VERSION "HNNBNNNYNNNNNNNNNNNNNNNNNNNNNNNNNNNNNNNNNN/4/%%%/4/'%**4NNN///"

NS_ :

BS_:

BU_: BAP_Tester BCM1 Gateway Klima_MSB Lift_VA VAS_L VAS_R

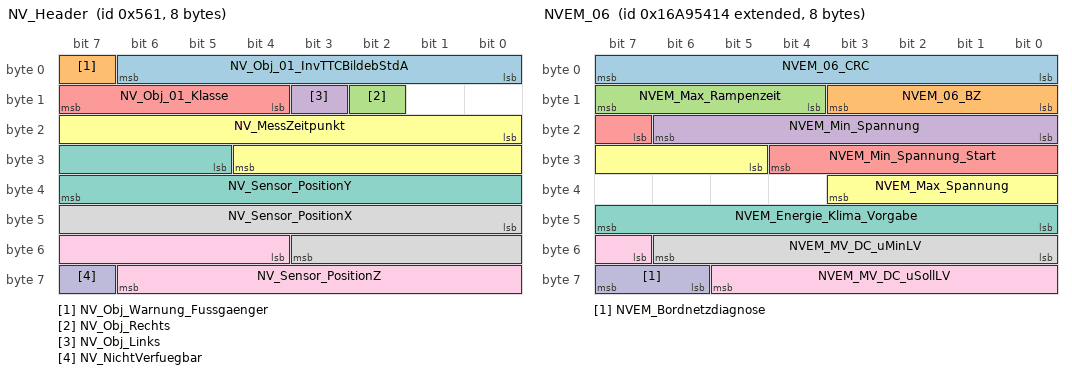
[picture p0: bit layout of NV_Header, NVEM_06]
BO_ 1377 NV_Header: 8 Gateway
 SG_ NV_Obj_01_InvTTCBildebStdA : 0|7@1+ (0.0625,0) [0.0000|7.8750] "Unit_Hertz"  Vector__XXX
 SG_ NV_Obj_Warnung_Fussgaenger : 7|1@1+ (1.0,0.0) [0.0|1] ""  Vector__XXX
 SG_ NV_Obj_Rechts : 10|1@1+ (1.0,0.0) [0.0|1] ""  BCM1
 SG_ NV_Obj_Links : 11|1@1+ (1.0,0.0) [0.0|1] ""  BCM1
 SG_ NV_Obj_01_Klasse : 12|4@1+ (1.0,0.0) [0.0|15] ""  BCM1
 SG_ NV_MessZeitpunkt : 16|13@1+ (0.001,0) [0.000|8.190] "Unit_Secon"  Vector__XXX
 SG_ NV_Sensor_PositionY : 29|11@1+ (0.001,-1) [-1.000|1.046] "Unit_Meter"  Vector__XXX
 SG_ NV_Sensor_PositionX : 40|12@1+ (0.001,1) [1.000|5.094] "Unit_Meter"  Vector__XXX
 SG_ NV_Sensor_PositionZ : 52|11@1+ (0.001,0) [0.000|2.046] "Unit_Meter"  Vector__XXX
 SG_ NV_NichtVerfuegbar : 63|1@1+ (1.0,0.0) [0.0|1] ""  Vector__XXX

BO_ 1635 NVEM_02: 8 Gateway
 SG_ BEM_02_Abschaltstufen : 0|3@1+ (1.0,0.0) [0.0|7] ""  BCM1,Klima_MSB
 SG_ BEM_STH_Zielzeit : 3|4@1+ (5,0) [0|60] "Unit_Minut"  BCM1,Klima_MSB
 SG_ BEM_MMI_Vorwarnung : 7|1@1+ (1.0,0.0) [0.0|1] ""  Vector__XXX
 SG_ NVEM_Anf_SD_schalten : 15|1@1+ (1.0,0.0) [0.0|1] ""  BCM1
 SG_ BEM_Generatordiagnose : 16|2@1+ (1.0,0.0) [0.0|3] ""  Vector__XXX
 SG_ BEM_Red_Innengeblaese : 18|2@1+ (1.0,0.0) [0.0|3] ""  BCM1,Klima_MSB
 SG_ BEM_STH_Einschaltverbot : 20|1@1+ (1.0,0.0) [0.0|1] ""  BCM1,Klima_MSB
 SG_ BEM_HL_Regelung_Status : 21|3@1+ (1.0,0.0) [0.0|7] ""  BCM1,Klima_MSB,Lift_VA
 SG_ BEM_Ladezustand : 24|4@1+ (10,0) [0|100] "Unit_PerCent"  Vector__XXX
 SG_ BEM_Batteriediagnose : 28|3@1+ (1.0,0.0) [0.0|7] ""  Vector__XXX
 SG_ MIB_Stromsparmodus : 31|1@1+ (1.0,0.0) [0.0|1] ""  Vector__XXX
 SG_ BEM_REK_aktiv : 37|1@1+ (1.0,0.0) [0.0|1] ""  Vector__XXX
 SG_ NVEM_Last_Anf : 38|2@1+ (1.0,0.0) [0.0|3] ""  Vector__XXX
 SG_ BEM_UBDM : 40|8@1+ (0.05,5) [5.05|17.70] "Unit_Volt"  Klima_MSB
 SG_ BEM_UGenSoll : 48|6@1+ (0.1,10.6) [10.6|16.0] "Unit_Volt"  Vector__XXX
 SG_ BEM_Anf_KL15_schalten : 54|2@1+ (1.0,0.0) [0.0|3] ""  Vector__XXX
 SG_ NVEM_Batterie_Service : 56|2@1+ (1.0,0.0) [0.0|3] ""  Vector__XXX
 SG_ NVEM_Freigabe_OnlineUpdate : 58|1@1+ (1.0,0.0) [0.0|1] ""  Vector__XXX
 SG_ NVEM_Freigabe_ORU4 : 59|2@1+ (1.0,0.0) [0.0|3] ""  Vector__XXX

BO_ 2527679508 NVEM_06: 8 Gateway
 SG_ NVEM_06_CRC : 0|8@1+ (1,0) [0|255] ""  Vector__XXX
 SG_ NVEM_06_BZ : 8|4@1+ (1,0) [0|15] ""  Vector__XXX
 SG_ NVEM_Max_Rampenzeit : 12|4@1+ (1.0,0.0) [0.0|15] ""  Vector__XXX
 SG_ NVEM_Min_Spannung : 16|7@1+ (0.05,10.6) [10.60|16.00] "Unit_Volt"  Vector__XXX
 SG_ NVEM_Min_Spannung_Start : 23|6@1+ (0.1,7) [7.0|13.1] "Unit_Volt"  Vector__XXX
 SG_ NVEM_Max_Spannung : 29|7@1+ (0.05,10.6) [10.60|16.00] "Unit_Volt"  Vector__XXX
 SG_ NVEM_Energie_Klima_Vorgabe : 40|8@1+ (10,0) [0|2530] "Unit_WattHour"  BCM1,Klima_MSB
 SG_ NVEM_MV_DC_uMinLV : 48|7@1+ (0.1,3.5) [3.5|16.0] "Unit_Volt"  Vector__XXX
 SG_ NVEM_MV_DC_uSollLV : 55|7@1+ (0.05,10.6) [10.60|16.00] "Unit_Volt"  Vector__XXX
 SG_ NVEM_Bordnetzdiagnose : 62|2@1+ (1.0,0.0) [0.0|3] ""  Vector__XXX

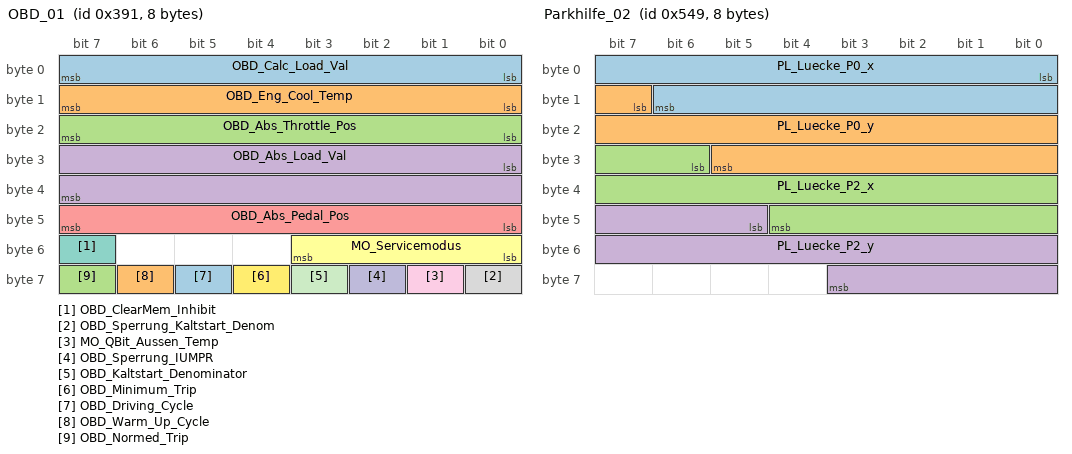
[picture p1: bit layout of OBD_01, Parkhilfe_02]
BO_ 913 OBD_01: 8 Gateway
 SG_ OBD_Calc_Load_Val : 0|8@1+ (0.39215686274509803,0) [0E-17|99.99999999999999765] "Unit_PerCent"  Vector__XXX
 SG_ OBD_Eng_Cool_Temp : 8|8@1+ (1,-40) [-40|215] "Unit_DegreCelsi"  Vector__XXX
 SG_ OBD_Abs_Throttle_Pos : 16|8@1+ (0.39215686274509803,0) [0E-17|99.99999999999999765] "Unit_PerCent"  Vector__XXX
 SG_ OBD_Abs_Load_Val : 24|16@1+ (0.39215686274509803,0) [0E-17|25699.99999999999939605] "Unit_PerCent"  Vector__XXX
 SG_ OBD_Abs_Pedal_Pos : 40|8@1+ (0.39215686274509803,0) [0E-17|99.99999999999999765] "Unit_PerCent"  Vector__XXX
 SG_ MO_Servicemodus : 48|4@1+ (1.0,0.0) [0.0|15] ""  Vector__XXX
 SG_ OBD_ClearMem_Inhibit : 55|1@1+ (1.0,0.0) [0.0|1] ""  Vector__XXX
 SG_ OBD_Sperrung_Kaltstart_Denom : 56|1@1+ (1.0,0.0) [0.0|1] ""  Vector__XXX
 SG_ MO_QBit_Aussen_Temp : 57|1@1+ (1.0,0.0) [0.0|1] ""  Vector__XXX
 SG_ OBD_Sperrung_IUMPR : 58|1@1+ (1.0,0.0) [0.0|1] ""  Vector__XXX
 SG_ OBD_Kaltstart_Denominator : 59|1@1+ (1.0,0.0) [0.0|1] ""  Vector__XXX
 SG_ OBD_Minimum_Trip : 60|1@1+ (1.0,0.0) [0.0|1] ""  Vector__XXX
 SG_ OBD_Driving_Cycle : 61|1@1+ (1.0,0.0) [0.0|1] ""  Vector__XXX
 SG_ OBD_Warm_Up_Cycle : 62|1@1+ (1.0,0.0) [0.0|1] ""  Lift_VA
 SG_ OBD_Normed_Trip : 63|1@1+ (1.0,0.0) [0.0|1] ""  Vector__XXX

BO_ 2549875214 OBDC_BCM1_Req: 8 Gateway
 SG_ OBDC_BCM1_Req_Data : 0|64@1+ (1.0,0.0) [0.0|18446744073709551615] ""  BCM1

BO_ 2550006286 OBDC_BCM1_Resp: 8 BCM1
 SG_ OBDC_BCM1_Resp_Data : 0|64@1+ (1.0,0.0) [0.0|18446744073709551615] ""  Gateway

BO_ 2549940736 OBDC_Funktionaler_Req_All: 8 Gateway
 SG_ OBDC_Funktionaler_Req_All_Data : 0|64@1+ (1.0,0.0) [0.0|18446744073709551615] ""  BCM1,Klima_MSB,Lift_VA,VAS_L,VAS_R

BO_ 2549875270 OBDC_Klima_Req: 8 Gateway
 SG_ OBDC_Klima_Req_Data : 0|64@1+ (1.0,0.0) [0.0|18446744073709551615] ""  Klima_MSB

BO_ 2550006342 OBDC_Klima_Resp: 8 Klima_MSB
 SG_ OBDC_Klima_Resp_Data : 0|64@1+ (1.0,0.0) [0.0|18446744073709551615] ""  Gateway

BO_ 2549875330 OBDC_LCM_L_Req: 8 Gateway
 SG_ OBDC_LCM_L_Req_Data : 0|64@1+ (1.0,0.0) [0.0|18446744073709551615] ""  BCM1

BO_ 2550006402 OBDC_LCM_L_Resp: 8 BCM1
 SG_ OBDC_LCM_L_Resp_Data : 0|64@1+ (1.0,0.0) [0.0|18446744073709551615] ""  Gateway

BO_ 2549875331 OBDC_LCM_R_Req: 8 Gateway
 SG_ OBDC_LCM_R_Req_Data : 0|64@1+ (1.0,0.0) [0.0|18446744073709551615] ""  BCM1

BO_ 2550006403 OBDC_LCM_R_Resp: 8 BCM1
 SG_ OBDC_LCM_R_Resp_Data : 0|64@1+ (1.0,0.0) [0.0|18446744073709551615] ""  Gateway

BO_ 2549875350 OBDC_LED_LM_L_Req: 8 Gateway
 SG_ OBDC_LED_LM_L_Req_Data : 0|64@1+ (1.0,0.0) [0.0|18446744073709551615] ""  BCM1

BO_ 2550006422 OBDC_LED_LM_L_Resp: 8 BCM1
 SG_ OBDC_LED_LM_L_Resp_Data : 0|64@1+ (1.0,0.0) [0.0|18446744073709551615] ""  Gateway

BO_ 2549875351 OBDC_LED_LM_R_Req: 8 Gateway
 SG_ OBDC_LED_LM_R_Req_Data : 0|64@1+ (1.0,0.0) [0.0|18446744073709551615] ""  BCM1

BO_ 2550006423 OBDC_LED_LM_R_Resp: 8 BCM1
 SG_ OBDC_LED_LM_R_Resp_Data : 0|64@1+ (1.0,0.0) [0.0|18446744073709551615] ""  Gateway

BO_ 2549875289 OBDC_Lift_Req: 8 Gateway
 SG_ OBDC_Lift_Req_Data : 0|64@1+ (1,0) [0|18446744073709551615] "Unit_None"  Lift_VA

BO_ 2550006361 OBDC_Lift_Resp: 8 Lift_VA
 SG_ OBDC_Lift_Resp_Data : 0|64@1+ (1.0,0.0) [0.0|18446744073709551615] ""  Gateway

BO_ 2549875396 OBDC_VAS_L_Req: 8 Gateway
 SG_ OBDC_VAS_L_Req_Data : 0|64@1+ (1,0) [0|18446744073709551615] "Unit_None"  VAS_L

BO_ 2550006468 OBDC_VAS_L_Resp: 8 VAS_L
 SG_ OBDC_VAS_L_Resp_Data : 0|64@1+ (1,0) [0|18446744073709551615] "Unit_None"  Gateway

BO_ 2549875397 OBDC_VAS_R_Req: 8 Gateway
 SG_ OBDC_VAS_R_Req_Data : 0|64@1+ (1,0) [0|18446744073709551615] "Unit_None"  VAS_R

BO_ 2550006469 OBDC_VAS_R_Resp: 8 VAS_R
 SG_ OBDC_VAS_R_Resp_Data : 0|64@1+ (1,0) [0|18446744073709551615] "Unit_None"  Gateway

BO_ 2589283656 ORU_01: 8 Gateway
 SG_ ORU_Status : 61|3@1+ (1.0,0.0) [0.0|7] ""  BCM1

BO_ 872 Parkhilfe2_01: 8 Gateway
 SG_ PH2_Visualisierung : 0|3@1+ (1.0,0.0) [0.0|7] ""  BCM1
 SG_ PDC2_Tonausgabe_Front : 4|4@1+ (1.0,0.0) [0.0|15] ""  Vector__XXX
 SG_ PDC2_Tonausgabe_Heck : 8|4@1+ (1.0,0.0) [0.0|15] ""  Vector__XXX
 SG_ PH2_nachtr_Stopp_An : 12|1@1+ (1.0,0.0) [0.0|1] ""  Vector__XXX
 SG_ PH2_Abschaltursache : 13|3@1+ (1.0,0.0) [0.0|7] ""  BCM1
 SG_ PH2_Opt_Anzeige_V_ein : 16|1@1+ (1.0,0.0) [0.0|1] ""  BCM1
 SG_ PH2_Opt_Anzeige_H_ein : 17|1@1+ (1.0,0.0) [0.0|1] ""  BCM1
 SG_ PH2_Opt_Anz_V_Hindernis : 18|1@1+ (1.0,0.0) [0.0|1] ""  BCM1
 SG_ PH2_Opt_Anz_H_Hindernis : 19|1@1+ (1.0,0.0) [0.0|1] ""  BCM1
 SG_ PH2_Tongeber_V_aktiv : 20|1@1+ (1.0,0.0) [0.0|1] ""  Vector__XXX
 SG_ PH2_Tongeber_H_aktiv : 21|1@1+ (1.0,0.0) [0.0|1] ""  Vector__XXX
 SG_ PH2_Tongeber_mute : 22|1@1+ (1.0,0.0) [0.0|1] ""  Vector__XXX
 SG_ PH2_Anf_Audioabsenkung : 23|1@1+ (1.0,0.0) [0.0|1] ""  Vector__XXX
 SG_ PH2_Tongeber_H_verfuegbar : 24|1@1+ (1.0,0.0) [0.0|1] ""  Vector__XXX
 SG_ PH2_Taster : 28|2@1+ (1.0,0.0) [0.0|3] ""  Vector__XXX
 SG_ PH2_Anf_Verdeck : 30|2@1+ (1.0,0.0) [0.0|3] ""  Vector__XXX
 SG_ PH2_Frequenz_hinten : 32|4@1+ (1,0) [0|15] ""  Vector__XXX
 SG_ PH2_Lautstaerke_hinten : 36|4@1+ (1,0) [0|15] ""  Vector__XXX
 SG_ PH2_Frequenz_vorn : 40|4@1+ (1,0) [0|15] ""  Vector__XXX
 SG_ PH2_Lautstaerke_vorn : 44|4@1+ (1,0) [0|15] ""  Vector__XXX
 SG_ PH2_StartStopp_Info : 49|2@1+ (1.0,0.0) [0.0|3] ""  Vector__XXX
 SG_ PH2_Stoermeldung : 52|4@1+ (1.0,0.0) [0.0|15] ""  Vector__XXX
 SG_ PH2_defekt : 56|1@1+ (1.0,0.0) [0.0|1] ""  Vector__XXX
 SG_ PH2_gestoert : 57|1@1+ (1.0,0.0) [0.0|1] ""  Vector__XXX
 SG_ PH2_Systemzustand : 58|3@1+ (1.0,0.0) [0.0|7] ""  BCM1
 SG_ PH2_Display_Kundenwunsch : 61|2@1+ (1.0,0.0) [0.0|3] ""  Vector__XXX

BO_ 1175 Parkhilfe_01: 8 BCM1
 SG_ PH_Visualisierung : 0|3@1+ (1.0,0.0) [0.0|7] ""  Gateway
 SG_ PDC_Tonausgabe_Front : 4|4@1+ (1.0,0.0) [0.0|15] ""  Gateway
 SG_ PDC_Tonausgabe_Heck : 8|4@1+ (1.0,0.0) [0.0|15] ""  Gateway
 SG_ PH_nachtr_Stopp_Anf : 12|1@1+ (1.0,0.0) [0.0|1] ""  Gateway
 SG_ PH_Abschaltursache : 13|3@1+ (1.0,0.0) [0.0|7] ""  Gateway
 SG_ PH_Opt_Anzeige_V_ein : 16|1@1+ (1.0,0.0) [0.0|1] ""  Gateway
 SG_ PH_Opt_Anzeige_H_ein : 17|1@1+ (1.0,0.0) [0.0|1] ""  Gateway
 SG_ PH_Opt_Anz_V_Hindernis : 18|1@1+ (1.0,0.0) [0.0|1] ""  Gateway
 SG_ PH_Opt_Anz_H_Hindernis : 19|1@1+ (1.0,0.0) [0.0|1] ""  Gateway
 SG_ PH_Tongeber_V_aktiv : 20|1@1+ (1.0,0.0) [0.0|1] ""  Gateway
 SG_ PH_Tongeber_H_aktiv : 21|1@1+ (1.0,0.0) [0.0|1] ""  Gateway
 SG_ PH_Tongeber_mute : 22|1@1+ (1.0,0.0) [0.0|1] ""  Gateway
 SG_ PH_Anf_Audioabsenkung : 23|1@1+ (1.0,0.0) [0.0|1] ""  Gateway
 SG_ PH_Tongeber_H_verfuegbar : 24|1@1+ (1.0,0.0) [0.0|1] ""  Gateway
 SG_ PLA_Anf_Aufschaltung_RVC : 25|1@1+ (1.0,0.0) [0.0|1] ""  Gateway
 SG_ PH_Taster : 28|2@1+ (1.0,0.0) [0.0|3] ""  Gateway
 SG_ PH_Anf_Verdeck : 30|2@1+ (1.0,0.0) [0.0|3] ""  Gateway
 SG_ PH_Frequenz_hinten : 32|4@1+ (1,0) [0|15] ""  Gateway
 SG_ PH_Lautstaerke_hinten : 36|4@1+ (1,0) [0|15] ""  Gateway
 SG_ PH_Frequenz_vorn : 40|4@1+ (1,0) [0|15] ""  Gateway
 SG_ PH_Lautstaerke_vorn : 44|4@1+ (1,0) [0|15] ""  Gateway
 SG_ PH_StartStopp_Info : 49|2@1+ (1.0,0.0) [0.0|3] ""  Gateway
 SG_ PH_Stoermeldung : 52|4@1+ (1.0,0.0) [0.0|15] ""  Gateway
 SG_ PH_defekt : 56|1@1+ (1.0,0.0) [0.0|1] ""  Gateway
 SG_ PH_gestoert : 57|1@1+ (1.0,0.0) [0.0|1] ""  Gateway
 SG_ PH_Systemzustand : 58|3@1+ (1.0,0.0) [0.0|7] ""  Gateway
 SG_ PH_Display_Kundenwunsch : 61|2@1+ (1.0,0.0) [0.0|3] ""  Gateway

BO_ 1353 Parkhilfe_02: 8 BCM1
 SG_ PL_Luecke_P0_x : 0|15@1+ (2,-32767) [-32767|32767] "Unit_Centimeter"  Gateway
 SG_ PL_Luecke_P0_y : 15|15@1+ (2,-32767) [-32767|32767] "Unit_Centimeter"  Gateway
 SG_ PL_Luecke_P2_x : 30|15@1+ (2,-32767) [-32767|32767] "Unit_Centimeter"  Gateway
 SG_ PL_Luecke_P2_y : 45|15@1+ (2,-32767) [-32767|32767] "Unit_Centimeter"  Gateway

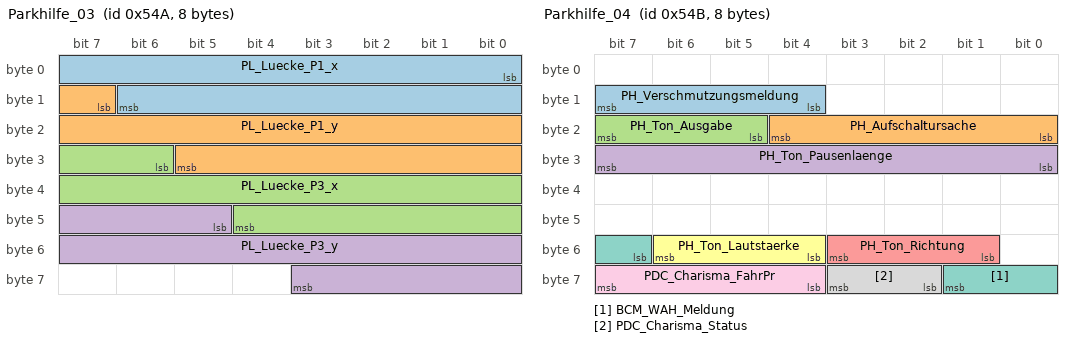
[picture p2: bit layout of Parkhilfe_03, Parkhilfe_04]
BO_ 1354 Parkhilfe_03: 8 BCM1
 SG_ PL_Luecke_P1_x : 0|15@1+ (2,-32767) [-32767|32767] "Unit_Centimeter"  Gateway
 SG_ PL_Luecke_P1_y : 15|15@1+ (2,-32767) [-32767|32767] "Unit_Centimeter"  Gateway
 SG_ PL_Luecke_P3_x : 30|15@1+ (2,-32767) [-32767|32767] "Unit_Centimeter"  Gateway
 SG_ PL_Luecke_P3_y : 45|15@1+ (2,-32767) [-32767|32767] "Unit_Centimeter"  Gateway

BO_ 1355 Parkhilfe_04: 8 BCM1
 SG_ PH_Verschmutzungsmeldung : 12|4@1+ (1.0,0.0) [0.0|15] ""  Gateway
 SG_ PH_Aufschaltursache : 16|5@1+ (1.0,0.0) [0.0|31] ""  Gateway
 SG_ PH_Ton_Ausgabe : 21|3@1+ (1.0,0.0) [0.0|7] ""  Gateway
 SG_ PH_Ton_Pausenlaenge : 24|8@1+ (1.0,0.0) [0.0|255] ""  Gateway
 SG_ PH_Ton_Richtung : 49|3@1+ (1.0,0.0) [0.0|7] ""  Gateway
 SG_ PH_Ton_Lautstaerke : 52|3@1+ (1.0,0.0) [0.0|7] ""  Gateway
 SG_ BCM_WAH_Meldung : 55|3@1+ (1.0,0.0) [0.0|7] ""  Gateway
 SG_ PDC_Charisma_Status : 58|2@1+ (1.0,0.0) [0.0|3] ""  Gateway
 SG_ PDC_Charisma_FahrPr : 60|4@1+ (1.0,0.0) [0.0|15] ""  Gateway

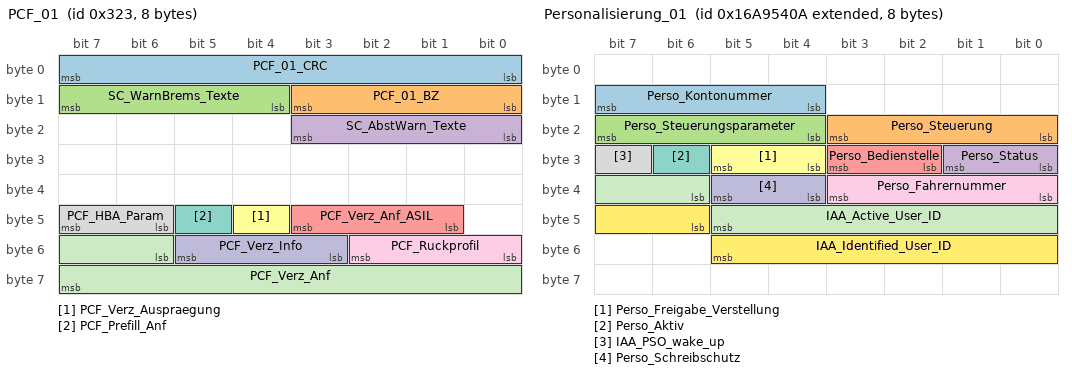
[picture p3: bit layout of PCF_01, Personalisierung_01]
BO_ 803 PCF_01: 8 Gateway
 SG_ PCF_01_CRC : 0|8@1+ (1,0) [0|255] ""  Vector__XXX
 SG_ PCF_01_BZ : 8|4@1+ (1,0) [0|15] ""  Vector__XXX
 SG_ SC_WarnBrems_Texte : 12|4@1+ (1.0,0.0) [0.0|15] ""  Vector__XXX
 SG_ SC_AbstWarn_Texte : 16|4@1+ (1.0,0.0) [0.0|15] ""  Vector__XXX
 SG_ PCF_Verz_Anf_ASIL : 41|3@1+ (1.0,0.0) [0.0|7] ""  Vector__XXX
 SG_ PCF_Verz_Auspraegung : 44|1@1+ (1.0,0.0) [0.0|1] ""  Vector__XXX
 SG_ PCF_Prefill_Anf : 45|1@1+ (1.0,0.0) [0.0|1] ""  BCM1
 SG_ PCF_HBA_Param : 46|2@1+ (1.0,0.0) [0.0|3] ""  Vector__XXX
 SG_ PCF_Ruckprofil : 48|3@1+ (1.0,0.0) [0.0|7] ""  Vector__XXX
 SG_ PCF_Verz_Info : 51|3@1+ (1.0,0.0) [0.0|7] ""  BCM1
 SG_ PCF_Verz_Anf : 54|10@1+ (0.024,-20.016) [-20.016|4.536] "Unit_MeterPerSeconSquar"  Vector__XXX

BO_ 2527679498 Personalisierung_01: 8 Gateway
 SG_ Perso_Kontonummer : 12|4@1+ (1.0,0.0) [0.0|15] ""  BCM1,Klima_MSB,VAS_L,VAS_R
 SG_ Perso_Steuerung : 16|4@1+ (1.0,0.0) [0.0|15] ""  BCM1,Klima_MSB,VAS_L,VAS_R
 SG_ Perso_Steuerungsparameter : 20|4@1+ (1.0,0.0) [0.0|15] ""  BCM1,Klima_MSB,VAS_L,VAS_R
 SG_ Perso_Status : 24|2@1+ (1.0,0.0) [0.0|3] ""  BCM1,Klima_MSB,VAS_L,VAS_R
 SG_ Perso_Bedienstelle : 26|2@1+ (1.0,0.0) [0.0|3] ""  VAS_L,VAS_R
 SG_ Perso_Freigabe_Verstellung : 28|2@1+ (1.0,0.0) [0.0|3] ""  VAS_L,VAS_R
 SG_ Perso_Aktiv : 30|1@1+ (1.0,0.0) [0.0|1] ""  VAS_L,VAS_R
 SG_ IAA_PSO_wake_up : 31|1@1+ (1.0,0.0) [0.0|1] ""  Vector__XXX
 SG_ Perso_Fahrernummer : 32|4@1+ (1.0,0.0) [0.0|15] ""  Vector__XXX
 SG_ Perso_Schreibschutz : 36|2@1+ (1.0,0.0) [0.0|3] ""  Vector__XXX
 SG_ IAA_Active_User_ID : 38|8@1+ (1,0) [0|255] "Unit_None"  Vector__XXX
 SG_ IAA_Identified_User_ID : 46|8@1+ (1,0) [0|255] "Unit_None"  Vector__XXX

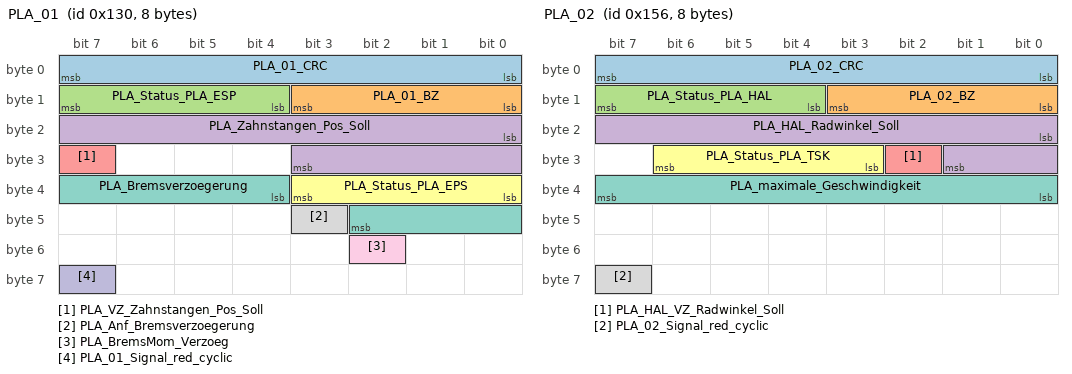
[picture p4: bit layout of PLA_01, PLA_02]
BO_ 304 PLA_01: 8 BCM1
 SG_ PLA_01_CRC : 0|8@1+ (1,0) [0|255] ""  Gateway
 SG_ PLA_01_BZ : 8|4@1+ (1,0) [0|15] ""  Gateway
 SG_ PLA_Status_PLA_ESP : 12|4@1+ (1.0,0.0) [0.0|15] ""  Gateway
 SG_ PLA_Zahnstangen_Pos_Soll : 16|12@1+ (0.02,0) [0.00|81.86] "Unit_MilliMeter"  Gateway
 SG_ PLA_VZ_Zahnstangen_Pos_Soll : 31|1@1+ (1.0,0.0) [0.0|1] ""  Gateway
 SG_ PLA_Status_PLA_EPS : 32|4@1+ (1.0,0.0) [0.0|15] ""  Gateway
 SG_ PLA_Bremsverzoegerung : 36|7@1+ (0.1,0) [0.0|12.0] "Unit_MeterPerSeconSquar"  Gateway
 SG_ PLA_Anf_Bremsverzoegerung : 43|1@1+ (1.0,0.0) [0.0|1] ""  Gateway
 SG_ PLA_BremsMom_Verzoeg : 50|1@1+ (1.0,0.0) [0.0|1] ""  Gateway
 SG_ PLA_01_Signal_red_cyclic : 63|1@1+ (1.0,0.0) [0.0|1] ""  Gateway

BO_ 342 PLA_02: 8 BCM1
 SG_ PLA_02_CRC : 0|8@1+ (1,0) [0|255] ""  Gateway
 SG_ PLA_02_BZ : 8|4@1+ (1,0) [0|15] ""  Gateway
 SG_ PLA_Status_PLA_HAL : 12|4@1+ (1.0,0.0) [0.0|15] ""  Gateway
 SG_ PLA_HAL_Radwinkel_Soll : 16|10@1+ (0.01,0) [0.00|10.19] "Unit_DegreOfArc"  Gateway
 SG_ PLA_HAL_VZ_Radwinkel_Soll : 26|1@1+ (1.0,0.0) [0.0|1] ""  Gateway
 SG_ PLA_Status_PLA_TSK : 27|4@1+ (1.0,0.0) [0.0|15] ""  Gateway
 SG_ PLA_maximale_Geschwindigkeit : 32|8@1+ (0.1,0) [0.1|25.0] "Unit_KiloMeterPerHour"  Gateway
 SG_ PLA_02_Signal_red_cyclic : 63|1@1+ (1.0,0.0) [0.0|1] ""  Gateway

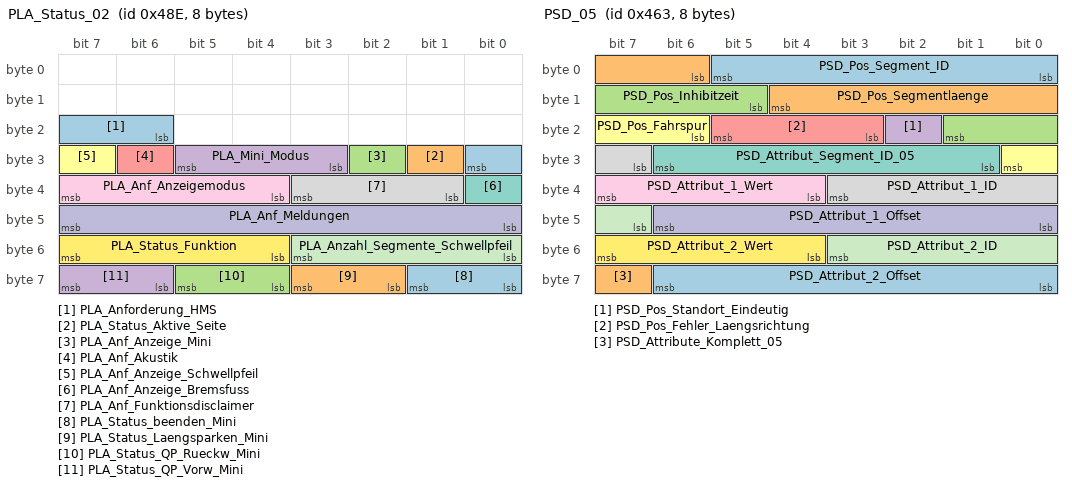
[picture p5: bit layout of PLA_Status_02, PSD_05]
BO_ 1166 PLA_Status_02: 8 BCM1
 SG_ PLA_Anforderung_HMS : 22|3@1+ (1.0,0.0) [0.0|7] ""  Gateway
 SG_ PLA_Status_Aktive_Seite : 25|1@1+ (1.0,0.0) [0.0|1] ""  Gateway
 SG_ PLA_Anf_Anzeige_Mini : 26|1@1+ (1.0,0.0) [0.0|1] ""  Gateway
 SG_ PLA_Mini_Modus : 27|3@1+ (1.0,0.0) [0.0|7] ""  Gateway
 SG_ PLA_Anf_Akustik : 30|1@1+ (1.0,0.0) [0.0|1] ""  Gateway
 SG_ PLA_Anf_Anzeige_Schwellpfeil : 31|1@1+ (1.0,0.0) [0.0|1] ""  Gateway
 SG_ PLA_Anf_Anzeige_Bremsfuss : 32|1@1+ (1.0,0.0) [0.0|1] ""  Gateway
 SG_ PLA_Anf_Funktionsdisclaimer : 33|3@1+ (1.0,0.0) [0.0|7] ""  Gateway
 SG_ PLA_Anf_Anzeigemodus : 36|4@1+ (1.0,0.0) [0.0|15] ""  Gateway
 SG_ PLA_Anf_Meldungen : 40|8@1+ (1.0,0.0) [0.0|255] ""  Gateway
 SG_ PLA_Anzahl_Segmente_Schwellpfeil : 48|4@1+ (1,0) [0|15] "Unit_None"  Gateway
 SG_ PLA_Status_Funktion : 52|4@1+ (1.0,0.0) [0.0|15] ""  Gateway
 SG_ PLA_Status_beenden_Mini : 56|2@1+ (1.0,0.0) [0.0|3] ""  Gateway
 SG_ PLA_Status_Laengsparken_Mini : 58|2@1+ (1.0,0.0) [0.0|3] ""  Gateway
 SG_ PLA_Status_QP_Rueckw_Mini : 60|2@1+ (1.0,0.0) [0.0|3] ""  Gateway
 SG_ PLA_Status_QP_Vorw_Mini : 62|2@1+ (1.0,0.0) [0.0|3] ""  Gateway

BO_ 319 PreCrash_02: 8 Gateway
 SG_ PreCrash_02_CRC : 0|8@1+ (1,0) [0|255] ""  Vector__XXX
 SG_ PreCrash_02_BZ : 8|4@1+ (1,0) [0|15] ""  Vector__XXX
 SG_ PreCrash_Charisma_FahrPr : 12|4@1+ (1.0,0.0) [0.0|15] ""  Vector__XXX
 SG_ PreCrash_Charisma_Status : 16|2@1+ (1.0,0.0) [0.0|3] ""  Vector__XXX
 SG_ PreCrash_Schiebedach_schliessen : 18|1@1+ (1.0,0.0) [0.0|1] ""  Vector__XXX
 SG_ PreCrash_Fenster_schliessen : 19|1@1+ (1.0,0.0) [0.0|1] ""  Vector__XXX
 SG_ PreCrash_Blinken : 20|3@1+ (1.0,0.0) [0.0|7] ""  Vector__XXX
 SG_ SC_PreSense_FCWP : 23|1@1+ (1.0,0.0) [0.0|1] ""  Vector__XXX
 SG_ PreCrash_Tueren_Verriegeln : 24|1@1+ (1.0,0.0) [0.0|1] ""  Vector__XXX
 SG_ PreCrash_Anforderung_AFR : 26|3@1+ (1.0,0.0) [0.0|7] ""  Vector__XXX
 SG_ SC_PreCrash_LED : 29|2@1+ (1.0,0.0) [0.0|3] ""  Vector__XXX
 SG_ PreCrash_FS_Pneumatik_ansteuern : 31|1@1+ (1.0,0.0) [0.0|1] ""  BCM1
 SG_ PreCrash_BFS_Pneumatik_ansteuern : 32|1@1+ (1.0,0.0) [0.0|1] ""  BCM1
 SG_ PreCrash_Fo_Pneumatik_ansteuern : 33|1@1+ (1.0,0.0) [0.0|1] ""  Vector__XXX
 SG_ PreCrash_FS_Sitzlehne_verfahren : 34|3@1+ (1.0,0.0) [0.0|7] ""  Vector__XXX
 SG_ PreCrash_BFS_Sitzlehne_verfahren : 37|3@1+ (1.0,0.0) [0.0|7] ""  Vector__XXX
 SG_ PreCrash_Fo_Sitzlehne_verfahren : 40|3@1+ (1.0,0.0) [0.0|7] ""  Vector__XXX
 SG_ PreCrash_FS_KSV_verfahren : 43|4@1+ (1.0,0.0) [0.0|15] ""  Vector__XXX
 SG_ PreCrash_BFS_KSV_verfahren : 47|4@1+ (1.0,0.0) [0.0|15] ""  Vector__XXX
 SG_ PreCrash_Fo_KSV_verfahren : 51|4@1+ (1.0,0.0) [0.0|15] ""  Vector__XXX
 SG_ SC_PreCrash_Warnung : 56|4@1+ (1.0,0.0) [0.0|15] ""  Vector__XXX
 SG_ SC_PreCrash_Texte : 60|4@1+ (1.0,0.0) [0.0|15] ""  Vector__XXX

BO_ 1122 PSD_04: 8 Gateway
 SG_ PSD_Segment_ID : 0|6@1+ (1,0) [2|63] ""  BCM1,VAS_L,VAS_R
 SG_ PSD_Vorgaenger_Segment_ID : 6|6@1+ (1,0) [2|63] ""  BCM1,VAS_L,VAS_R
 SG_ PSD_Segmentlaenge : 12|7@1+ (2,0) [0|254] "Unit_Meter"  BCM1,VAS_L,VAS_R
 SG_ PSD_Strassenkategorie : 19|3@1+ (1.0,0.0) [0.0|7] ""  BCM1,VAS_L,VAS_R
 SG_ PSD_Endkruemmung : 22|8@1+ (1,0) [0|254] "Unit_None"  BCM1,VAS_L,VAS_R
 SG_ PSD_Endkruemmung_Vorz : 30|1@1+ (1.0,0.0) [0.0|1] ""  BCM1,VAS_L,VAS_R
 SG_ PSD_Idenditaets_ID : 31|6@1+ (1,0) [2|63] ""  BCM1,VAS_L,VAS_R
 SG_ PSD_ADAS_Qualitaet : 37|1@1+ (1.0,0.0) [0.0|1] ""  BCM1,VAS_L,VAS_R
 SG_ PSD_wahrscheinlichster_Pfad : 38|1@1+ (1.0,0.0) [0.0|1] ""  BCM1,VAS_L,VAS_R
 SG_ PSD_Geradester_Pfad : 39|1@1+ (1.0,0.0) [0.0|1] ""  BCM1,VAS_L,VAS_R
 SG_ PSD_Fahrspuren_Anzahl : 40|3@1+ (1.0,0.0) [0.0|7] ""  BCM1,VAS_L,VAS_R
 SG_ PSD_Bebauung : 43|1@1+ (1.0,0.0) [0.0|1] ""  BCM1,VAS_L,VAS_R
 SG_ PSD_Segment_Komplett : 44|1@1+ (1.0,0.0) [0.0|1] ""  BCM1,VAS_L,VAS_R
 SG_ PSD_Rampe : 45|2@1+ (1.0,0.0) [0.0|3] ""  BCM1,VAS_L,VAS_R
 SG_ PSD_Anfangskruemmung : 47|8@1+ (1,0) [0|254] ""  BCM1,VAS_L,VAS_R
 SG_ PSD_Anfangskruemmung_Vorz : 55|1@1+ (1.0,0.0) [0.0|1] ""  BCM1,VAS_L,VAS_R
 SG_ PSD_Abzweigerichtung : 56|1@1+ (1.0,0.0) [0.0|1] ""  BCM1,VAS_L,VAS_R
 SG_ PSD_Abzweigewinkel : 57|7@1+ (1.417323,0) [0.000000|180.000021] ""  BCM1,VAS_L,VAS_R

BO_ 1123 PSD_05: 8 Gateway
 SG_ PSD_Pos_Segment_ID : 0|6@1+ (1,0) [2|63] ""  BCM1,VAS_L,VAS_R
 SG_ PSD_Pos_Segmentlaenge : 6|7@1+ (2,0) [0|254] "Unit_Meter"  BCM1,VAS_L,VAS_R
 SG_ PSD_Pos_Inhibitzeit : 13|5@1+ (10,0) [0|310] "Unit_MilliSecon"  BCM1,VAS_L,VAS_R
 SG_ PSD_Pos_Standort_Eindeutig : 18|1@1+ (1.0,0.0) [0.0|1] ""  BCM1,VAS_L,VAS_R
 SG_ PSD_Pos_Fehler_Laengsrichtung : 19|3@1+ (1.0,0.0) [0.0|7] ""  BCM1,VAS_L,VAS_R
 SG_ PSD_Pos_Fahrspur : 22|3@1+ (1.0,0.0) [0.0|7] ""  BCM1,VAS_L,VAS_R
 SG_ PSD_Attribut_Segment_ID_05 : 25|6@1+ (1,0) [2|63] ""  BCM1,VAS_L,VAS_R
 SG_ PSD_Attribut_1_ID : 31|5@1+ (1,0) [1|31] ""  BCM1,VAS_L,VAS_R
 SG_ PSD_Attribut_1_Wert : 36|4@1+ (1.0,0.0) [0.0|15] ""  BCM1,VAS_L,VAS_R
 SG_ PSD_Attribut_1_Offset : 40|7@1+ (2,0) [0|254] "Unit_Meter"  BCM1,VAS_L,VAS_R
 SG_ PSD_Attribut_2_ID : 47|5@1+ (1,0) [1|31] ""  BCM1,VAS_L,VAS_R
 SG_ PSD_Attribut_2_Wert : 52|4@1+ (1.0,0.0) [0.0|15] ""  BCM1,VAS_L,VAS_R
 SG_ PSD_Attribut_2_Offset : 56|7@1+ (2,0) [0|254] "Unit_Meter"  BCM1,VAS_L,VAS_R
 SG_ PSD_Attribute_Komplett_05 : 63|1@1+ (1.0,0.0) [0.0|1] ""  BCM1,VAS_L,VAS_R

BO_ 1124 PSD_06: 8 Gateway
 SG_ PSD_06_Mux M  : 0|3@1+ (1.0,0.0) [0.0|7] ""  BCM1,VAS_L,VAS_R
 SG_ PSD_Sys_Segment_ID m0  : 3|6@1+ (1,0) [2|63] ""  BCM1,VAS_L,VAS_R
 SG_ PSD_Attribut_Segment_ID m1  : 3|6@1+ (1,0) [2|63] ""  BCM1,VAS_L,VAS_R
 SG_ PSD_Ges_Segment_ID m2  : 3|6@1+ (1,0) [2|63] ""  BCM1
 SG_ PSD_Baum_Laenge_VZ m3  : 3|1@1+ (1.0,0.0) [0.0|1] ""  BCM1,VAS_L,VAS_R
 SG_ PSD_Steigung_1_Segment_ID m4  : 3|6@1+ (1,0) [2|63] ""  BCM1,VAS_L,VAS_R
 SG_ PSD_Baum_Laenge m3  : 4|25@1+ (0.00001,0) [0.00000|180.00000] "Unit_DegreOfArc"  BCM1,VAS_L,VAS_R
 SG_ PSD_Sys_Laendercode m0  : 9|8@1+ (1.0,0.0) [0.0|255] ""  BCM1,VAS_L,VAS_R
 SG_ PSD_Attribut_3_ID m1  : 9|5@1+ (1,0) [1|31] ""  BCM1,VAS_L,VAS_R
 SG_ PSD_Ges_Offset m2  : 9|7@1+ (2,0) [0|254] "Unit_Meter"  BCM1
 SG_ PSD_Steigung_1_A_Steigung m4  : 9|7@1+ (0.12,0) [0.00|15.00] "Unit_PerCent"  BCM1,VAS_L,VAS_R
 SG_ PSD_Attribut_3_Offset m1  : 14|7@1+ (2,0) [0|254] "Unit_Meter"  BCM1,VAS_L,VAS_R
 SG_ PSD_Ges_Geschwindigkeit m2  : 16|5@1+ (1.0,0.0) [0.0|31] ""  BCM1
 SG_ PSD_Steigung_1_A_Vorz m4  : 16|1@1+ (1.0,0.0) [0.0|1] ""  BCM1,VAS_L,VAS_R
 SG_ PSD_Sys_Geschwindigkeit_Einheit m0  : 17|1@1+ (1.0,0.0) [0.0|1] ""  BCM1,VAS_L,VAS_R
 SG_ PSD_Steigung_1_A_Offset m4  : 17|7@1+ (2,0) [0|254] "Unit_Meter"  BCM1,VAS_L,VAS_R
 SG_ PSD_Sys_Verkehrsrichtung m0  : 18|1@1+ (1.0,0.0) [0.0|1] ""  BCM1,VAS_L,VAS_R
 SG_ PSD_Sys_Geometrieguete m0  : 19|2@1+ (1.0,0.0) [0.0|3] ""  BCM1,VAS_L,VAS_R
 SG_ PSD_Sys_Mapmatchingguete m0  : 21|2@1+ (1.0,0.0) [0.0|3] ""  BCM1,VAS_L,VAS_R
 SG_ PSD_Attribut_3_Wert m1  : 21|4@1+ (1.0,0.0) [0.0|15] ""  BCM1,VAS_L,VAS_R
 SG_ PSD_Ges_Typ m2  : 21|2@1+ (1.0,0.0) [0.0|3] ""  BCM1
 SG_ PSD_Sys_Alter_Karte m0  : 23|3@1+ (1.0,0.0) [0.0|7] ""  BCM1,VAS_L,VAS_R
 SG_ PSD_Ges_Spur_Geschw_Begrenzung m2  : 23|6@1+ (1.0,0.0) [0.0|63] ""  BCM1
 SG_ PSD_Steigung_1_B_Steigung m4  : 24|7@1+ (0.12,0) [0.00|15.00] "Unit_PerCent"  BCM1,VAS_L,VAS_R
 SG_ PSD_Attribut_4_ID m1  : 25|5@1+ (1,0) [1|31] ""  BCM1,VAS_L,VAS_R
 SG_ PSD_Sys_Zielfuehrung m0  : 26|1@1+ (1.0,0.0) [0.0|1] ""  BCM1,VAS_L,VAS_R
 SG_ PSD_Sys_US_State m0  : 27|6@1+ (1.0,0.0) [0.0|63] ""  BCM1,VAS_L,VAS_R
 SG_ PSD_Ges_Geschwindigkeit_Gespann m2  : 29|2@1+ (1.0,0.0) [0.0|3] ""  BCM1
 SG_ PSD_Baum_Breite_VZ m3  : 29|1@1+ (1.0,0.0) [0.0|1] ""  BCM1,VAS_L,VAS_R
 SG_ PSD_Attribut_4_Wert m1  : 30|4@1+ (1,0) [0|15] ""  BCM1,VAS_L,VAS_R
 SG_ PSD_Baum_Breite m3  : 30|24@1+ (0.00001,0) [0.00000|90.00000] "Unit_DegreOfArc"  BCM1,VAS_L,VAS_R
 SG_ PSD_Ges_Geschwindigkeit_Witter m2  : 31|2@1+ (1.0,0.0) [0.0|3] ""  BCM1
 SG_ PSD_Steigung_1_B_Vorz m4  : 31|1@1+ (1.0,0.0) [0.0|1] ""  BCM1,VAS_L,VAS_R
 SG_ PSD_Steigung_1_B_Offset m4  : 32|7@1+ (2,0) [0|254] "Unit_Meter"  BCM1,VAS_L,VAS_R
 SG_ PSD_Sys_Quali_Geometrien m0  : 33|3@1+ (1,0) [0|7] "Unit_None"  BCM1,VAS_L,VAS_R
 SG_ PSD_Ges_Geschwindigkeit_Tag_Anf m2  : 33|3@1+ (1.0,0.0) [0.0|7] ""  BCM1
 SG_ PSD_Attribut_4_Offset m1  : 34|7@1+ (2,0) [0|254] "Unit_Meter"  BCM1,VAS_L,VAS_R
 SG_ PSD_Sys_Quali_Ortsinfo m0  : 36|2@1+ (1,0) [0|3] "Unit_None"  BCM1,VAS_L,VAS_R
 SG_ PSD_Ges_Geschwindigkeit_Tag_Ende m2  : 36|3@1+ (1.0,0.0) [0.0|7] ""  BCM1
 SG_ PSD_Sys_Quali_verfuegbar m0  : 38|1@1+ (1.0,0.0) [0.0|1] ""  BCM1,VAS_L,VAS_R
 SG_ PSD_Sys_Zielfuehrung_geaendert m0  : 39|1@1+ (1.0,0.0) [0.0|1] ""  BCM1,VAS_L,VAS_R
 SG_ PSD_Ges_Geschwindigkeit_Std_Anf m2  : 39|5@1+ (1,0) [0|24] "Unit_Hours"  BCM1
 SG_ PSD_Steigung_1_Attribute_kompl m4  : 39|1@1+ (1.0,0.0) [0.0|1] ""  BCM1,VAS_L,VAS_R
 SG_ PSD_Sys_Geometrieguete_erweitert m0  : 40|8@1+ (1.0,0.0) [0.0|255] ""  BCM1,VAS_L,VAS_R
 SG_ PSD_Steigung_2_Segment_ID m4  : 40|6@1+ (1,0) [2|63] ""  BCM1,VAS_L,VAS_R
 SG_ PSD_Attribut_5_ID m1  : 41|5@1+ (1,0) [1|31] ""  BCM1,VAS_L,VAS_R
 SG_ PSD_Ges_Geschwindigkeit_Std_Ende m2  : 44|5@1+ (1,0) [0|24] "Unit_Hours"  BCM1
 SG_ PSD_Attribut_5_Offset m1  : 46|7@1+ (2,0) [0|254] "Unit_Meter"  BCM1,VAS_L,VAS_R
 SG_ PSD_Steigung_2_Steigung m4  : 46|7@1+ (0.12,0) [0.00|15.00] "Unit_PerCent"  BCM1,VAS_L,VAS_R
 SG_ PSD_Sys_Quali_sonstige_Attribute m0  : 48|3@1+ (1,0) [0|7] "Unit_None"  BCM1,VAS_L,VAS_R
 SG_ PSD_Ges_Ueberholverbot m2  : 49|2@1+ (1.0,0.0) [0.0|3] ""  BCM1
 SG_ PSD_Sys_Quali_Steigungen m0  : 51|3@1+ (1,0) [0|7] ""  BCM1,VAS_L,VAS_R
 SG_ PSD_Ges_Wechselverkehrszeichen m2  : 51|3@1+ (1.0,0.0) [0.0|7] ""  BCM1
 SG_ PSD_Attribut_5_Wert m1  : 53|4@1+ (1,0) [0|15] ""  BCM1,VAS_L,VAS_R
 SG_ PSD_Steigung_2_Vorz m4  : 53|1@1+ (1.0,0.0) [0.0|1] ""  BCM1,VAS_L,VAS_R
 SG_ PSD_Sys_Quali_Strassenkennz m0  : 54|3@1+ (1,0) [0|7] "Unit_None"  BCM1,VAS_L,VAS_R
 SG_ PSD_Wechselverkehrszeichen_Typ m2  : 54|2@1+ (1.0,0.0) [0.0|3] ""  BCM1
 SG_ PSD_Baum_Ausrichtung m3  : 54|10@1+ (0.3515625,0) [0E-7|359.6484375] "Unit_DegreOfArc"  BCM1,VAS_L,VAS_R
 SG_ PSD_Steigung_2_Offset m4  : 54|7@1+ (2,0) [0|254] "Unit_Meter"  BCM1,VAS_L,VAS_R
 SG_ PSD_Ges_Gesetzlich_Kategorie m2  : 56|3@1+ (1.0,0.0) [0.0|7] ""  BCM1
 SG_ PSD_Sys_Quali_Tempolimits m0  : 57|3@1+ (1,0) [0|7] "Unit_None"  BCM1
 SG_ PSD_Attribute_Komplett_06 m1  : 57|1@1+ (1.0,0.0) [0.0|1] ""  BCM1,VAS_L,VAS_R
 SG_ PSD_Ges_Gesetzlich_Zusatz m2  : 59|2@1+ (1.0,0.0) [0.0|3] ""  BCM1
 SG_ PSD_Sys_Quali_Vorfahrtsregelung m0  : 60|3@1+ (1,0) [0|7] "Unit_None"  BCM1
 SG_ PSD_Ges_Verkehrszeichen_Quelle m2  : 61|2@1+ (1.0,0.0) [0.0|3] ""  BCM1
 SG_ PSD_Steigung_2_Attribute_kompl m4  : 61|1@1+ (1.0,0.0) [0.0|1] ""  BCM1,VAS_L,VAS_R
 SG_ PSD_Ges_Attribute_Komplett m2  : 63|1@1+ (1.0,0.0) [0.0|1] ""  BCM1

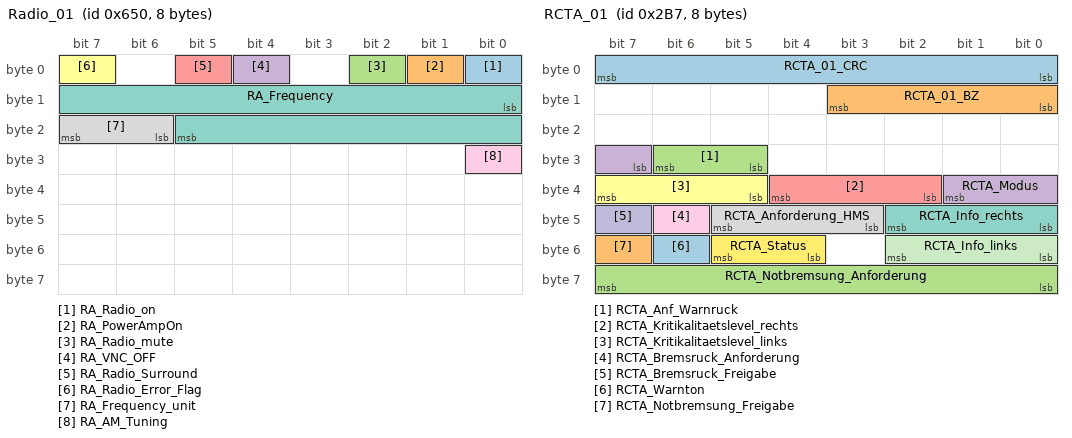
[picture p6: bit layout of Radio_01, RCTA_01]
BO_ 1616 Radio_01: 8 Gateway
 SG_ RA_Radio_on : 0|1@1+ (1,0) [0|1] ""  BCM1
 SG_ RA_PowerAmpOn : 1|1@1+ (1,0) [0|1] ""  Vector__XXX
 SG_ RA_Radio_mute : 2|1@1+ (1,0) [0|1] ""  Vector__XXX
 SG_ RA_VNC_OFF : 4|1@1+ (1,0) [0|1] ""  Vector__XXX
 SG_ RA_Radio_Surround : 5|1@1+ (1,0) [0|1] ""  Vector__XXX
 SG_ RA_Radio_Error_Flag : 7|1@1+ (1.0,0.0) [0.0|1] ""  Vector__XXX
 SG_ RA_Frequency : 8|14@1+ (1,0) [0|16383] ""  BCM1
 SG_ RA_Frequency_unit : 22|2@1+ (1,0) [0|3] ""  BCM1
 SG_ RA_AM_Tuning : 24|1@1+ (1.0,0.0) [0.0|1] ""  BCM1

BO_ 695 RCTA_01: 8 Gateway
 SG_ RCTA_01_CRC : 0|8@1+ (1,0) [0|255] ""  Vector__XXX
 SG_ RCTA_01_BZ : 8|4@1+ (1,0) [0|15] ""  Vector__XXX
 SG_ RCTA_Anf_Warnruck : 29|2@1+ (1.0,0.0) [0.0|3] ""  Vector__XXX
 SG_ RCTA_Modus : 31|3@1+ (1.0,0.0) [0.0|7] ""  Vector__XXX
 SG_ RCTA_Kritikalitaetslevel_rechts : 34|3@1+ (1.0,0.0) [0.0|7] ""  BCM1
 SG_ RCTA_Kritikalitaetslevel_links : 37|3@1+ (1.0,0.0) [0.0|7] ""  BCM1
 SG_ RCTA_Info_rechts : 40|3@1+ (1.0,0.0) [0.0|7] ""  Vector__XXX
 SG_ RCTA_Anforderung_HMS : 43|3@1+ (1.0,0.0) [0.0|7] ""  Vector__XXX
 SG_ RCTA_Bremsruck_Anforderung : 46|1@1+ (1.0,0.0) [0.0|1] ""  Vector__XXX
 SG_ RCTA_Bremsruck_Freigabe : 47|1@1+ (1.0,0.0) [0.0|1] ""  Vector__XXX
 SG_ RCTA_Info_links : 48|3@1+ (1.0,0.0) [0.0|7] ""  Vector__XXX
 SG_ RCTA_Status : 52|2@1+ (1.0,0.0) [0.0|3] ""  BCM1
 SG_ RCTA_Warnton : 54|1@1+ (1.0,0.0) [0.0|1] ""  BCM1
 SG_ RCTA_Notbremsung_Freigabe : 55|1@1+ (1.0,0.0) [0.0|1] ""  Vector__XXX
 SG_ RCTA_Notbremsung_Anforderung : 56|8@1+ (0.078,-19.812) [-19.734|0.000] "Unit_MeterPerSeconSquar"  Vector__XXX

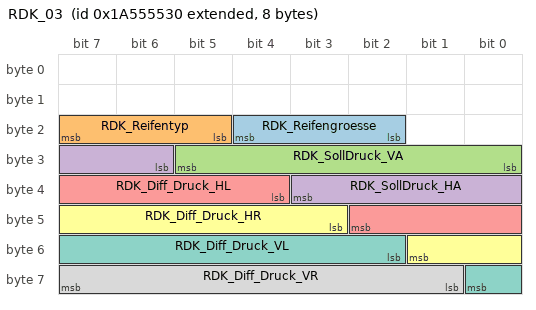
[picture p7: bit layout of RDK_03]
BO_ 2589283632 RDK_03: 8 Gateway
 SG_ RDK_Reifengroesse : 18|3@1+ (1.0,0.0) [0.0|7] ""  VAS_L,VAS_R
 SG_ RDK_Reifentyp : 21|3@1+ (1.0,0.0) [0.0|7] ""  Vector__XXX
 SG_ RDK_SollDruck_VA : 24|6@1+ (0.1,0) [0.0|6.2] "Unit_Bar"  VAS_L,VAS_R
 SG_ RDK_SollDruck_HA : 30|6@1+ (0.1,0) [0.0|6.2] "Unit_Bar"  VAS_L,VAS_R
 SG_ RDK_Diff_Druck_HL : 36|7@1+ (0.1,-6.3) [-6.3|6.3] "Unit_Bar"  VAS_L,VAS_R
 SG_ RDK_Diff_Druck_HR : 43|7@1+ (0.1,-6.3) [-6.3|6.3] "Unit_Bar"  VAS_L,VAS_R
 SG_ RDK_Diff_Druck_VL : 50|7@1+ (0.1,-6.3) [-6.3|6.3] "Unit_Bar"  VAS_L,VAS_R
 SG_ RDK_Diff_Druck_VR : 57|7@1+ (0.1,-6.3) [-6.3|6.3] "Unit_Bar"  VAS_L,VAS_R

BO_ 1711 Rear_View_01: 8 Gateway
 SG_ RV_Video_on : 0|1@1+ (1.0,0.0) [0.0|1] ""  Vector__XXX
 SG_ RV_Dark_Screen : 1|1@1+ (1.0,0.0) [0.0|1] ""  Vector__XXX
 SG_ RV_HMI_Mode : 2|2@1+ (1.0,0.0) [0.0|3] ""  Vector__XXX
 SG_ RV_GL_side : 4|2@1+ (1.0,0.0) [0.0|3] ""  Vector__XXX
 SG_ RV_System_aktiv : 6|1@1+ (1.0,0.0) [0.0|1] ""  Vector__XXX
 SG_ RV_Reinigung_Anf : 7|1@1+ (1.0,0.0) [0.0|1] ""  BCM1
 SG_ RV_Settings_enabled : 8|1@1+ (1.0,0.0) [0.0|1] ""  Vector__XXX
 SG_ RV_Menu_Item : 9|2@1+ (1.0,0.0) [0.0|3] ""  Vector__XXX
 SG_ SV_Video_on : 11|1@1+ (1.0,0.0) [0.0|1] ""  Vector__XXX
 SG_ RV_Calib_Fehler : 12|1@1+ (1.0,0.0) [0.0|1] ""  Vector__XXX
 SG_ RV_GL_Trailer_connect : 13|1@1+ (1.0,0.0) [0.0|1] ""  Vector__XXX
 SG_ RV_GL_Trunk_open : 14|1@1+ (1.0,0.0) [0.0|1] ""  Vector__XXX
 SG_ RV_GL_LWS_Fehler : 15|1@1+ (1.0,0.0) [0.0|1] ""  Vector__XXX
 SG_ RV_Helligkeit : 16|7@1+ (1,0) [0|100] "Unit_PerCent"  Vector__XXX
 SG_ ZFAS_Umfeldbeleuchtung_Anf : 23|1@1+ (1.0,0.0) [0.0|1] ""  BCM1,VAS_L,VAS_R
 SG_ RV_Kontrast : 24|7@1+ (1,0) [0|100] "Unit_PerCent"  Vector__XXX
 SG_ RV_Farbe : 32|7@1+ (1,0) [0|100] "Unit_PerCent"  Vector__XXX

CM_ BO_ 1635 "DLC=8 ab D4 gültig";
CM_ BO_ 2549940736 "VDC funktionaler Request auf CANHS";
CM_ BO_ 1175 "neue Struktur ab MQB ohne KD-Fehler";
CM_ BO_ 1355 "neue Struktur ab MQB ohne KD-Fehler";
CM_ BO_ 304 "Nur in MLB verwendet";
CM_ BO_ 695 "Rear Cross Traffic Assist";

CM_ SG_ 1377 NV_MessZeitpunkt "Messzeitpunkt der Objekte und der Ergebnisse anderer Wahrnehmungsmodule
Bei Nightvision: Aufnahmezeitpunkt des zugehörigen Bildes";
CM_ SG_ 1377 NV_NichtVerfuegbar "Verfuegbarkeit Nightvision";
CM_ SG_ 1377 NV_Obj_01_InvTTCBildebStdA "Standardabweichung zu NV_Obj_01_InvTTCBildeb";
CM_ SG_ 1377 NV_Obj_01_Klasse "Klasse des Objekts";
CM_ SG_ 1377 NV_Obj_Links "Objekt für Markierungslicht in Fahrtrichtung links";
CM_ SG_ 1377 NV_Obj_Rechts "Objekt für Markierungslicht in Fahrtrichtung rechts";
CM_ SG_ 1377 NV_Obj_Warnung_Fussgaenger "Warnung auf NV_Obj_01 im Fahrzeug signalisiert";
CM_ SG_ 1377 NV_Sensor_PositionX "Position der Kamera in USK-Koordinaten
x-Koordinate des Fokussierpunktes der Kamera-Optik";
CM_ SG_ 1377 NV_Sensor_PositionY "Position der Kamera in USK-Koordinaten
y-Koordinate des Fokussierpunktes der Kamera-Optik";
CM_ SG_ 1377 NV_Sensor_PositionZ "Position der Kamera in USK-Koordinaten
z-Koordinate des Fokussierpunktes der Kamera-Optik";

CM_ SG_ 1635 BEM_02_Abschaltstufen "Abschaltstufen des Ruhestrommanagements (Initialisierungswert aus EEprom)

Stufe 0 (keine Einschraenkungen)
Stufe 1 (Abschaltung Hochstromverbraucher)
Stufe 2 (Infotainmentabschaltung)
Stufe 3 (Wake-Up-Sperre)

Für den Transport- und Ruhestrommessm";
CM_ SG_ 1635 BEM_Anf_KL15_schalten "Abschaltempfehlung bzw. Verhinderung der automatischen Abschaltung Kl15 durch das BCM";
CM_ SG_ 1635 BEM_Batteriediagnose "Anzeige von Textwarnungen";
CM_ SG_ 1635 BEM_Generatordiagnose "Ansteuerung Generatorwarnleuchte im Kombi
";
CM_ SG_ 1635 BEM_HL_Regelung_Status "Status Regelung Heizleistung
";
CM_ SG_ 1635 BEM_Ladezustand "Ladezustand der Niedervoltbatterie
";
CM_ SG_ 1635 BEM_MMI_Vorwarnung "Anzeige Vorwarnung MMI-Abschaltung (Initialisierungswert aus EEprom)
";
CM_ SG_ 1635 BEM_Red_Innengeblaese "Reduzierung Innengebläse
";
CM_ SG_ 1635 BEM_REK_aktiv "Rekuperationsfreigabe vom Energiemanagement
0x0 = keine Rekuperationsfreigabe
0x1 = Rekuperationsfreigabe";
CM_ SG_ 1635 BEM_STH_Einschaltverbot "Einschränkung Standheizung/-lüftung durch BEM: Setzt der BEM das Bit, dann darf die Standheizung nicht mehr einschalten
(Die Standheizung muss aber nicht abschalten, sondern darf weiterbrennen)
(Initialisierungswert aus EEprom)
";
CM_ SG_ 1635 BEM_STH_Zielzeit "Maximal mögliche Zeit für den Standheizungsbetrieb, um die Startfähigkeit nicht zu gefährden";
CM_ SG_ 1635 BEM_UBDM "Batteriespannung, gemessen vom Batteriedatenmodul";
CM_ SG_ 1635 BEM_UGenSoll "Sollspannungsvorgabe an den Generator, beinhaltet temperaturoptimierte Batterieladung und Rekuperation";
CM_ SG_ 1635 MIB_Stromsparmodus "Signal beschreibt die Aktivierung für den Stromsparmodus beim MIB.
Bei AUS (= 0) gibt es keine weitere Anforderung an die MIB-Komponenten.
Bei EIN (= 1) werden alle MIB Komponenten in einen Stromsparmodus versetzt.";
CM_ SG_ 1635 NVEM_Anf_SD_schalten "Anforderung Nachlauf für den Steckdosenbetrieb
Initialisierungswert aus EEprom";
CM_ SG_ 1635 NVEM_Batterie_Service "Anforderung einer Batterie-Service - Anzeige / Anforderung an die Werkstatt über MOD";
CM_ SG_ 1635 NVEM_Freigabe_OnlineUpdate "Freigabe für Online-Update durch Energiemanagement";
CM_ SG_ 1635 NVEM_Freigabe_ORU4 "Bestätigung oder Ablehnung eines konkreten, angefragten Online Updates durch das Energiemanagements";
CM_ SG_ 1635 NVEM_Last_Anf "Das NVEM fordert für die Batteriediagnose einen Lastimpuls vom Fahrzeug an, der durch kontrollierte Verbraucherzuschaltungen (z. B. Aktivierung Heckscheibenheizung) generiert wird";

CM_ SG_ 2527679508 NVEM_06_BZ "Fortlaufender Botschaftszaehler";
CM_ SG_ 2527679508 NVEM_06_CRC "Für MLB:
'Berechnung siehe Lastenheft 'Kommunikationsabsicherung für FlexRay und CAN''

Ab MQB und MLBevo:
'Berechnung siehe Lastenheft 'End-to-End Kommunikationsabsicherung''

Endwerte siehe Begleitdokument 'S-PDU Kennungsfolgen'";
CM_ SG_ 2527679508 NVEM_Bordnetzdiagnose "Wird vom NVEM im NV-Netz ein Bordnetz-Fehler erkannt, so soll dies zu einer mehrstufigen Anzeige führen.";
CM_ SG_ 2527679508 NVEM_Energie_Klima_Vorgabe "NVEM-Energievorgabe für Klima-Vorkonditionierung";
CM_ SG_ 2527679508 NVEM_Max_Rampenzeit "Vorgabe der max. Rampenzeit für den Generatorbetrieb des 12V-RSG (RSG-Ansteuerung durch Motor-SG)";
CM_ SG_ 2527679508 NVEM_Max_Spannung "Mild_Hybrid: erlaubte Maximalspannung 12V - Netz
";
CM_ SG_ 2527679508 NVEM_Min_Spannung "Mild_Hybrid: erforderliche Mindestspannung 12V - Netz";
CM_ SG_ 2527679508 NVEM_Min_Spannung_Start "Minimale einzuhaltende Spannung im RSG Wiederstart";
CM_ SG_ 2527679508 NVEM_MV_DC_uMinLV "Abregelgrenze: minimal erlaubte Bordnetzspannung im Hochsetzbetrieb vom 12V-Bordnetz ins 48V-Netz";
CM_ SG_ 2527679508 NVEM_MV_DC_uSollLV "Sollwert für die 12V-Bordnetzspannung im Tiefsetzbetrieb vom 48V-Netz ins 12V-Bordnetz";

CM_ SG_ 913 MO_QBit_Aussen_Temp "QBit der Aussentemperatur. Gesetzt bei Ersatzwert, Init oder Fehler.";
CM_ SG_ 913 MO_Servicemodus "Ausgabe aktiver Service-Mode";
CM_ SG_ 913 OBD_Abs_Load_Val "Absolute Load Value

Übertragung von Meßgrößen an das Getriebesteuergerät für Freeze Frame Abspeicherung bei Getriebefehlern

PID $43 Absolute Load Value; 0 .. 25700%  mit 100/255 %/bit";
CM_ SG_ 913 OBD_Abs_Pedal_Pos "Absolute Pedal Position

Übertragung von Meßgrößen an das Getriebesteuergerät für Freeze Frame Abspeicherung bei Getriebefehlern

PID $49 Accelerator Pedal Position D; 0 .. 100% mit 100/255 %/bit";
CM_ SG_ 913 OBD_Abs_Throttle_Pos "Absolute Throttle Position

Übertragung von Meßgrößen an das Getriebesteuergerät für Freeze Frame Abspeicherung bei Getriebefehlern

PID $11 Absolute Throttle Position; 0 .. 100% mit 100/255 %/bit";
CM_ SG_ 913 OBD_Calc_Load_Val "Calculated Load Value

Übertragung von Meßgrößen an das Getriebesteuergerät für Freeze Frame Abspeicherung bei Getriebefehlern

PID $04 Calculated Load Value; 0 .. 100% mit 100/255 % per bit
";
CM_ SG_ 913 OBD_ClearMem_Inhibit "Das Fehlerspeicher löschen soll nur noch bei stehendem Fahrzeug über Service-04hex ausgeführt werden, dafür wird vom MIL-Master ein CAN Signal benötigt, das das Löschen unter bestimmten Randbedingungen nicht zulässig ist";
CM_ SG_ 913 OBD_Eng_Cool_Temp "Engine Coolant Temperature

Übertragung von Meßgrößen an das Getriebesteuergerät für Freeze Frame Abspeicherung bei Getriebefehlern

PID $05 Engine Coolant Temperature; -40 .. +215°C mit 1°C/bit und 40°C Offset";
CM_ SG_ 913 OBD_Kaltstart_Denominator "Bestimmte Diagnosen werden nur unter Kaltstartbedingungen durchgeführt, der entsprechende Denominator bei IUMPR-pflichtigen Systemen wird anhand dieses vom MSG gebildeten Signals inkrementiert. (Entspricht EVAP-Denominator)";
CM_ SG_ 913 OBD_Minimum_Trip "Grundlage OBD-Gesetz CCR 1968.2 (d)(4.3) Denominator Specifications
Bildung des General Denominator 'Normed Trip':
 600 sec. (kumulativ) Zeit nach Motorstart
 300 sec. (kumulativ) mit Fahrzeuggeschwindigkeit > 25 mph (40 km/h)
 30 sec. (kontinuierlich";
CM_ SG_ 913 OBD_Normed_Trip "Gesetzlich definierte 'Normed Condition' erfüllt, 'General Denominator' darf erhöht werden";
CM_ SG_ 913 OBD_Sperrung_IUMPR "Wenn der General Denominator auf Grund eines Fehlers in den Eingangsgrößen gesperrt wird, wird diese Information über Bussystem als OBD-Statusinformation OBD_Sperrung_IUMPR für andere OBD-Steuergeräte bereitgestellt. 

Das MSG (MIL-Master) setzt dieses ";
CM_ SG_ 913 OBD_Sperrung_Kaltstart_Denom "Information vom MIL Master, dass die Bildung des EVAP Denominators  im Motor nicht möglich ist und damit der noECM-Denominator gesperrt werden darf.";
CM_ SG_ 913 OBD_Warm_Up_Cycle "Mit dem Warm-Up-Cycle wird der zentrale Verlernzähler vom Gateway inkrementiert";

CM_ SG_ 2549940736 OBDC_Funktionaler_Req_All_Data "VDC funktionaler Request auf CANHS";

CM_ SG_ 2549875289 OBDC_Lift_Req_Data "TP-Kanal für den Onboard Datensammler";

CM_ SG_ 2549875396 OBDC_VAS_L_Req_Data "TP-Kanal für den Onboard Datensammler";

CM_ SG_ 2550006468 OBDC_VAS_L_Resp_Data "TP-Kanal für den Onboard Datensammler";

CM_ SG_ 2549875397 OBDC_VAS_R_Req_Data "TP-Kanal für den Onboard Datensammler";

CM_ SG_ 2550006469 OBDC_VAS_R_Resp_Data "TP-Kanal für den Onboard Datensammler";

CM_ SG_ 2589283656 ORU_Status "Broadcast des Status der Konzernfunktion Online Remote Update";

CM_ SG_ 872 PDC2_Tonausgabe_Front "In Abhängigkeit der Systemaktivitäten werden unterschiedliche Tonwarnungen ausgegeben. 
Kombi spielt entsprechende WAV.-Datei über internen Audiomaster ab.

0 = kein Ton
1 = Intervallton 1
2 = Intervallton 2
3 = Intervallton 3
4 = Intervallton 4
5";
CM_ SG_ 872 PDC2_Tonausgabe_Heck "In Abhängigkeit der Systemaktivitäten werden unterschiedliche Tonwarnungen ausgegeben. 
Kombi spielt entsprechende WAV.-Datei über internen Audiomaster ab.

0 = kein Ton
1 = Intervallton 1
2 = Intervallton 2
3 = Intervallton 3
4 = Intervallton 4
5";
CM_ SG_ 872 PH2_Abschaltursache "Abschaltursache bleibt bis zur nächsten Aktivierung bzw. bis KL15 aus gesetzt
Im Fehlerfall (blinkende LED) wird '7' gesendet obwohl das System noch aktiv ist, bei 'geheiltem' Fehler wird sofort wieder der Zustand '0' gesendet";
CM_ SG_ 872 PH2_Anf_Audioabsenkung "Es gibt zwei unterschiedliche Nachlauftimer für dieses Bit:
1. normale Funktion
2. Demotonausgabe";
CM_ SG_ 872 PH2_Anf_Verdeck "Anforderung an ein Verdeck-System, die vom Fahrer angeforderte Öffnung/Schließung zu verhindern";
CM_ SG_ 872 PH2_defekt "Zeigt an das sich die Parkhilfe im Fehlerzustand befindet. Signal bleibt bis zur nächsten 'Gut-Aktivierung' gesetzt.
Spezialfall: Sensordefekt hinten bei Anhängerbetrieb. Anhänger wird abgesteckt Fehler wird gesetzt. Fehlerfall bleibt bis Behebung des De";
CM_ SG_ 872 PH2_Display_Kundenwunsch "Anzeige der bei Aktivierung verwendeten Parameter bzgl. Kundenwunsch Displayanziege. Änderungen werden erst bei erneuter Aktivierung aktualisiert.";
CM_ SG_ 872 PH2_Frequenz_hinten "Uebertragung der aktuell im APS Steuergeraet gespeicherten Werte fuer Tongeber Frequenz hinten
Anzeige der aktuell verwendeten Parameter (nicht zwingend die abgespeicherten - da Werte erst 2s nach der letzten Änderung gespeichert werden!)";
CM_ SG_ 872 PH2_Frequenz_vorn "Uebertragung der aktuell im APS Steuergeraet gespeicherten Werte fuer Tongeber Frequenz vorne
Anzeige der aktuell verwendeten Parameter (nicht zwingend die abgespeicherten - da Werte erst 2s nach der letzten Änderung gespeichert werden!)";
CM_ SG_ 872 PH2_gestoert "Eine Störung ist aufgetreten, der die Parkhilfe in einen 'gestört-Zustand' versetzt, z.B. massiver Fremdultraschall, Vereisung, Schnee.Derzeit nur für Störschall benutzt, da keinerlei andere Erkennung implementiert.";
CM_ SG_ 872 PH2_Lautstaerke_hinten "Uebertragung der aktuell im APS Steuergeraet gespeicherten Werte fuer Tongeber Lautstaerke hinten
Anzeige der aktuell verwendeten Parameter (nicht zwingend die abgespeicherten - da Werte erst 2s nach der letzten Änderung gespeichert werden!)";
CM_ SG_ 872 PH2_Lautstaerke_vorn "Uebertragung der aktuell im APS Steuergeraet gespeicherten Werte fuer Tongeber Lautstaerke vorn.
Anzeige der aktuell verwendeten Parameter (nicht zwingend die abgespeicherten - da Werte erst 2s nach der letzten Änderung gespeichert werden!)";
CM_ SG_ 872 PH2_nachtr_Stopp_An "Dieses Signal dient dem Motor als Trigger, dass ein nachträglicher Motorstopp eingeleitet werden kann, wenn es die Bedingungen des StSt Koordinators dies zulassen. ";
CM_ SG_ 872 PH2_Opt_Anz_H_Hindernis "mindestens 1 Segment wird für den hinteren Detekionsbereich dargestellt, also ein Hindernis ist im Detektionsbereich. Funktion nur bei gesicherter Rückmeldung vom ASG gegeben.";
CM_ SG_ 872 PH2_Opt_Anz_V_Hindernis "mindestens 1 Segment wird für den vorderen Detekionsbereich dargestellt, also ein Hindernis ist im Detektionsbereich. Funktion nur bei gesicherter Rückmeldung vom ASG gegeben.";
CM_ SG_ 872 PH2_Opt_Anzeige_H_ein "OPS hinten ist im Display aktiv bzw. Anzeigemodule hinten sind eingeschaltet. Funktion nur bei gesicherter Rückmeldung vom ASG gegeben.";
CM_ SG_ 872 PH2_Opt_Anzeige_V_ein "OPS vorne ist im Display aktiv bzw. Anzeigemodule vorne sind eingeschaltet. Funktion nur bei gesicherter Rückmeldung vom ASG gegeben.";
CM_ SG_ 872 PH2_StartStopp_Info "Stopp-Freigabe und Start-Anforderung an den Start-Stopp-Koordinator";
CM_ SG_ 872 PH2_Stoermeldung "Meldung einer Störung der PDC an das Kombi";
CM_ SG_ 872 PH2_Systemzustand "Aktivierungsursache wird für die Dauer der Aktivierung gemeldet.
Im Fehlerfall bei atkviem System wechselt das Signal auf '7'
(siehe auch 'Abschaltursache')";
CM_ SG_ 872 PH2_Taster "Taster Status (für RVC/TopView)";
CM_ SG_ 872 PH2_Tongeber_H_aktiv "Rohsignal für 'Tongeber hinten wird angesteuert', verlängerbar mit Nachlauftimer.
Bit wird nicht während des Stellgliedtests angesteuert.";
CM_ SG_ 872 PH2_Tongeber_H_verfuegbar "Tongeber ist für die Tonausgabe für externe Funktionen verfügbar. PDC ist aktiv und Tongeber ist nicht gestört.";
CM_ SG_ 872 PH2_Tongeber_mute "Die Akustikausgabe des Systems wird unterdrückt, z.B. Wählhebel in 'P', Parlbremse geschlossen (8-Kanal-System)";
CM_ SG_ 872 PH2_Tongeber_V_aktiv "Rohsignal für 'Tongeber vorne wird angesteuert', verlängerbar mit Nachlauftimer.
Bit wird nicht während des Stellgliedtests angesteuert.";
CM_ SG_ 872 PH2_Visualisierung "Signal zeigt den Partnersteuergeräten RearView/TopView/ARA/... den aktuellen Status der Visualisierung des OPS. Die Partnersteuergeräte können dadurch auch ihre Aufschaltung an dieses Signal koppeln.";

CM_ SG_ 1175 PDC_Tonausgabe_Front "In Abhängigkeit der Systemaktivitäten werden unterschiedliche Tonwarnungen ausgegeben. 
Kombi spielt entsprechende WAV.-Datei über internen Audiomaster ab.

0 = kein Ton
1 = Intervallton 1
2 = Intervallton 2
3 = Intervallton 3
4 = Intervallton 4
5";
CM_ SG_ 1175 PDC_Tonausgabe_Heck "In Abhängigkeit der Systemaktivitäten werden unterschiedliche Tonwarnungen ausgegeben. 
Kombi spielt entsprechende WAV.-Datei über internen Audiomaster ab.

0 = kein Ton
1 = Intervallton 1
2 = Intervallton 2
3 = Intervallton 3
4 = Intervallton 4
5";
CM_ SG_ 1175 PH_Abschaltursache "Abschaltursache bleibt bis zur nächsten Aktivierung bzw. bis KL15 aus gesetzt
Im Fehlerfall (blinkende LED) wird '7' gesendet obwohl das System noch aktiv ist, bei 'geheiltem' Fehler wird sofort wieder der Zustand '0' gesendet";
CM_ SG_ 1175 PH_Anf_Audioabsenkung "Es gibt zwei unterschiedliche Nachlauftimer für dieses Bit:
1. normale Funktion
2. Demotonausgabe";
CM_ SG_ 1175 PH_Anf_Verdeck "Anforderung an ein Verdeck-System, die vom Fahrer angeforderte Öffnung/Schließung zu verhindern";
CM_ SG_ 1175 PH_defekt "Zeigt an das sich die Parkhilfe im Fehlerzustand befindet. Signal bleibt bis zur nächsten 'Gut-Aktivierung' gesetzt.
Spezialfall: Sensordefekt hinten bei Anhängerbetrieb. Anhänger wird abgesteckt Fehler wird gesetzt. Fehlerfall bleibt bis Behebung des De";
CM_ SG_ 1175 PH_Display_Kundenwunsch "Anzeige der bei Aktivierung verwendeten Parameter bzgl. Kundenwunsch Displayanziege. Änderungen werden erst bei erneuter Aktivierung aktualisiert.";
CM_ SG_ 1175 PH_Frequenz_hinten "Uebertragung der aktuell im APS Steuergeraet gespeicherten Werte fuer Tongeber Frequenz hinten
Anzeige der aktuell verwendeten Parameter (nicht zwingend die abgespeicherten - da Werte erst 2s nach der letzten Änderung gespeichert werden!)";
CM_ SG_ 1175 PH_Frequenz_vorn "Uebertragung der aktuell im APS Steuergeraet gespeicherten Werte fuer Tongeber Frequenz vorne
Anzeige der aktuell verwendeten Parameter (nicht zwingend die abgespeicherten - da Werte erst 2s nach der letzten Änderung gespeichert werden!)";
CM_ SG_ 1175 PH_gestoert "Eine Störung ist aufgetreten, der die Parkhilfe in einen 'gestört-Zustand' versetzt, z.B. massiver Fremdultraschall, Vereisung, Schnee.Derzeit nur für Störschall benutzt, da keinerlei andere Erkennung implementiert.";
CM_ SG_ 1175 PH_Lautstaerke_hinten "Uebertragung der aktuell im APS Steuergeraet gespeicherten Werte fuer Tongeber Lautstaerke hinten
Anzeige der aktuell verwendeten Parameter (nicht zwingend die abgespeicherten - da Werte erst 2s nach der letzten Änderung gespeichert werden!)";
CM_ SG_ 1175 PH_Lautstaerke_vorn "Uebertragung der aktuell im APS Steuergeraet gespeicherten Werte fuer Tongeber Lautstaerke vorn.
Anzeige der aktuell verwendeten Parameter (nicht zwingend die abgespeicherten - da Werte erst 2s nach der letzten Änderung gespeichert werden!)";
CM_ SG_ 1175 PH_nachtr_Stopp_Anf "Dieses Signal dient dem Motor als Trigger, dass ein nachträglicher Motorstopp eingeleitet werden kann, wenn es die Bedingungen des StSt Koordinators dies zulassen. ";
CM_ SG_ 1175 PH_Opt_Anz_H_Hindernis "mindestens 1 Segment wird für den hinteren Detekionsbereich dargestellt, also ein Hindernis ist im Detektionsbereich. Funktion nur bei gesicherter Rückmeldung vom ASG gegeben.";
CM_ SG_ 1175 PH_Opt_Anz_V_Hindernis "mindestens 1 Segment wird für den vorderen Detekionsbereich dargestellt, also ein Hindernis ist im Detektionsbereich. Funktion nur bei gesicherter Rückmeldung vom ASG gegeben.";
CM_ SG_ 1175 PH_Opt_Anzeige_H_ein "OPS hinten ist im Display aktiv bzw. Anzeigemodule hinten sind eingeschaltet. Funktion nur bei gesicherter Rückmeldung vom ASG gegeben.";
CM_ SG_ 1175 PH_Opt_Anzeige_V_ein "OPS vorne ist im Display aktiv bzw. Anzeigemodule vorne sind eingeschaltet. Funktion nur bei gesicherter Rückmeldung vom ASG gegeben.";
CM_ SG_ 1175 PH_StartStopp_Info "Stopp-Freigabe und Start-Anforderung an den Start-Stopp-Koordinator";
CM_ SG_ 1175 PH_Stoermeldung "Meldung einer Störung der PDC an das Kombi";
CM_ SG_ 1175 PH_Systemzustand "Aktivierungsursache wird für die Dauer der Aktivierung gemeldet.
Im Fehlerfall bei atkviem System wechselt das Signal auf '7'
(siehe auch 'Abschaltursache')";
CM_ SG_ 1175 PH_Taster "Taster Status (für RVC/TopView)";
CM_ SG_ 1175 PH_Tongeber_H_aktiv "Rohsignal für 'Tongeber hinten wird angesteuert', verlängerbar mit Nachlauftimer.
Bit wird nicht während des Stellgliedtests angesteuert.";
CM_ SG_ 1175 PH_Tongeber_H_verfuegbar "Tongeber ist für die Tonausgabe für externe Funktionen verfügbar. PDC ist aktiv und Tongeber ist nicht gestört.";
CM_ SG_ 1175 PH_Tongeber_mute "Die Akustikausgabe des Systems wird unterdrückt, z.B. Wählhebel in 'P', Parlbremse geschlossen (8-Kanal-System)";
CM_ SG_ 1175 PH_Tongeber_V_aktiv "Rohsignal für 'Tongeber vorne wird angesteuert', verlängerbar mit Nachlauftimer.
Bit wird nicht während des Stellgliedtests angesteuert.";
CM_ SG_ 1175 PH_Visualisierung "Signal zeigt den Partnersteuergeräten RearView/TopView/ARA/... den aktuellen Status der Visualisierung des OPS. Die Partnersteuergeräte können dadurch auch ihre Aufschaltung an dieses Signal koppeln.";
CM_ SG_ 1175 PLA_Anf_Aufschaltung_RVC "Anforderung der Aufschaltung RVC durch PLA";

CM_ SG_ 1353 PL_Luecke_P0_x "x-Koordinate des Punktes P0
";
CM_ SG_ 1353 PL_Luecke_P0_y "y-Koordinate des Punktes P0";
CM_ SG_ 1353 PL_Luecke_P2_x "x-Koordinate des Punktes P2";
CM_ SG_ 1353 PL_Luecke_P2_y "y-Koordinate des Punktes P2";

CM_ SG_ 1354 PL_Luecke_P1_x "x-Koordinate des Punktes P1";
CM_ SG_ 1354 PL_Luecke_P1_y "y-Koordinate des Punktes P1";
CM_ SG_ 1354 PL_Luecke_P3_x "x-Koordinate des Punktes P3";
CM_ SG_ 1354 PL_Luecke_P3_y "y-Koordinate des Punktes P3";

CM_ SG_ 1355 BCM_WAH_Meldung "Steuert die HMI-Meldungen im Kombi für den Wiederanfahrhinweis";
CM_ SG_ 1355 PDC_Charisma_FahrPr "Istwert der Kennline (siehe System-LAH MQB FPA)";
CM_ SG_ 1355 PDC_Charisma_Status "Charisma Systemstatus des Charisma-Teilnehmers";
CM_ SG_ 1355 PH_Aufschaltursache "Der Grund für die Aufschaltung der Einparkhilfe wird angegeben, z.B. bei der Aktivierung der Einparkhilfe durch eine andere Funktion, wird diese Funktion als Aktivierungsursache für die Dauer der Aktivierung gemeldet.
Das Signal wird den PH_Systemzustand";
CM_ SG_ 1355 PH_Ton_Ausgabe "Anforderung einer Tonausgabe beim MIB3 durch die Parkhilfe";
CM_ SG_ 1355 PH_Ton_Lautstaerke "Wunschlautstärke der Tonanforderung beim MIB3 durch die Parkhilfe.";
CM_ SG_ 1355 PH_Ton_Pausenlaenge "Pause zwischen den angeforderten Tönen beim MIB3 durch die Parkhilfe. Nur für Intervalltöne, nicht relevant für Dauerton und Quittierungston.";
CM_ SG_ 1355 PH_Ton_Richtung "Abspielrichtung des angeforderten Ton beim MIB3 durch die Parkhilfe";
CM_ SG_ 1355 PH_Verschmutzungsmeldung "Meldung einer Verschmutzung/Vereisung der PDC an das Kombi";

CM_ SG_ 803 PCF_01_BZ "Botschaftszähler pro PDU


Botschaft asynchron geroutet. Zählerwert kann springen.";
CM_ SG_ 803 PCF_01_CRC "Für MLB:
'Berechnung siehe Lastenheft 'Kommunikationsabsicherung für Flexray und CAN''

Ab MQB und MLBevo:
'Berechnung siehe Lastenheft 'End-to-End Kommunikationsabsicherung'

Endwerte siehe Begleitdokument 'S-PDU Kennungsfolge'";
CM_ SG_ 803 PCF_HBA_Param "Mitteilung an das ESC-SG, welcher HBA-Parametersatz verwendet werden muss";
CM_ SG_ 803 PCF_Prefill_Anf "Mitteilung an das ESC-SG, dass die Prefill-Funktion aktiviert werden soll";
CM_ SG_ 803 PCF_Ruckprofil "Mitteilung an das ESC-SG welches Ruckprofil angefordert wird";
CM_ SG_ 803 PCF_Verz_Anf "Verzoegerungsanforderung an das ESC";
CM_ SG_ 803 PCF_Verz_Anf_ASIL "ASIL-Level der derzeit angeforderten Verzögerung";
CM_ SG_ 803 PCF_Verz_Auspraegung "Anforderung der Auspraegung einer Bremsanforderung an das ESC-SG";
CM_ SG_ 803 PCF_Verz_Info "Mitteilung an das ESC-SG welche Bremsanforderung aktuell angefordert wird";
CM_ SG_ 803 SC_AbstWarn_Texte "Safety Computer übermittelt Systemstatus der Abstandswarnfunktion an Kombi";
CM_ SG_ 803 SC_WarnBrems_Texte "Safety Computer übermittelt Systemstatus der Funktion Warn- und Bremsfunktion an Kombi";

CM_ SG_ 2527679498 IAA_Active_User_ID "Signal gibt die IAA Nutzer ID des aktiven IAA Nutzers an.";
CM_ SG_ 2527679498 IAA_Identified_User_ID "Signal gibt die IAA Nutzer ID des vom BCM identifizierten IAA Nutzers an";
CM_ SG_ 2527679498 IAA_PSO_wake_up "Signal zum Wake_up der IAA und PSO Komponenten im Kombi und in der OCU";
CM_ SG_ 2527679498 Perso_Aktiv "Status Personalisierung für den Fahrer aktiviert/ deaktiviert (via HMI)";
CM_ SG_ 2527679498 Perso_Bedienstelle "Signal zeigt an, über welche Bedienstelle die Umschaltung des Benutzerkontos gestartet wurden.";
CM_ SG_ 2527679498 Perso_Fahrernummer "Signal gibt die jewels aktuelle Nummer des Fahrers für die Personalisierung an.
Nicht für AU736 und AU48x.";
CM_ SG_ 2527679498 Perso_Freigabe_Verstellung "Signal zeigt an, ob die Ergonomiefunktionen nach Umschaltung des Benutzerkontos verfahren dürfen.";
CM_ SG_ 2527679498 Perso_Kontonummer "Signal gibt die jewels aktuelle Kontonummer für die Personalisierung an.
Nicht für AU736 und AU48x.";
CM_ SG_ 2527679498 Perso_Schreibschutz "Signal zeigt an, ob der Schreibschutz der Personalisierung aktiv ist.";
CM_ SG_ 2527679498 Perso_Status "Codierstatus der Personalisierung
Nicht für AU736 und AU49x.";
CM_ SG_ 2527679498 Perso_Steuerung "Signal gibt einen Steuerungsbefehl an die Funktionsteilnehmer der Personalisierung.
Nicht für AU736 und AU49x.";
CM_ SG_ 2527679498 Perso_Steuerungsparameter "Signal gibt einen Parameter zum Steuerungsbefehl (Signal Perso_Steuerung) für die Personalisierung an.
Nicht für AU736 und AU49x.";

CM_ SG_ 304 PLA_01_BZ "4bit-Botschaftszaehler, wird in jeder Sendebotschaft inkrementiert

";
CM_ SG_ 304 PLA_01_CRC "Für MLB:
Berechnung siehe Lastenheft 'Kommunikationsabsicherung für FlexRay und CAN''

Ab MQB und MLBevo:
Berechnung siehe Lastenheft 'End-to-End Kommunikationsabsicherung'

Endwerte siehe Begleitdokument 'S-PDU Kennungsfolgen'";
CM_ SG_ 304 PLA_01_Signal_red_cyclic "Zeigt die reduzierte Zykluszeit der CAN-Botschaft 'PLA_01' an.";
CM_ SG_ 304 PLA_Anf_Bremsverzoegerung "Anforderung der Verzögerungsbremsung";
CM_ SG_ 304 PLA_BremsMom_Verzoeg "Kennzeichnung der übertragenen Sollvorgabe
0 = Bremsmoment: MQB A
1 = Bremsverzoegerung: MLBevo, MQB B
Die Bedatung ist im Fahrzeug konstant.";
CM_ SG_ 304 PLA_Bremsverzoegerung "Wert der Bremsverzögerung für eine Bremsung durch PLA";
CM_ SG_ 304 PLA_Status_PLA_EPS "Schnittstelle zum Austausch von Statusinformationen der internen Statusmaschine. Erforderlich zum Aktivieren der automatischen Lenkung.";
CM_ SG_ 304 PLA_Status_PLA_ESP "Zustand der Statusmaschine des PLA für die korrespondierenden Statusmaschine in der Bremse.";
CM_ SG_ 304 PLA_VZ_Zahnstangen_Pos_Soll "Vorzeichen zum Lenkwinkel-Steuerbefehl an EPS zum Einstellen des angeforderten Lenkwinkels.";
CM_ SG_ 304 PLA_Zahnstangen_Pos_Soll "Steuerbefehl an EPS zum Einstellen der angeforderten Zahnstangenposition.";

CM_ SG_ 342 PLA_02_BZ "4bit-Botschaftszaehler, wird in jeder Sendebotschaft inkrementiert

";
CM_ SG_ 342 PLA_02_CRC "Für MLB:
Berechnung siehe Lastenheft 'Kommunikationsabsicherung für FlexRay und CAN''

Ab MQB und MLBevo:
Berechnung siehe Lastenheft 'End-to-End Kommunikationsabsicherung'

Endwerte siehe Begleitdokument 'S-PDU Kennungsfolgen'";
CM_ SG_ 342 PLA_02_Signal_red_cyclic "Zeigt die reduzierte Zykluszeit der CAN-Botschaft 'PLA_02' an.";
CM_ SG_ 342 PLA_HAL_Radwinkel_Soll "Steuerbefehl an HAL zum Einstellen des angeforderten Radwinkels.";
CM_ SG_ 342 PLA_HAL_VZ_Radwinkel_Soll "Vorzeichen des vom PLA angeforderten Lenkwinkels der HAL";
CM_ SG_ 342 PLA_maximale_Geschwindigkeit "Gibt den Wert der maximal zulässigen Geschwindigkeit vor. Die während aktiver PLA Regelung vom TSK zugelassen werden darf.";
CM_ SG_ 342 PLA_Status_PLA_HAL "Zustand der Statusmaschine des PLA für die korrespondierenden Statusmaschine in der Hinterachslenkung,";
CM_ SG_ 342 PLA_Status_PLA_TSK "Statusinformation von PLA für Handshakemechanismus mit TSK (Speedlimiterfunktion)";

CM_ SG_ 1166 PLA_Anf_Akustik "Anzeige, ob das PLA einen Gong im Kombi anfordert, Gong soll mit dem Übergang 0->1 abgespielt werden.";
CM_ SG_ 1166 PLA_Anf_Anzeige_Bremsfuss "Anzeige, ob PLA die Anzeige eines Bremsfusses anfordert";
CM_ SG_ 1166 PLA_Anf_Anzeige_Mini "Anforderung der Miniaturanzeige ";
CM_ SG_ 1166 PLA_Anf_Anzeige_Schwellpfeil "Anzeige, ob PLA im Kombi den Schwellpfeil zur Darstellung der Restwegstrecke im aktuellen Zug anfordert";
CM_ SG_ 1166 PLA_Anf_Anzeigemodus "Anzeigemodus das vom PLA je nach Parkszenario beim Kombi angefordert wird";
CM_ SG_ 1166 PLA_Anf_Funktionsdisclaimer "Anforderung des Funktionsdisclaimer durch PLA";
CM_ SG_ 1166 PLA_Anf_Meldungen "Anforderung der Meldungen:
0 - Keine Meldung
1-127 niederprio. Meldungen
128-255 hochprio. Meldungen";
CM_ SG_ 1166 PLA_Anforderung_HMS "Für die Anforderung der HMS Funktionen";
CM_ SG_ 1166 PLA_Anzahl_Segmente_Schwellpfeil "Wird ein Schwellpfeil angezeigt, gibt dieses Signal die Länge des breiten Balkens in Anzahl der Segmente (max. Länge: 15 Segmente).

Wird keine Anzeige der Schwellpfeile angefordert, muss die Anzahl Segmente 0 sein.";
CM_ SG_ 1166 PLA_Mini_Modus "Art des vom PLA zur Darstellung angeforderten Minis. Wird angezeigt, wenn PLA_Anf_Anzeige_Mini=1.";
CM_ SG_ 1166 PLA_Status_Aktive_Seite "Anzeige der zu parkenden Seite";
CM_ SG_ 1166 PLA_Status_beenden_Mini "Status Anzeige beendet Mini";
CM_ SG_ 1166 PLA_Status_Funktion "Funktionsstati, die die einzelnen Schritte innerhalb eines Parkszenarios anzeigen.";
CM_ SG_ 1166 PLA_Status_Laengsparken_Mini "Status Anzeige Längsparken Mini";
CM_ SG_ 1166 PLA_Status_QP_Rueckw_Mini "Status Anzeige Querparken rückwärts Mini";
CM_ SG_ 1166 PLA_Status_QP_Vorw_Mini "Status Anzeige Querparken vorwärtsMini";

CM_ SG_ 319 PreCrash_02_BZ "Botschaftszaehler
Botschaft asynchron geroutet. Zählerwert kann springen.";
CM_ SG_ 319 PreCrash_02_CRC "Ab MQB und MLBevo:
'Berechnung siehe Lastenheft 'End-to-End Kommunikationsabsicherung''

Endwerte siehe Begleitdokument 'S-PDU Kennungsfolgen'";
CM_ SG_ 319 PreCrash_Anforderung_AFR "Anforderungen der Funktion PrecrashSeite an Fahrwerksregelung";
CM_ SG_ 319 PreCrash_BFS_KSV_verfahren "Ansteuerung der Kopfstuetze Beifahrerseite durch die Funktion PreCrash";
CM_ SG_ 319 PreCrash_BFS_Pneumatik_ansteuern "Ansteuerung des Beifahrersitzes durch die PreCrash-Funktionen";
CM_ SG_ 319 PreCrash_BFS_Sitzlehne_verfahren "Ansteuerung des Beifahrersitzes durch die PreCrash-Funktionen";
CM_ SG_ 319 PreCrash_Blinken "Safety Computer übermittelt Blinkverhalten bei einer PreCrash-Auslösung an den BCM2";
CM_ SG_ 319 PreCrash_Charisma_FahrPr "Aktuell eingestelltes Fahrprogramm der Funktion PreCrash";
CM_ SG_ 319 PreCrash_Charisma_Status "Verfügbarkeit der Funktion PreCrash für die Ansteuerung durch den Charisma_Koordinator";
CM_ SG_ 319 PreCrash_Fenster_schliessen "Anforderung Seitenscheiben schließen durch die Funktion PreCrash";
CM_ SG_ 319 PreCrash_Fo_KSV_verfahren "Ansteuerung der Kopfstuetzen im Fond durch die PreCrash-Funktionen";
CM_ SG_ 319 PreCrash_Fo_Pneumatik_ansteuern "Ansteuerung der Fondsitze durch die PreCrash-Funktionen";
CM_ SG_ 319 PreCrash_Fo_Sitzlehne_verfahren "Ansteuerung des Fondsitzes durch die PreCrash-Funktionen";
CM_ SG_ 319 PreCrash_FS_KSV_verfahren "Ansteuerung der Kopfstuetze Fahrerseite durch die PreCrash-Funktionen";
CM_ SG_ 319 PreCrash_FS_Pneumatik_ansteuern "Ansteuerung des Fahrersitzes durch die PreCrash-Funktionen";
CM_ SG_ 319 PreCrash_FS_Sitzlehne_verfahren "Ansteuerung des Fahrersitzes durch die PreCrash-Funktionen";
CM_ SG_ 319 PreCrash_Schiebedach_schliessen "Anforderung Schiebedach schließen durch die Funktion PreCrash";
CM_ SG_ 319 PreCrash_Tueren_Verriegeln "Anforderung Türen Verriegeln durch die Funktion PreCrash";
CM_ SG_ 319 SC_PreCrash_LED "Ansteuerung LED-Leiste im Kombi durch SC";
CM_ SG_ 319 SC_PreCrash_Texte "Safety Computer übermittelt Systemstatus der PreCrash Funktionen an Kombi";
CM_ SG_ 319 SC_PreCrash_Warnung "Safety Computer übermittelt Warnung der PreCrash Funktionen an Kombi";
CM_ SG_ 319 SC_PreSense_FCWP "Mitteilung an das NightVision, auf welche Art von Objekt eine Warnung angefordert wird";

CM_ SG_ 1122 PSD_Abzweigerichtung "Richtung, in der die Abzweigung von der Hauptroute abzweigt
";
CM_ SG_ 1122 PSD_Abzweigewinkel "Winkel, unter dem die Abzweigung von der Hauptroute abzweigt.
";
CM_ SG_ 1122 PSD_ADAS_Qualitaet "ADAS Qualtität des Streckensegments.";
CM_ SG_ 1122 PSD_Anfangskruemmung "Startkrümmung der Klothoide des übermittelten abzweigenden Streckensegments. 
1/(1+0.155 * x^2) {1/m}'
";
CM_ SG_ 1122 PSD_Anfangskruemmung_Vorz "Vorzeichen für die Startkrümmung bei Abzweigungen
";
CM_ SG_ 1122 PSD_Bebauung "Segement befindet sich innerhalb bebauten Gebietes";
CM_ SG_ 1122 PSD_Endkruemmung "'Endkrümmung der Klotoide des übermittelten Streckensegments. Die Anfangskrümmung des folgenden Streckensegments entspricht der Endkrümmung dieses Segments. Krümmung = 1/(1+0.155 * x²) [1/m]

";
CM_ SG_ 1122 PSD_Fahrspuren_Anzahl "Anzahl der Fahrspuren in Fahrtrichtung
";
CM_ SG_ 1122 PSD_Geradester_Pfad "Segment ist Teil des geradesten Pfades";
CM_ SG_ 1122 PSD_Idenditaets_ID "Identifier auf ein Streckensegment, dass mit dem aktuell übertragenen geometrisch identisch ist.";
CM_ SG_ 1122 PSD_Segment_ID "Identifier des prädiktiven Streckensegments
";
CM_ SG_ 1122 PSD_Segment_Komplett "Zeigt, ob alle Attribute für das Segment übertragen worden sind
";
CM_ SG_ 1122 PSD_Segmentlaenge "Gesamtlänge des prädiktiven Streckensegments";
CM_ SG_ 1122 PSD_Strassenkategorie "Klassifizierung der Straße des beschriebenen Segments
";
CM_ SG_ 1122 PSD_Vorgaenger_Segment_ID "An dem Streckensegment mit diesem Identifier schließt sich das neue Segment mit der ID 'PSD_01_Segment_ID' an.
";
CM_ SG_ 1122 PSD_wahrscheinlichster_Pfad "Identifiziert den vom Navigationssystem berechneten wahrscheinlichsten Pfad des Fahrzeuges. ";

CM_ SG_ 1123 PSD_Attribut_1_ID "Identifier des ersten Attributes";
CM_ SG_ 1123 PSD_Attribut_1_Offset "Positionsoffset im Segment für die Position des Attributs";
CM_ SG_ 1123 PSD_Attribut_1_Wert "Wert des ersten Attributes";
CM_ SG_ 1123 PSD_Attribut_2_ID "Identifier des zweiten Attributes";
CM_ SG_ 1123 PSD_Attribut_2_Offset "Positionsoffset im Segment für die Position des Attributs";
CM_ SG_ 1123 PSD_Attribut_2_Wert "Wert des zweiten Attributes";
CM_ SG_ 1123 PSD_Attribut_Segment_ID_05 "Identifier des Streckensegments, für das die weiteren Attribute in der Botschaft gültig sind";
CM_ SG_ 1123 PSD_Attribute_Komplett_05 "Zeigt, ob alle Attribute für das Segment übertragen worden sind";
CM_ SG_ 1123 PSD_Pos_Fahrspur "Spur, auf der sich das Fahrzeug aktuell befindet";
CM_ SG_ 1123 PSD_Pos_Fehler_Laengsrichtung "Laengsfehler der Positionierung";
CM_ SG_ 1123 PSD_Pos_Inhibitzeit "Zeitspanne zwischen Generierung der PSD Daten im Navigationssystem und Versand der Daten auf den Most
";
CM_ SG_ 1123 PSD_Pos_Segment_ID "Identifier des Streckensegments, auf dem sich das Fahrzeug aktuell befindet
";
CM_ SG_ 1123 PSD_Pos_Segmentlaenge "Verbleibende Länge des Streckensegments, auf dem sich das Fahrzeug aktuell befindet
";
CM_ SG_ 1123 PSD_Pos_Standort_Eindeutig "Ist die Position des Fahrzeugs eindeutig dem aktuelle Segment zugeordnet, oder gibt es fahrbare alternative Segmente, die bei akteller GPS-Position ebenfalls als aktuelles Segment möglich wären.";

CM_ SG_ 1124 PSD_06_Mux "Multiplex Zähler für die PSD_06-Botschaft";
CM_ SG_ 1124 PSD_Attribut_3_ID "Identifier des dritten Attributes";
CM_ SG_ 1124 PSD_Attribut_3_Offset "Positionsoffset im Segment für die Position des Attributs";
CM_ SG_ 1124 PSD_Attribut_3_Wert "Wert des dritten Attributes";
CM_ SG_ 1124 PSD_Attribut_4_ID "Typ von Attribut 4";
CM_ SG_ 1124 PSD_Attribut_4_Offset "Offset von Attribut 4";
CM_ SG_ 1124 PSD_Attribut_4_Wert "Wert von Attribut 4";
CM_ SG_ 1124 PSD_Attribut_5_ID "Typ von Attribut 5";
CM_ SG_ 1124 PSD_Attribut_5_Offset "Offset von Attribut 5";
CM_ SG_ 1124 PSD_Attribut_5_Wert "Wert von Attribut 5";
CM_ SG_ 1124 PSD_Attribut_Segment_ID "Identifier des Streckensegments,für das die weiteren Attribute in der Botschaft gültig sind";
CM_ SG_ 1124 PSD_Attribute_Komplett_06 "Zeigt, ob alle Attribute für das Segment übertragen worden sind
";
CM_ SG_ 1124 PSD_Baum_Ausrichtung "Ausrichtung des Fahrzeugsegments zu Nord";
CM_ SG_ 1124 PSD_Baum_Breite "WGS84 Breite des Fahrzeugsegments";
CM_ SG_ 1124 PSD_Baum_Breite_VZ "Vorzeichen WGS84 Breite des Fahrzeugsegments";
CM_ SG_ 1124 PSD_Baum_Laenge "WGS84 Laenge des Fahrzeugsegments";
CM_ SG_ 1124 PSD_Baum_Laenge_VZ "Vorzeichen WGS84 Laenge des Fahrzeugsegments";
CM_ SG_ 1124 PSD_Ges_Attribute_Komplett "Zeigt, ob alle Attribute für das Segment übertragen worden sind";
CM_ SG_ 1124 PSD_Ges_Geschwindigkeit_Gespann "Gilt diese Einschränkung der Geschwindigkeit für alle Fahrzeuge oder ausschließlich für PKW mit Gespann oder für LKW, Buss, etc.";
CM_ SG_ 1124 PSD_Ges_Geschwindigkeit_Std_Anf "Stunde, zu der die stündliche Geschwindigkeitsbegrenzung beginnt
0h.. 24h";
CM_ SG_ 1124 PSD_Ges_Geschwindigkeit_Std_Ende "Stunde, an der die stündliche Geschwindigkeitsbegrenzung endet
0h.. 24h";
CM_ SG_ 1124 PSD_Ges_Geschwindigkeit_Tag_Anf "Wochentag, an dem die tägliche Geschwindigkeitsbegrenzung beginnt";
CM_ SG_ 1124 PSD_Ges_Geschwindigkeit_Tag_Ende "Wochentag, an dem die tägliche Geschwindigkeitsbegrenzung endet";
CM_ SG_ 1124 PSD_Ges_Geschwindigkeit_Witter "Witterungsabhängigkeit der Geschwindigkeitsbegrenzung";
CM_ SG_ 1124 PSD_Ges_Gesetzlich_Kategorie "Kategorie für das legale Gebot";
CM_ SG_ 1124 PSD_Ges_Gesetzlich_Zusatz "Zusatz für das legale Gebot";
CM_ SG_ 1124 PSD_Ges_Offset "Positionsoffset im Segment für die Position des Attributs";
CM_ SG_ 1124 PSD_Ges_Segment_ID "Identifier des prädiktiven Streckensegments ab dem die Geschwindigkeitsbegrenzungen und mögliche Einschränkungen gelten.
";
CM_ SG_ 1124 PSD_Ges_Spur_Geschw_Begrenzung "Definition der Spuren, für die das übertragene Gebot gilt";
CM_ SG_ 1124 PSD_Ges_Typ "Typ der Geschwindigkeitsbegrenzung
";
CM_ SG_ 1124 PSD_Ges_Verkehrszeichen_Quelle "Quelle der Verkehrszeicheninformation";
CM_ SG_ 1124 PSD_Ges_Wechselverkehrszeichen "Am Beginn des Segments ist ein Wechselverkehrszeichen angebracht.";
CM_ SG_ 1124 PSD_Steigung_1_A_Offset "Positionsoffset im Segment für die Position der Steigung 1 A";
CM_ SG_ 1124 PSD_Steigung_1_A_Steigung "Steigung des Segments ab Offset 1A";
CM_ SG_ 1124 PSD_Steigung_1_A_Vorz "Vorzeichen für Steigung 1 A";
CM_ SG_ 1124 PSD_Steigung_1_Attribute_kompl "Alle Steigungsdaten für dieses Segment gesendet";
CM_ SG_ 1124 PSD_Steigung_1_B_Offset "Positionsoffset im Segment für die Position der Steigung 1 B";
CM_ SG_ 1124 PSD_Steigung_1_B_Steigung "Steigung des Segments ab Offset 1B";
CM_ SG_ 1124 PSD_Steigung_1_B_Vorz "Vorzeichen für Steigung 1 B";
CM_ SG_ 1124 PSD_Steigung_1_Segment_ID "Identifier des prädiktiven Streckensegments, zu dem die  ersten beiden Steigungswerte dieser Botschaft gehören";
CM_ SG_ 1124 PSD_Steigung_2_Attribute_kompl "Alle Steigungsdaten für dieses Segment gesendet";
CM_ SG_ 1124 PSD_Steigung_2_Offset "Positionsoffset im Segment für die Position der Steigung 2";
CM_ SG_ 1124 PSD_Steigung_2_Segment_ID "Identifier des prädiktiven Streckensegments, zu dem der dritte Steigungswert dieser Botschaft gehört";
CM_ SG_ 1124 PSD_Steigung_2_Steigung "Steigung des Segments ab Offset 2";
CM_ SG_ 1124 PSD_Steigung_2_Vorz "Vorzeichen für Steigung 2";
CM_ SG_ 1124 PSD_Sys_Alter_Karte "Alter der Karte";
CM_ SG_ 1124 PSD_Sys_Geometrieguete "Maß für die Güte der Klothoidengeometrie.";
CM_ SG_ 1124 PSD_Sys_Geometrieguete_erweitert "Güte der Kurvenrepräsentation der Klothoiden";
CM_ SG_ 1124 PSD_Sys_Geschwindigkeit_Einheit "Unterscheidung zwischen km/h und miles/h";
CM_ SG_ 1124 PSD_Sys_Laendercode "Ländercode
";
CM_ SG_ 1124 PSD_Sys_Mapmatchingguete "Güte des Mapmatchings";
CM_ SG_ 1124 PSD_Sys_Quali_Geometrien "Qualität der Geometrien in dieser Region";
CM_ SG_ 1124 PSD_Sys_Quali_Ortsinfo "Qualität Ortsinformationen (Bebauung, Ortsschild) dieser Region";
CM_ SG_ 1124 PSD_Sys_Quali_sonstige_Attribute "Qualität sonstiger Attribute dieser Region";
CM_ SG_ 1124 PSD_Sys_Quali_Steigungen "Qualität der Steigungen dieser Region";
CM_ SG_ 1124 PSD_Sys_Quali_Strassenkennz "Qualität Straßenkennzeichnungen dieser Region";
CM_ SG_ 1124 PSD_Sys_Quali_Tempolimits "Qualität Tempolimits dieser Region";
CM_ SG_ 1124 PSD_Sys_Quali_verfuegbar "Karte enthält gültige Qualitätskriterien";
CM_ SG_ 1124 PSD_Sys_Quali_Vorfahrtsregelung "Qualität Vorfahrtsregelungen dieser Region";
CM_ SG_ 1124 PSD_Sys_Segment_ID "Identifier des prädiktiven Streckensegments ab dem die Systeminformationen gültig sind.
";
CM_ SG_ 1124 PSD_Sys_US_State "Name des USA-State";
CM_ SG_ 1124 PSD_Sys_Verkehrsrichtung "Unterscheidung zwischen Linksverkehr und Rechtsverkehr";
CM_ SG_ 1124 PSD_Sys_Zielfuehrung "Zielfuehrung im Navigationssystem. Damit lässt sich der wahrscheinlichste Pfad des Fahrzeuges zuverlässig angeben.";
CM_ SG_ 1124 PSD_Sys_Zielfuehrung_geaendert "Die Zielführung (Route) hat sich geändert hat ohne dass der Fahrer eine neue Zielführung gestartet hat";
CM_ SG_ 1124 PSD_Wechselverkehrszeichen_Typ "Typ des Wechselverkehrszeichen";

CM_ SG_ 1616 RA_AM_Tuning "Das Signal kennzeichnet einen aktiven AM Suchlauf. Während des Suchlaufes wird die Frequenz = 0 übertragen.
0 = frequency locked => Störquelle vermeidet die aktuelle Frequenz
1 = AM tuning in progress => Störquelle abschalten";
CM_ SG_ 1616 RA_Frequency "Übermittlung der gehörten Audiofrequenz (AM)
wird mit RA_Frequency_unit multipliziert.
Auf dem Bus werden nur eingerastete Frequenzen übertragen. Bei aktivem Tuning (RA_AM_Tuning = 1) wird 0 übertragen.";
CM_ SG_ 1616 RA_Frequency_unit "Faktor für RA_Frequency
bei AM: Faktor 0 = 1kHz
sonst   Faktor 1 = 100kHz

";
CM_ SG_ 1616 RA_PowerAmpOn "1 = Request for Amplifier; 0 = Amplifier mute/off";
CM_ SG_ 1616 RA_Radio_Error_Flag "1 = mindestens ein Kundendienstfehlerspeicher Eintrag vorhanden";
CM_ SG_ 1616 RA_Radio_mute "1=Radio is muted for telephone";
CM_ SG_ 1616 RA_Radio_on "1 = user perceived On";
CM_ SG_ 1616 RA_Radio_Surround "1 = Surround ON; 0 = Surround OFF
requests the Amp to switch Surroundmode";
CM_ SG_ 1616 RA_VNC_OFF "VNC = Vehicle Noice Cancellation;
1 = VNC OFF; 0 = VNC ON
requests the Amp to switch VNC off";

CM_ SG_ 695 RCTA_01_BZ "4bit-Botschaftszaehler, wird in jeder Sendebotschaft inkrementiert";
CM_ SG_ 695 RCTA_01_CRC "Für MLB:
'Berechnung siehe Lastenheft 'Kommunikationsabsicherung für FlexRay und CAN''

Ab MQB und MLBevo:
'Berechnung siehe Lastenheft 'End-to-End Kommunikationsabsicherung''

Endwerte siehe Begleitdokument 'S-PDU Kennungsfolgen'";
CM_ SG_ 695 RCTA_Anf_Warnruck "Mit diesem Signal wird beim ESC ein Warnruck angefordert. Über die Belegung wird die Stärke des Rucks ausgewählt.";
CM_ SG_ 695 RCTA_Anforderung_HMS "Nach einer Notbremsung durch RCTA muss das Fahrzeug halten. Deshalb ist eine HMS-Anforderung mit der Notbremsung erforderlich.";
CM_ SG_ 695 RCTA_Bremsruck_Anforderung "RCTA_Bremsruck_Anforderung  ist die Anforderung an das Bremssystem einen kurzen Bremsruck auszuführen. Mit dem Signal 'RCTA_Bremsruck_Freigabe' zusammen wird der Ruck ausgeführt. Dadurch soll der Fahrer auf eine mögliche Kollision hingewiesen und zum Brem";
CM_ SG_ 695 RCTA_Bremsruck_Freigabe "RCTA_Bremsruck_Freigabe ist die eigentliche Auforderung (mit dem Signal 'RCTA_Bremsruck_Anforderung') an das Bremssystem einen kurzen Bremsruck auszuführen. Dadurch soll der Fahrer auf eine mögliche Kollision hingewiesen und zum Bremsen animiert werden.";
CM_ SG_ 695 RCTA_Info_links "Das alte RCTA_Info wird aufgeteilt in RCTA_Info_links und RCTA_Info_rechts. Damit sollen Richtungsblinken oder ähnliches aufgrund der RCTA-Funtkion möglich gemacht werden.

Dieser Parameter ist eine zusätzliche Information zu RCTA. Andere Systeme können";
CM_ SG_ 695 RCTA_Info_rechts "Das alte RCTA_Info wird aufgeteilt in RCTA_Info_links und RCTA_Info_rechts. Damit sollen Richtungsblinken oder ähnliches aufgrund der RCTA-Funtkion möglich gemacht werden.

Dieser Parameter ist eine zusätzliche Information zu RCTA. Andere Systeme können";
CM_ SG_ 695 RCTA_Kritikalitaetslevel_links "Mit dem Signal wird das Kritikalitätslevel der Funktion RCTA dargestellt.
Je höher das Kritikalitätslevel ist, je höher die Crashwahrscheinlichkeit.
Die Kritikalität ist nicht bewertbar, wenn
-	die Funktion im Anhängerbetrieb ist
-	die Sensorsicht blo";
CM_ SG_ 695 RCTA_Kritikalitaetslevel_rechts "Mit dem Signal wird das Kritikalitätslevel der Funktion RCTA dargestellt.
Je höher das Kritikalitätslevel ist, je höher die Crashwahrscheinlichkeit.
Die Kritikalität ist nicht bewertbar, wenn
-	die Funktion im Anhängerbetrieb ist
-	die Sensorsicht blo";
CM_ SG_ 695 RCTA_Modus "gibt die Verfügbarkeit der RCTA Modus an";
CM_ SG_ 695 RCTA_Notbremsung_Anforderung "RCTA_Notbremsung_Anforderung  ist die Anforderung der Funktion RCTA an das Bremssystem. Mit dem Signal 'Notbremsung_Freigabe' zusammen wird die Bremsung eingeleitet. Dadurch sollen größere Schäden am Fahrzeug verhindert werden.";
CM_ SG_ 695 RCTA_Notbremsung_Freigabe "RCTA_Notbremsung_Freigabe ist die eigentliche Auforderung (mit dem Signal 'Notbremsung_Anforderung_Wert') an das Bremssystem eine Notfallbremsung einzuleiten. Dadurch sollen größere Schäden am Fahrzeug vermieden werden.";
CM_ SG_ 695 RCTA_Status "RCTA_Status ist die Rückmeldung, ob das System überhaupt aktiv ist. Mögliche Zustände sind: Das System ist aus; Das System ist nur passiv (läuft, ist aber ohne Funktionalität); Das System ist aktiv; Das System ist fehlerhaft";
CM_ SG_ 695 RCTA_Warnton "Ansteuerung APS Tongeber für  Warnton von RCTA. (Dauerton)";

CM_ SG_ 2589283632 RDK_Diff_Druck_HL "Differenzdruck zwischen Ist- und Solldruck HL, normiert auf 20°C";
CM_ SG_ 2589283632 RDK_Diff_Druck_HR "Differenzdruck zwischen Ist- und Solldruck HR, normiert auf 20°C";
CM_ SG_ 2589283632 RDK_Diff_Druck_VL "Differenzdruck zwischen Ist- und Solldruck VL, normiert auf 20°C";
CM_ SG_ 2589283632 RDK_Diff_Druck_VR "Differenzdruck zwischen Ist- und Solldruck VL, normiert auf 20°C";
CM_ SG_ 2589283632 RDK_Reifengroesse "Ausgabe der Reifengröße (Hinterachse)";
CM_ SG_ 2589283632 RDK_Reifentyp "Ausgabe von Reifentyp";
CM_ SG_ 2589283632 RDK_SollDruck_HA "Solldruck hinten";
CM_ SG_ 2589283632 RDK_SollDruck_VA "Solldruck vorne";

CM_ SG_ 1711 RV_Dark_Screen "Verdunkelungsanforderung Kamerabild";
CM_ SG_ 1711 RV_Farbe "Istwert fuer Farbe (in Prozent)";
CM_ SG_ 1711 RV_Helligkeit "Istwert fuer Helligkeit (in Prozent)";
CM_ SG_ 1711 RV_HMI_Mode "Aktueller Wert für den HMI-Modus

";
CM_ SG_ 1711 RV_Kontrast "Istwert fuer Kontrast (in Prozent)";
CM_ SG_ 1711 RV_Menu_Item "Ausgewähltes Menü-Item
";
CM_ SG_ 1711 RV_Reinigung_Anf "Anforderung Reinigung der Rückfahrkamera";
CM_ SG_ 1711 RV_Settings_enabled "Menü 'Einstellungen'
";
CM_ SG_ 1711 RV_System_aktiv "Systemstatus (Initialisierungsphase)
";
CM_ SG_ 1711 RV_Video_on "Anzeige Kamerabild
";
CM_ SG_ 1711 SV_Video_on "Aufschaltaufforderung SideView";
CM_ SG_ 1711 ZFAS_Umfeldbeleuchtung_Anf "Anforderung für die Aktivierung einer Umfeldbeleuchtung zur Unterstützung des Umfeldkamerasystems bei Dunkelheit";
BA_DEF_REL_ BU_SG_REL_  "GenSigTimeoutTime" INT 0 65535;
BA_DEF_ BO_  "DiagRequest" ENUM "No", "Yes";
BA_DEF_ BO_  "DiagResponse" ENUM "No", "Yes";
BA_DEF_ BO_  "DiagState" ENUM "No", "Yes";
BA_DEF_ BO_  "GenMsgChkConstant" HEX 0 4095;
BA_DEF_ BO_  "GenMsgCycleTime" INT 0 65535;
BA_DEF_ BO_  "GenMsgCycleTimeFast" INT 0 65535;
BA_DEF_ BO_  "GenMsgDelayTime" INT 0 100000;
BA_DEF_ BO_  "GenMsgILSupport" ENUM "No", "Yes";
BA_DEF_ BO_  "GenMsgNrOfRepetition" INT 0 100;
BA_DEF_ BO_  "GenMsgPDUConstants" STRING;
BA_DEF_ BO_  "GenMsgSendType" ENUM "Cyclic", "not_used", "not_used", "not_used", "not_used", "not_used", "not_used", "IfActive", "NoMsgSendType";
BA_DEF_ BO_  "GenMsgStartDelayTime" INT 0 100000;
BA_DEF_ BO_  "NmMessage" ENUM "No", "Yes";
BA_DEF_ BO_  "NmhMessage" ENUM "No", "Yes";
BA_DEF_ BO_  "MsgType" ENUM "Application", "NM ", "NMH", "TP2.0", "ISO-TP ", "BAP", "EID", "KS";
BA_DEF_ BO_  "VAGTP20_API" HEX 0 255;
BA_DEF_ BO_  "VAGTP20_DynConnection" ENUM "No", "Yes";
BA_DEF_ BO_  "VAGTP20_DynSetup" ENUM "No", "Yes";
BA_DEF_ BO_  "VAGTP20_StatConnection" ENUM "No", "Yes";
BA_DEF_ SG_  "GenSigActiveRepetitions" INT -2147483648 2147483647;
BA_DEF_ SG_  "GenSigInactiveValue" INT -2147483648 2147483647;
BA_DEF_ SG_  "GenSigSendType" ENUM "Cyclic", "OnWrite", "OnWriteWithRepetition", "OnChange", "OnChangeWithRepetition", "IfActive", "IfActiveWithRepetition", "NoSigSendType", "OnChangeAndIfActive", "OnChangeAndIfActiveWithRepetition";
BA_DEF_ SG_  "GenSigStartValue" INT -2147483648 2147483647;
BA_DEF_ SG_  "NWM-WakeupAllowed" ENUM "No", "Yes";
BA_DEF_ SG_  "GenSigFuncType" ENUM "NoFunction", "MsgCounter", "CRC-8", "XOR", "XOR-2", "DatedBit", "SW-Kl15", "CHK", "Constant", "Protocol", "CRC-8-SAE_J1850";
BA_DEF_ SG_  "GenSigSwitchedByIgnition" ENUM "No", "Yes";
BA_DEF_ SG_  "Fehlerwert" HEX 0 2147483647;
BA_DEF_ SG_  "GenSigMissingSourceValue" HEX 0 2147483647;
BA_DEF_DEF_REL_  "GenSigTimeoutTime" 0;
BA_DEF_DEF_  "DiagRequest" "No";
BA_DEF_DEF_  "DiagResponse" "No";
BA_DEF_DEF_  "DiagState" "No";
BA_DEF_DEF_  "GenMsgChkConstant" 0;
BA_DEF_DEF_  "GenMsgCycleTime" 0;
BA_DEF_DEF_  "GenMsgCycleTimeFast" 0;
BA_DEF_DEF_  "GenMsgDelayTime" 0;
BA_DEF_DEF_  "GenMsgILSupport" "No";
BA_DEF_DEF_  "GenMsgNrOfRepetition" 0;
BA_DEF_DEF_  "GenMsgPDUConstants" "";
BA_DEF_DEF_  "GenMsgSendType" "NoMsgSendType";
BA_DEF_DEF_  "GenMsgStartDelayTime" 0;
BA_DEF_DEF_  "NmMessage" "No";
BA_DEF_DEF_  "NmhMessage" "No";
BA_DEF_DEF_  "MsgType" "Application";
BA_DEF_DEF_  "VAGTP20_API" 0;
BA_DEF_DEF_  "VAGTP20_DynConnection" "No";
BA_DEF_DEF_  "VAGTP20_DynSetup" "No";
BA_DEF_DEF_  "VAGTP20_StatConnection" "No";
BA_DEF_DEF_  "GenSigActiveRepetitions" 0;
BA_DEF_DEF_  "GenSigInactiveValue" 0;
BA_DEF_DEF_  "GenSigSendType" "NoSigSendType";
BA_DEF_DEF_  "GenSigStartValue" 0;
BA_DEF_DEF_  "NWM-WakeupAllowed" "No";
BA_DEF_DEF_  "GenSigFuncType" "NoFunction";
BA_DEF_DEF_  "GenSigSwitchedByIgnition" "Yes";
BA_DEF_DEF_  "Fehlerwert" 0;
BA_DEF_DEF_  "GenSigMissingSourceValue" 0;
BA_ "GenMsgCycleTime" BO_ 1377 200;
BA_ "GenMsgDelayTime" BO_ 1377 40;
BA_ "GenMsgILSupport" BO_ 1377 1;
BA_ "GenMsgSendType" BO_ 1377 0;
BA_ "GenMsgCycleTime" BO_ 1635 100;
BA_ "GenMsgILSupport" BO_ 1635 1;
BA_ "GenMsgSendType" BO_ 1635 0;
BA_ "GenMsgStartDelayTime" BO_ 1635 10;
BA_ "GenMsgCycleTime" BO_ 2527679508 100;
BA_ "GenMsgDelayTime" BO_ 2527679508 80;
BA_ "GenMsgILSupport" BO_ 2527679508 1;
BA_ "GenMsgPDUConstants" BO_ 2527679508 "0xa3,0xed,0x65,0xcf,0xc5,0x26,0x54,0x1a,0x99,0x3c,0x01,0x84,0xf4,0x46,0x9c,0x28";
BA_ "GenMsgSendType" BO_ 2527679508 0;
BA_ "GenMsgCycleTime" BO_ 913 80;
BA_ "GenMsgILSupport" BO_ 913 1;
BA_ "GenMsgSendType" BO_ 913 0;
BA_ "MsgType" BO_ 2549875214 4;
BA_ "MsgType" BO_ 2550006286 4;
BA_ "MsgType" BO_ 2549940736 4;
BA_ "MsgType" BO_ 2549875270 4;
BA_ "MsgType" BO_ 2550006342 4;
BA_ "MsgType" BO_ 2549875330 4;
BA_ "MsgType" BO_ 2550006402 4;
BA_ "MsgType" BO_ 2549875331 4;
BA_ "MsgType" BO_ 2550006403 4;
BA_ "MsgType" BO_ 2549875350 4;
BA_ "MsgType" BO_ 2550006422 4;
BA_ "MsgType" BO_ 2549875351 4;
BA_ "MsgType" BO_ 2550006423 4;
BA_ "MsgType" BO_ 2549875289 4;
BA_ "MsgType" BO_ 2550006361 4;
BA_ "MsgType" BO_ 2549875396 4;
BA_ "MsgType" BO_ 2550006468 4;
BA_ "MsgType" BO_ 2549875397 4;
BA_ "MsgType" BO_ 2550006469 4;
BA_ "GenMsgCycleTime" BO_ 2589283656 960;
BA_ "GenMsgDelayTime" BO_ 2589283656 160;
BA_ "GenMsgILSupport" BO_ 2589283656 1;
BA_ "GenMsgSendType" BO_ 2589283656 0;
BA_ "GenMsgCycleTime" BO_ 872 100;
BA_ "GenMsgDelayTime" BO_ 872 40;
BA_ "GenMsgILSupport" BO_ 872 1;
BA_ "GenMsgSendType" BO_ 872 0;
BA_ "GenMsgCycleTime" BO_ 1175 100;
BA_ "GenMsgDelayTime" BO_ 1175 50;
BA_ "GenMsgILSupport" BO_ 1175 1;
BA_ "GenMsgSendType" BO_ 1175 0;
BA_ "GenMsgCycleTimeFast" BO_ 1353 100;
BA_ "GenMsgILSupport" BO_ 1353 1;
BA_ "GenMsgSendType" BO_ 1353 7;
BA_ "GenMsgCycleTimeFast" BO_ 1354 100;
BA_ "GenMsgILSupport" BO_ 1354 1;
BA_ "GenMsgSendType" BO_ 1354 7;
BA_ "GenMsgCycleTime" BO_ 1355 500;
BA_ "GenMsgDelayTime" BO_ 1355 20;
BA_ "GenMsgILSupport" BO_ 1355 1;
BA_ "GenMsgSendType" BO_ 1355 0;
BA_ "GenMsgCycleTime" BO_ 803 200;
BA_ "GenMsgDelayTime" BO_ 803 20;
BA_ "GenMsgILSupport" BO_ 803 1;
BA_ "GenMsgPDUConstants" BO_ 803 "0xa4,0x8b,0xda,0x66,0xdf,0x26,0xe0,0x4a,0x17,0x4d,0xbf,0xe3,0x47,0x2f,0x2a,0x06";
BA_ "GenMsgSendType" BO_ 803 0;
BA_ "GenMsgCycleTime" BO_ 2527679498 1000;
BA_ "GenMsgCycleTimeFast" BO_ 2527679498 200;
BA_ "GenMsgDelayTime" BO_ 2527679498 50;
BA_ "GenMsgILSupport" BO_ 2527679498 1;
BA_ "GenMsgNrOfRepetition" BO_ 2527679498 3;
BA_ "GenMsgSendType" BO_ 2527679498 0;
BA_ "GenMsgChkConstant" BO_ 304 49;
BA_ "GenMsgCycleTime" BO_ 304 1000;
BA_ "GenMsgCycleTimeFast" BO_ 304 20;
BA_ "GenMsgDelayTime" BO_ 304 20;
BA_ "GenMsgILSupport" BO_ 304 1;
BA_ "GenMsgNrOfRepetition" BO_ 304 5;
BA_ "GenMsgPDUConstants" BO_ 304 "0x31,0x31,0x31,0x31,0x31,0x31,0x31,0x31,0x31,0x31,0x31,0x31,0x31,0x31,0x31,0x31";
BA_ "GenMsgSendType" BO_ 304 0;
BA_ "GenMsgCycleTime" BO_ 342 1000;
BA_ "GenMsgCycleTimeFast" BO_ 342 20;
BA_ "GenMsgDelayTime" BO_ 342 20;
BA_ "GenMsgILSupport" BO_ 342 1;
BA_ "GenMsgNrOfRepetition" BO_ 342 5;
BA_ "GenMsgPDUConstants" BO_ 342 "0xdf,0xbd,0x46,0x8e,0x30,0x7b,0x91,0x1e,0x87,0x39,0x88,0xb3,0x0a,0xd7,0xce,0x75";
BA_ "GenMsgSendType" BO_ 342 0;
BA_ "GenMsgCycleTime" BO_ 1166 100;
BA_ "GenMsgILSupport" BO_ 1166 1;
BA_ "GenMsgSendType" BO_ 1166 0;
BA_ "GenMsgCycleTime" BO_ 319 200;
BA_ "GenMsgDelayTime" BO_ 319 20;
BA_ "GenMsgILSupport" BO_ 319 1;
BA_ "GenMsgPDUConstants" BO_ 319 "0x28,0x6e,0x5a,0xc6,0x52,0x65,0x85,0xa1,0xb8,0xe6,0x38,0x88,0xf8,0xb9,0x2b,0xb0";
BA_ "GenMsgSendType" BO_ 319 0;
BA_ "GenMsgCycleTime" BO_ 1122 150;
BA_ "GenMsgILSupport" BO_ 1122 1;
BA_ "GenMsgSendType" BO_ 1122 0;
BA_ "GenMsgCycleTime" BO_ 1123 150;
BA_ "GenMsgILSupport" BO_ 1123 1;
BA_ "GenMsgSendType" BO_ 1123 0;
BA_ "GenMsgCycleTime" BO_ 1124 150;
BA_ "GenMsgILSupport" BO_ 1124 1;
BA_ "GenMsgSendType" BO_ 1124 0;
BA_ "GenMsgCycleTime" BO_ 1616 1000;
BA_ "GenMsgDelayTime" BO_ 1616 50;
BA_ "GenMsgILSupport" BO_ 1616 1;
BA_ "GenMsgSendType" BO_ 1616 0;
BA_ "GenMsgCycleTime" BO_ 695 50;
BA_ "GenMsgILSupport" BO_ 695 1;
BA_ "GenMsgPDUConstants" BO_ 695 "0x5e,0xc7,0x04,0x11,0x4d,0x27,0x0d,0x31,0x91,0xb8,0x62,0x76,0x64,0x09,0xeb,0xec";
BA_ "GenMsgSendType" BO_ 695 0;
BA_ "GenMsgCycleTime" BO_ 2589283632 800;
BA_ "GenMsgILSupport" BO_ 2589283632 1;
BA_ "GenMsgSendType" BO_ 2589283632 0;
BA_ "GenMsgCycleTime" BO_ 1711 1000;
BA_ "GenMsgDelayTime" BO_ 1711 100;
BA_ "GenMsgILSupport" BO_ 1711 1;
BA_ "GenMsgSendType" BO_ 1711 0;
BA_ "GenSigSendType" SG_ 1377 NV_MessZeitpunkt 0;
BA_ "GenSigStartValue" SG_ 1377 NV_MessZeitpunkt 8191;
BA_ "GenSigSendType" SG_ 1377 NV_NichtVerfuegbar 0;
BA_ "GenSigStartValue" SG_ 1377 NV_NichtVerfuegbar 1;
BA_ "GenSigSendType" SG_ 1377 NV_Obj_01_InvTTCBildebStdA 0;
BA_ "GenSigStartValue" SG_ 1377 NV_Obj_01_InvTTCBildebStdA 127;
BA_ "GenSigSendType" SG_ 1377 NV_Obj_01_Klasse 3;
BA_ "GenSigStartValue" SG_ 1377 NV_Obj_01_Klasse 15;
BA_ "GenSigSendType" SG_ 1377 NV_Obj_Links 3;
BA_ "GenSigSendType" SG_ 1377 NV_Obj_Rechts 3;
BA_ "GenSigSendType" SG_ 1377 NV_Obj_Warnung_Fussgaenger 3;
BA_ "GenSigSendType" SG_ 1377 NV_Sensor_PositionX 0;
BA_ "GenSigStartValue" SG_ 1377 NV_Sensor_PositionX 4095;
BA_ "GenSigSendType" SG_ 1377 NV_Sensor_PositionY 0;
BA_ "GenSigStartValue" SG_ 1377 NV_Sensor_PositionY 2047;
BA_ "GenSigSendType" SG_ 1377 NV_Sensor_PositionZ 0;
BA_ "GenSigStartValue" SG_ 1377 NV_Sensor_PositionZ 2047;
BA_ "GenSigSendType" SG_ 1635 BEM_02_Abschaltstufen 0;
BA_ "GenSigSwitchedByIgnition" SG_ 1635 BEM_02_Abschaltstufen 0;
BA_ "GenSigSendType" SG_ 1635 BEM_Anf_KL15_schalten 0;
BA_ "GenSigSwitchedByIgnition" SG_ 1635 BEM_Anf_KL15_schalten 0;
BA_ "GenSigSendType" SG_ 1635 BEM_Batteriediagnose 0;
BA_ "GenSigSwitchedByIgnition" SG_ 1635 BEM_Batteriediagnose 0;
BA_ "Fehlerwert" SG_ 1635 BEM_Batteriediagnose 7;
BA_ "GenSigSendType" SG_ 1635 BEM_Generatordiagnose 0;
BA_ "GenSigSwitchedByIgnition" SG_ 1635 BEM_Generatordiagnose 0;
BA_ "GenSigSendType" SG_ 1635 BEM_HL_Regelung_Status 0;
BA_ "GenSigSwitchedByIgnition" SG_ 1635 BEM_HL_Regelung_Status 0;
BA_ "GenSigSendType" SG_ 1635 BEM_Ladezustand 0;
BA_ "GenSigStartValue" SG_ 1635 BEM_Ladezustand 14;
BA_ "GenSigSwitchedByIgnition" SG_ 1635 BEM_Ladezustand 0;
BA_ "Fehlerwert" SG_ 1635 BEM_Ladezustand 15;
BA_ "GenSigSendType" SG_ 1635 BEM_MMI_Vorwarnung 0;
BA_ "GenSigSwitchedByIgnition" SG_ 1635 BEM_MMI_Vorwarnung 0;
BA_ "GenSigSendType" SG_ 1635 BEM_Red_Innengeblaese 0;
BA_ "GenSigSwitchedByIgnition" SG_ 1635 BEM_Red_Innengeblaese 0;
BA_ "GenSigSendType" SG_ 1635 BEM_REK_aktiv 0;
BA_ "GenSigSwitchedByIgnition" SG_ 1635 BEM_REK_aktiv 0;
BA_ "GenSigSendType" SG_ 1635 BEM_STH_Einschaltverbot 0;
BA_ "GenSigSwitchedByIgnition" SG_ 1635 BEM_STH_Einschaltverbot 0;
BA_ "GenSigSendType" SG_ 1635 BEM_STH_Zielzeit 0;
BA_ "GenSigStartValue" SG_ 1635 BEM_STH_Zielzeit 14;
BA_ "GenSigSwitchedByIgnition" SG_ 1635 BEM_STH_Zielzeit 0;
BA_ "Fehlerwert" SG_ 1635 BEM_STH_Zielzeit 15;
BA_ "GenSigSendType" SG_ 1635 BEM_UBDM 0;
BA_ "GenSigSwitchedByIgnition" SG_ 1635 BEM_UBDM 0;
BA_ "Fehlerwert" SG_ 1635 BEM_UBDM 255;
BA_ "GenSigSendType" SG_ 1635 BEM_UGenSoll 0;
BA_ "GenSigSwitchedByIgnition" SG_ 1635 BEM_UGenSoll 0;
BA_ "GenSigSendType" SG_ 1635 MIB_Stromsparmodus 0;
BA_ "GenSigSwitchedByIgnition" SG_ 1635 MIB_Stromsparmodus 0;
BA_ "GenSigSendType" SG_ 1635 NVEM_Anf_SD_schalten 0;
BA_ "GenSigSwitchedByIgnition" SG_ 1635 NVEM_Anf_SD_schalten 0;
BA_ "GenSigSendType" SG_ 1635 NVEM_Batterie_Service 0;
BA_ "GenSigSwitchedByIgnition" SG_ 1635 NVEM_Batterie_Service 0;
BA_ "GenSigSendType" SG_ 1635 NVEM_Freigabe_OnlineUpdate 0;
BA_ "GenSigSwitchedByIgnition" SG_ 1635 NVEM_Freigabe_OnlineUpdate 0;
BA_ "GenSigSendType" SG_ 1635 NVEM_Freigabe_ORU4 0;
BA_ "GenSigSwitchedByIgnition" SG_ 1635 NVEM_Freigabe_ORU4 0;
BA_ "GenSigSendType" SG_ 1635 NVEM_Last_Anf 0;
BA_ "GenSigSwitchedByIgnition" SG_ 1635 NVEM_Last_Anf 0;
BA_ "GenSigSendType" SG_ 2527679508 NVEM_06_BZ 0;
BA_ "GenSigFuncType" SG_ 2527679508 NVEM_06_BZ 1;
BA_ "GenSigSwitchedByIgnition" SG_ 2527679508 NVEM_06_BZ 0;
BA_ "GenSigSendType" SG_ 2527679508 NVEM_06_CRC 0;
BA_ "GenSigFuncType" SG_ 2527679508 NVEM_06_CRC 2;
BA_ "GenSigSwitchedByIgnition" SG_ 2527679508 NVEM_06_CRC 0;
BA_ "GenSigSendType" SG_ 2527679508 NVEM_Bordnetzdiagnose 0;
BA_ "GenSigSwitchedByIgnition" SG_ 2527679508 NVEM_Bordnetzdiagnose 0;
BA_ "GenSigSendType" SG_ 2527679508 NVEM_Energie_Klima_Vorgabe 0;
BA_ "GenSigStartValue" SG_ 2527679508 NVEM_Energie_Klima_Vorgabe 254;
BA_ "GenSigSwitchedByIgnition" SG_ 2527679508 NVEM_Energie_Klima_Vorgabe 0;
BA_ "Fehlerwert" SG_ 2527679508 NVEM_Energie_Klima_Vorgabe 255;
BA_ "GenSigSendType" SG_ 2527679508 NVEM_Max_Rampenzeit 0;
BA_ "GenSigStartValue" SG_ 2527679508 NVEM_Max_Rampenzeit 6;
BA_ "GenSigSwitchedByIgnition" SG_ 2527679508 NVEM_Max_Rampenzeit 0;
BA_ "GenSigSendType" SG_ 2527679508 NVEM_Max_Spannung 0;
BA_ "GenSigStartValue" SG_ 2527679508 NVEM_Max_Spannung 126;
BA_ "GenSigSwitchedByIgnition" SG_ 2527679508 NVEM_Max_Spannung 0;
BA_ "Fehlerwert" SG_ 2527679508 NVEM_Max_Spannung 127;
BA_ "GenSigSendType" SG_ 2527679508 NVEM_Min_Spannung 0;
BA_ "GenSigStartValue" SG_ 2527679508 NVEM_Min_Spannung 126;
BA_ "GenSigSwitchedByIgnition" SG_ 2527679508 NVEM_Min_Spannung 0;
BA_ "Fehlerwert" SG_ 2527679508 NVEM_Min_Spannung 127;
BA_ "GenSigSendType" SG_ 2527679508 NVEM_Min_Spannung_Start 3;
BA_ "GenSigStartValue" SG_ 2527679508 NVEM_Min_Spannung_Start 62;
BA_ "GenSigSwitchedByIgnition" SG_ 2527679508 NVEM_Min_Spannung_Start 0;
BA_ "Fehlerwert" SG_ 2527679508 NVEM_Min_Spannung_Start 63;
BA_ "GenSigSendType" SG_ 2527679508 NVEM_MV_DC_uMinLV 0;
BA_ "GenSigStartValue" SG_ 2527679508 NVEM_MV_DC_uMinLV 126;
BA_ "GenSigSwitchedByIgnition" SG_ 2527679508 NVEM_MV_DC_uMinLV 0;
BA_ "Fehlerwert" SG_ 2527679508 NVEM_MV_DC_uMinLV 127;
BA_ "GenSigSendType" SG_ 2527679508 NVEM_MV_DC_uSollLV 0;
BA_ "GenSigStartValue" SG_ 2527679508 NVEM_MV_DC_uSollLV 126;
BA_ "GenSigSwitchedByIgnition" SG_ 2527679508 NVEM_MV_DC_uSollLV 0;
BA_ "Fehlerwert" SG_ 2527679508 NVEM_MV_DC_uSollLV 127;
BA_ "GenSigSendType" SG_ 913 MO_QBit_Aussen_Temp 0;
BA_ "GenSigStartValue" SG_ 913 MO_QBit_Aussen_Temp 1;
BA_ "GenSigSwitchedByIgnition" SG_ 913 MO_QBit_Aussen_Temp 0;
BA_ "GenSigSendType" SG_ 913 MO_Servicemodus 0;
BA_ "GenSigSwitchedByIgnition" SG_ 913 MO_Servicemodus 0;
BA_ "GenSigSendType" SG_ 913 OBD_Abs_Load_Val 0;
BA_ "GenSigStartValue" SG_ 913 OBD_Abs_Load_Val 65535;
BA_ "GenSigSwitchedByIgnition" SG_ 913 OBD_Abs_Load_Val 0;
BA_ "GenSigSendType" SG_ 913 OBD_Abs_Pedal_Pos 0;
BA_ "GenSigStartValue" SG_ 913 OBD_Abs_Pedal_Pos 255;
BA_ "GenSigSwitchedByIgnition" SG_ 913 OBD_Abs_Pedal_Pos 0;
BA_ "GenSigSendType" SG_ 913 OBD_Abs_Throttle_Pos 0;
BA_ "GenSigStartValue" SG_ 913 OBD_Abs_Throttle_Pos 255;
BA_ "GenSigSwitchedByIgnition" SG_ 913 OBD_Abs_Throttle_Pos 0;
BA_ "GenSigSendType" SG_ 913 OBD_Calc_Load_Val 0;
BA_ "GenSigStartValue" SG_ 913 OBD_Calc_Load_Val 255;
BA_ "GenSigSwitchedByIgnition" SG_ 913 OBD_Calc_Load_Val 0;
BA_ "GenSigSendType" SG_ 913 OBD_ClearMem_Inhibit 0;
BA_ "GenSigSwitchedByIgnition" SG_ 913 OBD_ClearMem_Inhibit 0;
BA_ "GenSigSendType" SG_ 913 OBD_Driving_Cycle 0;
BA_ "GenSigSwitchedByIgnition" SG_ 913 OBD_Driving_Cycle 0;
BA_ "GenSigSendType" SG_ 913 OBD_Eng_Cool_Temp 0;
BA_ "GenSigStartValue" SG_ 913 OBD_Eng_Cool_Temp 255;
BA_ "GenSigSwitchedByIgnition" SG_ 913 OBD_Eng_Cool_Temp 0;
BA_ "GenSigSendType" SG_ 913 OBD_Kaltstart_Denominator 0;
BA_ "GenSigSwitchedByIgnition" SG_ 913 OBD_Kaltstart_Denominator 0;
BA_ "GenSigSendType" SG_ 913 OBD_Minimum_Trip 0;
BA_ "GenSigSwitchedByIgnition" SG_ 913 OBD_Minimum_Trip 0;
BA_ "GenSigSendType" SG_ 913 OBD_Normed_Trip 0;
BA_ "GenSigSwitchedByIgnition" SG_ 913 OBD_Normed_Trip 0;
BA_ "GenSigSendType" SG_ 913 OBD_Sperrung_IUMPR 0;
BA_ "GenSigSwitchedByIgnition" SG_ 913 OBD_Sperrung_IUMPR 0;
BA_ "GenSigSendType" SG_ 913 OBD_Sperrung_Kaltstart_Denom 0;
BA_ "GenSigSwitchedByIgnition" SG_ 913 OBD_Sperrung_Kaltstart_Denom 0;
BA_ "GenSigSendType" SG_ 913 OBD_Warm_Up_Cycle 0;
BA_ "GenSigSwitchedByIgnition" SG_ 913 OBD_Warm_Up_Cycle 0;
BA_ "GenSigSendType" SG_ 2549875214 OBDC_BCM1_Req_Data 3;
BA_ "GenSigSwitchedByIgnition" SG_ 2549875214 OBDC_BCM1_Req_Data 0;
BA_ "GenSigSendType" SG_ 2550006286 OBDC_BCM1_Resp_Data 3;
BA_ "GenSigSwitchedByIgnition" SG_ 2550006286 OBDC_BCM1_Resp_Data 0;
BA_ "GenSigSendType" SG_ 2549940736 OBDC_Funktionaler_Req_All_Data 3;
BA_ "GenSigFuncType" SG_ 2549940736 OBDC_Funktionaler_Req_All_Data 9;
BA_ "GenSigSwitchedByIgnition" SG_ 2549940736 OBDC_Funktionaler_Req_All_Data 0;
BA_ "GenSigSendType" SG_ 2549875270 OBDC_Klima_Req_Data 3;
BA_ "GenSigSwitchedByIgnition" SG_ 2549875270 OBDC_Klima_Req_Data 0;
BA_ "GenSigSendType" SG_ 2550006342 OBDC_Klima_Resp_Data 3;
BA_ "GenSigSwitchedByIgnition" SG_ 2550006342 OBDC_Klima_Resp_Data 0;
BA_ "GenSigSendType" SG_ 2549875330 OBDC_LCM_L_Req_Data 3;
BA_ "GenSigSwitchedByIgnition" SG_ 2549875330 OBDC_LCM_L_Req_Data 0;
BA_ "GenSigSendType" SG_ 2550006402 OBDC_LCM_L_Resp_Data 3;
BA_ "GenSigSwitchedByIgnition" SG_ 2550006402 OBDC_LCM_L_Resp_Data 0;
BA_ "GenSigSendType" SG_ 2549875331 OBDC_LCM_R_Req_Data 3;
BA_ "GenSigSwitchedByIgnition" SG_ 2549875331 OBDC_LCM_R_Req_Data 0;
BA_ "GenSigSendType" SG_ 2550006403 OBDC_LCM_R_Resp_Data 3;
BA_ "GenSigSwitchedByIgnition" SG_ 2550006403 OBDC_LCM_R_Resp_Data 0;
BA_ "GenSigSendType" SG_ 2549875350 OBDC_LED_LM_L_Req_Data 3;
BA_ "GenSigSwitchedByIgnition" SG_ 2549875350 OBDC_LED_LM_L_Req_Data 0;
BA_ "GenSigSendType" SG_ 2550006422 OBDC_LED_LM_L_Resp_Data 3;
BA_ "GenSigSwitchedByIgnition" SG_ 2550006422 OBDC_LED_LM_L_Resp_Data 0;
BA_ "GenSigSendType" SG_ 2549875351 OBDC_LED_LM_R_Req_Data 3;
BA_ "GenSigSwitchedByIgnition" SG_ 2549875351 OBDC_LED_LM_R_Req_Data 0;
BA_ "GenSigSendType" SG_ 2550006423 OBDC_LED_LM_R_Resp_Data 3;
BA_ "GenSigSwitchedByIgnition" SG_ 2550006423 OBDC_LED_LM_R_Resp_Data 0;
BA_ "GenSigSendType" SG_ 2549875289 OBDC_Lift_Req_Data 3;
BA_ "GenSigSwitchedByIgnition" SG_ 2549875289 OBDC_Lift_Req_Data 0;
BA_ "GenSigSendType" SG_ 2550006361 OBDC_Lift_Resp_Data 3;
BA_ "GenSigSwitchedByIgnition" SG_ 2550006361 OBDC_Lift_Resp_Data 0;
BA_ "GenSigSendType" SG_ 2549875396 OBDC_VAS_L_Req_Data 3;
BA_ "GenSigSwitchedByIgnition" SG_ 2549875396 OBDC_VAS_L_Req_Data 0;
BA_ "GenSigSendType" SG_ 2550006468 OBDC_VAS_L_Resp_Data 3;
BA_ "GenSigSwitchedByIgnition" SG_ 2550006468 OBDC_VAS_L_Resp_Data 0;
BA_ "GenSigSendType" SG_ 2549875397 OBDC_VAS_R_Req_Data 3;
BA_ "GenSigSwitchedByIgnition" SG_ 2549875397 OBDC_VAS_R_Req_Data 0;
BA_ "GenSigSendType" SG_ 2550006469 OBDC_VAS_R_Resp_Data 3;
BA_ "GenSigSwitchedByIgnition" SG_ 2550006469 OBDC_VAS_R_Resp_Data 0;
BA_ "GenSigSendType" SG_ 2589283656 ORU_Status 3;
BA_ "GenSigSwitchedByIgnition" SG_ 2589283656 ORU_Status 0;
BA_ "GenSigSendType" SG_ 872 PDC2_Tonausgabe_Front 3;
BA_ "GenSigSendType" SG_ 872 PDC2_Tonausgabe_Heck 3;
BA_ "GenSigSendType" SG_ 872 PH2_Abschaltursache 3;
BA_ "GenSigSendType" SG_ 872 PH2_Anf_Audioabsenkung 3;
BA_ "GenSigSendType" SG_ 872 PH2_Anf_Verdeck 3;
BA_ "GenSigSendType" SG_ 872 PH2_defekt 3;
BA_ "GenSigSendType" SG_ 872 PH2_Display_Kundenwunsch 3;
BA_ "GenSigSendType" SG_ 872 PH2_Frequenz_hinten 3;
BA_ "GenSigSendType" SG_ 872 PH2_Frequenz_vorn 3;
BA_ "GenSigSendType" SG_ 872 PH2_gestoert 3;
BA_ "GenSigSendType" SG_ 872 PH2_Lautstaerke_hinten 3;
BA_ "GenSigSendType" SG_ 872 PH2_Lautstaerke_vorn 3;
BA_ "GenSigSendType" SG_ 872 PH2_nachtr_Stopp_An 3;
BA_ "GenSigSendType" SG_ 872 PH2_Opt_Anz_H_Hindernis 3;
BA_ "GenSigSendType" SG_ 872 PH2_Opt_Anz_V_Hindernis 3;
BA_ "GenSigSendType" SG_ 872 PH2_Opt_Anzeige_H_ein 3;
BA_ "GenSigSendType" SG_ 872 PH2_Opt_Anzeige_V_ein 3;
BA_ "GenSigSendType" SG_ 872 PH2_StartStopp_Info 3;
BA_ "GenSigSendType" SG_ 872 PH2_Stoermeldung 3;
BA_ "GenSigSendType" SG_ 872 PH2_Systemzustand 3;
BA_ "GenSigSendType" SG_ 872 PH2_Taster 3;
BA_ "Fehlerwert" SG_ 872 PH2_Taster 3;
BA_ "GenSigSendType" SG_ 872 PH2_Tongeber_H_aktiv 3;
BA_ "GenSigSendType" SG_ 872 PH2_Tongeber_H_verfuegbar 3;
BA_ "GenSigSendType" SG_ 872 PH2_Tongeber_mute 3;
BA_ "GenSigSendType" SG_ 872 PH2_Tongeber_V_aktiv 3;
BA_ "GenSigSendType" SG_ 872 PH2_Visualisierung 3;
BA_ "GenSigStartValue" SG_ 872 PH2_Visualisierung 6;
BA_ "Fehlerwert" SG_ 872 PH2_Visualisierung 7;
BA_ "GenSigSendType" SG_ 1175 PDC_Tonausgabe_Front 3;
BA_ "GenSigSendType" SG_ 1175 PDC_Tonausgabe_Heck 3;
BA_ "GenSigSendType" SG_ 1175 PH_Abschaltursache 3;
BA_ "GenSigSendType" SG_ 1175 PH_Anf_Audioabsenkung 3;
BA_ "GenSigSendType" SG_ 1175 PH_Anf_Verdeck 3;
BA_ "GenSigSendType" SG_ 1175 PH_defekt 3;
BA_ "GenSigSendType" SG_ 1175 PH_Display_Kundenwunsch 3;
BA_ "GenSigSendType" SG_ 1175 PH_Frequenz_hinten 3;
BA_ "GenSigSendType" SG_ 1175 PH_Frequenz_vorn 3;
BA_ "GenSigSendType" SG_ 1175 PH_gestoert 3;
BA_ "GenSigSendType" SG_ 1175 PH_Lautstaerke_hinten 3;
BA_ "GenSigSendType" SG_ 1175 PH_Lautstaerke_vorn 3;
BA_ "GenSigSendType" SG_ 1175 PH_nachtr_Stopp_Anf 3;
BA_ "GenSigSendType" SG_ 1175 PH_Opt_Anz_H_Hindernis 3;
BA_ "GenSigSendType" SG_ 1175 PH_Opt_Anz_V_Hindernis 3;
BA_ "GenSigSendType" SG_ 1175 PH_Opt_Anzeige_H_ein 3;
BA_ "GenSigSendType" SG_ 1175 PH_Opt_Anzeige_V_ein 3;
BA_ "GenSigSendType" SG_ 1175 PH_StartStopp_Info 3;
BA_ "GenSigSendType" SG_ 1175 PH_Stoermeldung 3;
BA_ "GenSigSendType" SG_ 1175 PH_Systemzustand 3;
BA_ "GenSigSendType" SG_ 1175 PH_Taster 3;
BA_ "Fehlerwert" SG_ 1175 PH_Taster 3;
BA_ "GenSigSendType" SG_ 1175 PH_Tongeber_H_aktiv 3;
BA_ "GenSigSendType" SG_ 1175 PH_Tongeber_H_verfuegbar 3;
BA_ "GenSigSendType" SG_ 1175 PH_Tongeber_mute 3;
BA_ "GenSigSendType" SG_ 1175 PH_Tongeber_V_aktiv 3;
BA_ "GenSigSendType" SG_ 1175 PH_Visualisierung 3;
BA_ "GenSigStartValue" SG_ 1175 PH_Visualisierung 6;
BA_ "Fehlerwert" SG_ 1175 PH_Visualisierung 7;
BA_ "GenSigSendType" SG_ 1175 PLA_Anf_Aufschaltung_RVC 3;
BA_ "GenSigSwitchedByIgnition" SG_ 1353 PL_Luecke_P0_x 0;
BA_ "GenSigSwitchedByIgnition" SG_ 1353 PL_Luecke_P0_y 0;
BA_ "GenSigSwitchedByIgnition" SG_ 1353 PL_Luecke_P2_x 0;
BA_ "GenSigSwitchedByIgnition" SG_ 1353 PL_Luecke_P2_y 0;
BA_ "GenSigSwitchedByIgnition" SG_ 1354 PL_Luecke_P1_x 0;
BA_ "GenSigSwitchedByIgnition" SG_ 1354 PL_Luecke_P1_y 0;
BA_ "GenSigSwitchedByIgnition" SG_ 1354 PL_Luecke_P3_x 0;
BA_ "GenSigSwitchedByIgnition" SG_ 1354 PL_Luecke_P3_y 0;
BA_ "GenSigSendType" SG_ 1355 BCM_WAH_Meldung 3;
BA_ "GenSigSendType" SG_ 1355 PDC_Charisma_FahrPr 3;
BA_ "GenSigSendType" SG_ 1355 PDC_Charisma_Status 3;
BA_ "GenSigSendType" SG_ 1355 PH_Aufschaltursache 3;
BA_ "GenSigSendType" SG_ 1355 PH_Ton_Ausgabe 3;
BA_ "Fehlerwert" SG_ 1355 PH_Ton_Ausgabe 7;
BA_ "GenSigSendType" SG_ 1355 PH_Ton_Lautstaerke 3;
BA_ "GenSigSendType" SG_ 1355 PH_Ton_Pausenlaenge 3;
BA_ "Fehlerwert" SG_ 1355 PH_Ton_Pausenlaenge 127;
BA_ "GenSigSendType" SG_ 1355 PH_Ton_Richtung 3;
BA_ "GenSigSendType" SG_ 1355 PH_Verschmutzungsmeldung 3;
BA_ "GenSigSendType" SG_ 803 PCF_01_BZ 0;
BA_ "GenSigFuncType" SG_ 803 PCF_01_BZ 1;
BA_ "GenSigSendType" SG_ 803 PCF_01_CRC 0;
BA_ "GenSigFuncType" SG_ 803 PCF_01_CRC 2;
BA_ "GenSigSendType" SG_ 803 PCF_HBA_Param 0;
BA_ "GenSigSwitchedByIgnition" SG_ 803 PCF_HBA_Param 0;
BA_ "GenSigSendType" SG_ 803 PCF_Prefill_Anf 3;
BA_ "GenSigSwitchedByIgnition" SG_ 803 PCF_Prefill_Anf 0;
BA_ "GenSigSendType" SG_ 803 PCF_Ruckprofil 0;
BA_ "GenSigSwitchedByIgnition" SG_ 803 PCF_Ruckprofil 0;
BA_ "GenSigSendType" SG_ 803 PCF_Verz_Anf 0;
BA_ "GenSigStartValue" SG_ 803 PCF_Verz_Anf 834;
BA_ "GenSigSendType" SG_ 803 PCF_Verz_Anf_ASIL 0;
BA_ "GenSigSwitchedByIgnition" SG_ 803 PCF_Verz_Anf_ASIL 0;
BA_ "GenSigSendType" SG_ 803 PCF_Verz_Auspraegung 0;
BA_ "GenSigSwitchedByIgnition" SG_ 803 PCF_Verz_Auspraegung 0;
BA_ "GenSigSendType" SG_ 803 PCF_Verz_Info 3;
BA_ "GenSigSwitchedByIgnition" SG_ 803 PCF_Verz_Info 0;
BA_ "GenSigSendType" SG_ 803 SC_AbstWarn_Texte 0;
BA_ "GenSigSwitchedByIgnition" SG_ 803 SC_AbstWarn_Texte 0;
BA_ "GenSigSendType" SG_ 803 SC_WarnBrems_Texte 0;
BA_ "GenSigSwitchedByIgnition" SG_ 803 SC_WarnBrems_Texte 0;
BA_ "GenSigSendType" SG_ 2527679498 IAA_Active_User_ID 0;
BA_ "GenSigSwitchedByIgnition" SG_ 2527679498 IAA_Active_User_ID 0;
BA_ "GenSigSendType" SG_ 2527679498 IAA_Identified_User_ID 0;
BA_ "GenSigSwitchedByIgnition" SG_ 2527679498 IAA_Identified_User_ID 0;
BA_ "GenSigSendType" SG_ 2527679498 IAA_PSO_wake_up 0;
BA_ "GenSigSwitchedByIgnition" SG_ 2527679498 IAA_PSO_wake_up 0;
BA_ "GenSigActiveRepetitions" SG_ 2527679498 Perso_Aktiv 3;
BA_ "GenSigSendType" SG_ 2527679498 Perso_Aktiv 4;
BA_ "GenSigSwitchedByIgnition" SG_ 2527679498 Perso_Aktiv 0;
BA_ "GenSigActiveRepetitions" SG_ 2527679498 Perso_Bedienstelle 3;
BA_ "GenSigSendType" SG_ 2527679498 Perso_Bedienstelle 4;
BA_ "GenSigSwitchedByIgnition" SG_ 2527679498 Perso_Bedienstelle 0;
BA_ "GenSigActiveRepetitions" SG_ 2527679498 Perso_Fahrernummer 3;
BA_ "GenSigSendType" SG_ 2527679498 Perso_Fahrernummer 4;
BA_ "GenSigSwitchedByIgnition" SG_ 2527679498 Perso_Fahrernummer 0;
BA_ "GenSigActiveRepetitions" SG_ 2527679498 Perso_Freigabe_Verstellung 3;
BA_ "GenSigSendType" SG_ 2527679498 Perso_Freigabe_Verstellung 4;
BA_ "GenSigSwitchedByIgnition" SG_ 2527679498 Perso_Freigabe_Verstellung 0;
BA_ "GenSigActiveRepetitions" SG_ 2527679498 Perso_Kontonummer 3;
BA_ "GenSigSendType" SG_ 2527679498 Perso_Kontonummer 4;
BA_ "GenSigSwitchedByIgnition" SG_ 2527679498 Perso_Kontonummer 0;
BA_ "GenSigActiveRepetitions" SG_ 2527679498 Perso_Schreibschutz 3;
BA_ "GenSigSendType" SG_ 2527679498 Perso_Schreibschutz 4;
BA_ "GenSigSwitchedByIgnition" SG_ 2527679498 Perso_Schreibschutz 0;
BA_ "GenSigSendType" SG_ 2527679498 Perso_Status 1;
BA_ "GenSigSwitchedByIgnition" SG_ 2527679498 Perso_Status 0;
BA_ "GenSigActiveRepetitions" SG_ 2527679498 Perso_Steuerung 3;
BA_ "GenSigSendType" SG_ 2527679498 Perso_Steuerung 4;
BA_ "GenSigSwitchedByIgnition" SG_ 2527679498 Perso_Steuerung 0;
BA_ "GenSigActiveRepetitions" SG_ 2527679498 Perso_Steuerungsparameter 3;
BA_ "GenSigSendType" SG_ 2527679498 Perso_Steuerungsparameter 4;
BA_ "GenSigSwitchedByIgnition" SG_ 2527679498 Perso_Steuerungsparameter 0;
BA_ "GenSigSendType" SG_ 304 PLA_01_BZ 0;
BA_ "GenSigFuncType" SG_ 304 PLA_01_BZ 1;
BA_ "GenSigSendType" SG_ 304 PLA_01_CRC 0;
BA_ "GenSigFuncType" SG_ 304 PLA_01_CRC 2;
BA_ "GenSigActiveRepetitions" SG_ 304 PLA_01_Signal_red_cyclic 5;
BA_ "GenSigSendType" SG_ 304 PLA_01_Signal_red_cyclic 9;
BA_ "GenSigSendType" SG_ 304 PLA_Anf_Bremsverzoegerung 0;
BA_ "GenSigSendType" SG_ 304 PLA_BremsMom_Verzoeg 3;
BA_ "GenSigSendType" SG_ 304 PLA_Bremsverzoegerung 3;
BA_ "GenSigStartValue" SG_ 304 PLA_Bremsverzoegerung 126;
BA_ "Fehlerwert" SG_ 304 PLA_Bremsverzoegerung 127;
BA_ "GenSigSendType" SG_ 304 PLA_Status_PLA_EPS 0;
BA_ "GenSigStartValue" SG_ 304 PLA_Status_PLA_EPS 9;
BA_ "GenSigSendType" SG_ 304 PLA_Status_PLA_ESP 0;
BA_ "GenSigStartValue" SG_ 304 PLA_Status_PLA_ESP 9;
BA_ "GenSigSendType" SG_ 304 PLA_VZ_Zahnstangen_Pos_Soll 0;
BA_ "GenSigSendType" SG_ 304 PLA_Zahnstangen_Pos_Soll 0;
BA_ "GenSigStartValue" SG_ 304 PLA_Zahnstangen_Pos_Soll 4094;
BA_ "GenSigSendType" SG_ 342 PLA_02_BZ 0;
BA_ "GenSigFuncType" SG_ 342 PLA_02_BZ 1;
BA_ "GenSigSendType" SG_ 342 PLA_02_CRC 0;
BA_ "GenSigFuncType" SG_ 342 PLA_02_CRC 2;
BA_ "GenSigSendType" SG_ 342 PLA_02_Signal_red_cyclic 9;
BA_ "GenSigSendType" SG_ 342 PLA_HAL_Radwinkel_Soll 0;
BA_ "GenSigSendType" SG_ 342 PLA_HAL_VZ_Radwinkel_Soll 0;
BA_ "GenSigSendType" SG_ 342 PLA_maximale_Geschwindigkeit 0;
BA_ "GenSigStartValue" SG_ 342 PLA_maximale_Geschwindigkeit 251;
BA_ "Fehlerwert" SG_ 342 PLA_maximale_Geschwindigkeit 255;
BA_ "GenSigSendType" SG_ 342 PLA_Status_PLA_HAL 0;
BA_ "GenSigStartValue" SG_ 342 PLA_Status_PLA_HAL 9;
BA_ "GenSigSendType" SG_ 342 PLA_Status_PLA_TSK 0;
BA_ "GenSigStartValue" SG_ 342 PLA_Status_PLA_TSK 1;
BA_ "GenSigSendType" SG_ 1166 PLA_Anf_Akustik 0;
BA_ "GenSigSendType" SG_ 1166 PLA_Anf_Anzeige_Bremsfuss 0;
BA_ "GenSigSendType" SG_ 1166 PLA_Anf_Anzeige_Mini 0;
BA_ "GenSigSendType" SG_ 1166 PLA_Anf_Anzeige_Schwellpfeil 0;
BA_ "GenSigSendType" SG_ 1166 PLA_Anf_Anzeigemodus 0;
BA_ "GenSigSendType" SG_ 1166 PLA_Anf_Funktionsdisclaimer 0;
BA_ "GenSigSendType" SG_ 1166 PLA_Anf_Meldungen 0;
BA_ "GenSigSendType" SG_ 1166 PLA_Anforderung_HMS 0;
BA_ "GenSigSendType" SG_ 1166 PLA_Anzahl_Segmente_Schwellpfeil 0;
BA_ "GenSigSendType" SG_ 1166 PLA_Mini_Modus 0;
BA_ "GenSigSendType" SG_ 1166 PLA_Status_Aktive_Seite 0;
BA_ "GenSigSendType" SG_ 1166 PLA_Status_beenden_Mini 0;
BA_ "GenSigSendType" SG_ 1166 PLA_Status_Funktion 0;
BA_ "GenSigSendType" SG_ 1166 PLA_Status_Laengsparken_Mini 0;
BA_ "GenSigSendType" SG_ 1166 PLA_Status_QP_Rueckw_Mini 0;
BA_ "GenSigSendType" SG_ 1166 PLA_Status_QP_Vorw_Mini 0;
BA_ "GenSigSendType" SG_ 319 PreCrash_02_BZ 0;
BA_ "GenSigFuncType" SG_ 319 PreCrash_02_BZ 1;
BA_ "GenSigSendType" SG_ 319 PreCrash_02_CRC 0;
BA_ "GenSigFuncType" SG_ 319 PreCrash_02_CRC 2;
BA_ "GenSigSendType" SG_ 319 PreCrash_Anforderung_AFR 3;
BA_ "GenSigStartValue" SG_ 319 PreCrash_Anforderung_AFR 7;
BA_ "GenSigSwitchedByIgnition" SG_ 319 PreCrash_Anforderung_AFR 0;
BA_ "GenSigSendType" SG_ 319 PreCrash_BFS_KSV_verfahren 3;
BA_ "GenSigSwitchedByIgnition" SG_ 319 PreCrash_BFS_KSV_verfahren 0;
BA_ "GenSigSendType" SG_ 319 PreCrash_BFS_Pneumatik_ansteuern 3;
BA_ "GenSigSwitchedByIgnition" SG_ 319 PreCrash_BFS_Pneumatik_ansteuern 0;
BA_ "GenSigSendType" SG_ 319 PreCrash_BFS_Sitzlehne_verfahren 3;
BA_ "GenSigSwitchedByIgnition" SG_ 319 PreCrash_BFS_Sitzlehne_verfahren 0;
BA_ "GenSigSendType" SG_ 319 PreCrash_Blinken 3;
BA_ "GenSigSendType" SG_ 319 PreCrash_Charisma_FahrPr 0;
BA_ "GenSigSendType" SG_ 319 PreCrash_Charisma_Status 0;
BA_ "GenSigSendType" SG_ 319 PreCrash_Fenster_schliessen 3;
BA_ "GenSigSendType" SG_ 319 PreCrash_Fo_KSV_verfahren 3;
BA_ "GenSigSwitchedByIgnition" SG_ 319 PreCrash_Fo_KSV_verfahren 0;
BA_ "GenSigSendType" SG_ 319 PreCrash_Fo_Pneumatik_ansteuern 3;
BA_ "GenSigSwitchedByIgnition" SG_ 319 PreCrash_Fo_Pneumatik_ansteuern 0;
BA_ "GenSigSendType" SG_ 319 PreCrash_Fo_Sitzlehne_verfahren 3;
BA_ "GenSigSwitchedByIgnition" SG_ 319 PreCrash_Fo_Sitzlehne_verfahren 0;
BA_ "GenSigSendType" SG_ 319 PreCrash_FS_KSV_verfahren 3;
BA_ "GenSigSwitchedByIgnition" SG_ 319 PreCrash_FS_KSV_verfahren 0;
BA_ "GenSigSendType" SG_ 319 PreCrash_FS_Pneumatik_ansteuern 3;
BA_ "GenSigSwitchedByIgnition" SG_ 319 PreCrash_FS_Pneumatik_ansteuern 0;
BA_ "GenSigSendType" SG_ 319 PreCrash_FS_Sitzlehne_verfahren 3;
BA_ "GenSigSwitchedByIgnition" SG_ 319 PreCrash_FS_Sitzlehne_verfahren 0;
BA_ "GenSigSendType" SG_ 319 PreCrash_Schiebedach_schliessen 3;
BA_ "GenSigSendType" SG_ 319 PreCrash_Tueren_Verriegeln 3;
BA_ "GenSigSwitchedByIgnition" SG_ 319 PreCrash_Tueren_Verriegeln 0;
BA_ "GenSigSendType" SG_ 319 SC_PreCrash_LED 3;
BA_ "GenSigSwitchedByIgnition" SG_ 319 SC_PreCrash_LED 0;
BA_ "GenSigSendType" SG_ 319 SC_PreCrash_Texte 3;
BA_ "GenSigSwitchedByIgnition" SG_ 319 SC_PreCrash_Texte 0;
BA_ "GenSigSendType" SG_ 319 SC_PreCrash_Warnung 3;
BA_ "GenSigSwitchedByIgnition" SG_ 319 SC_PreCrash_Warnung 0;
BA_ "GenSigSendType" SG_ 319 SC_PreSense_FCWP 3;
BA_ "GenSigSwitchedByIgnition" SG_ 319 SC_PreSense_FCWP 0;
BA_ "GenSigSendType" SG_ 1122 PSD_Abzweigerichtung 0;
BA_ "GenSigSwitchedByIgnition" SG_ 1122 PSD_Abzweigerichtung 0;
BA_ "GenSigSendType" SG_ 1122 PSD_Abzweigewinkel 0;
BA_ "GenSigSwitchedByIgnition" SG_ 1122 PSD_Abzweigewinkel 0;
BA_ "GenSigSendType" SG_ 1122 PSD_ADAS_Qualitaet 0;
BA_ "GenSigSendType" SG_ 1122 PSD_Anfangskruemmung 0;
BA_ "GenSigSwitchedByIgnition" SG_ 1122 PSD_Anfangskruemmung 0;
BA_ "GenSigSendType" SG_ 1122 PSD_Anfangskruemmung_Vorz 0;
BA_ "GenSigSwitchedByIgnition" SG_ 1122 PSD_Anfangskruemmung_Vorz 0;
BA_ "GenSigSendType" SG_ 1122 PSD_Bebauung 0;
BA_ "GenSigSendType" SG_ 1122 PSD_Endkruemmung 0;
BA_ "GenSigSendType" SG_ 1122 PSD_Endkruemmung_Vorz 0;
BA_ "GenSigSendType" SG_ 1122 PSD_Fahrspuren_Anzahl 0;
BA_ "GenSigStartValue" SG_ 1122 PSD_Fahrspuren_Anzahl 1;
BA_ "GenSigSwitchedByIgnition" SG_ 1122 PSD_Fahrspuren_Anzahl 0;
BA_ "GenSigSendType" SG_ 1122 PSD_Geradester_Pfad 0;
BA_ "GenSigSendType" SG_ 1122 PSD_Idenditaets_ID 0;
BA_ "Fehlerwert" SG_ 1122 PSD_Idenditaets_ID 1;
BA_ "GenSigSendType" SG_ 1122 PSD_Rampe 0;
BA_ "GenSigSendType" SG_ 1122 PSD_Segment_ID 0;
BA_ "GenSigSendType" SG_ 1122 PSD_Segment_Komplett 0;
BA_ "GenSigSwitchedByIgnition" SG_ 1122 PSD_Segment_Komplett 0;
BA_ "GenSigSendType" SG_ 1122 PSD_Segmentlaenge 0;
BA_ "GenSigSendType" SG_ 1122 PSD_Strassenkategorie 0;
BA_ "GenSigStartValue" SG_ 1122 PSD_Strassenkategorie 7;
BA_ "GenSigSwitchedByIgnition" SG_ 1122 PSD_Strassenkategorie 0;
BA_ "GenSigSendType" SG_ 1122 PSD_Vorgaenger_Segment_ID 0;
BA_ "GenSigSendType" SG_ 1122 PSD_wahrscheinlichster_Pfad 0;
BA_ "GenSigSendType" SG_ 1123 PSD_Attribut_1_ID 0;
BA_ "GenSigSendType" SG_ 1123 PSD_Attribut_1_Offset 0;
BA_ "GenSigSendType" SG_ 1123 PSD_Attribut_1_Wert 0;
BA_ "GenSigSendType" SG_ 1123 PSD_Attribut_2_ID 0;
BA_ "GenSigSendType" SG_ 1123 PSD_Attribut_2_Offset 0;
BA_ "GenSigSendType" SG_ 1123 PSD_Attribut_2_Wert 0;
BA_ "GenSigSendType" SG_ 1123 PSD_Attribut_Segment_ID_05 0;
BA_ "Fehlerwert" SG_ 1123 PSD_Attribut_Segment_ID_05 1;
BA_ "GenSigSendType" SG_ 1123 PSD_Attribute_Komplett_05 0;
BA_ "GenSigSendType" SG_ 1123 PSD_Pos_Fahrspur 0;
BA_ "GenSigSendType" SG_ 1123 PSD_Pos_Fehler_Laengsrichtung 0;
BA_ "GenSigSendType" SG_ 1123 PSD_Pos_Inhibitzeit 0;
BA_ "GenSigSendType" SG_ 1123 PSD_Pos_Segment_ID 0;
BA_ "GenSigSendType" SG_ 1123 PSD_Pos_Segmentlaenge 0;
BA_ "GenSigSendType" SG_ 1123 PSD_Pos_Standort_Eindeutig 0;
BA_ "GenSigSwitchedByIgnition" SG_ 1123 PSD_Pos_Standort_Eindeutig 0;
BA_ "GenSigSendType" SG_ 1124 PSD_06_Mux 0;
BA_ "NWM-WakeupAllowed" SG_ 1124 PSD_06_Mux 1;
BA_ "GenSigSwitchedByIgnition" SG_ 1124 PSD_06_Mux 0;
BA_ "Fehlerwert" SG_ 1124 PSD_Attribut_Segment_ID 1;
BA_ "GenSigSwitchedByIgnition" SG_ 1124 PSD_Attribute_Komplett_06 0;
BA_ "GenSigStartValue" SG_ 1124 PSD_Ges_Typ 3;
BA_ "GenSigSwitchedByIgnition" SG_ 1124 PSD_Ges_Typ 0;
BA_ "GenSigSwitchedByIgnition" SG_ 1124 PSD_Steigung_1_Attribute_kompl 0;
BA_ "Fehlerwert" SG_ 1124 PSD_Steigung_1_Segment_ID 1;
BA_ "GenSigSwitchedByIgnition" SG_ 1124 PSD_Steigung_2_Attribute_kompl 0;
BA_ "Fehlerwert" SG_ 1124 PSD_Steigung_2_Segment_ID 1;
BA_ "GenSigSendType" SG_ 1616 RA_AM_Tuning 3;
BA_ "GenSigSwitchedByIgnition" SG_ 1616 RA_AM_Tuning 0;
BA_ "GenSigSendType" SG_ 1616 RA_Frequency 3;
BA_ "GenSigSwitchedByIgnition" SG_ 1616 RA_Frequency 0;
BA_ "GenSigSendType" SG_ 1616 RA_Frequency_unit 3;
BA_ "GenSigSwitchedByIgnition" SG_ 1616 RA_Frequency_unit 0;
BA_ "GenSigSendType" SG_ 1616 RA_PowerAmpOn 3;
BA_ "GenSigSwitchedByIgnition" SG_ 1616 RA_PowerAmpOn 0;
BA_ "GenSigSendType" SG_ 1616 RA_Radio_Error_Flag 3;
BA_ "GenSigSwitchedByIgnition" SG_ 1616 RA_Radio_Error_Flag 0;
BA_ "GenSigSendType" SG_ 1616 RA_Radio_mute 3;
BA_ "GenSigSwitchedByIgnition" SG_ 1616 RA_Radio_mute 0;
BA_ "GenSigSendType" SG_ 1616 RA_Radio_on 3;
BA_ "GenSigSwitchedByIgnition" SG_ 1616 RA_Radio_on 0;
BA_ "GenSigSendType" SG_ 1616 RA_Radio_Surround 3;
BA_ "GenSigSwitchedByIgnition" SG_ 1616 RA_Radio_Surround 0;
BA_ "GenSigSendType" SG_ 1616 RA_VNC_OFF 3;
BA_ "GenSigSwitchedByIgnition" SG_ 1616 RA_VNC_OFF 0;
BA_ "GenSigSendType" SG_ 695 RCTA_01_BZ 0;
BA_ "GenSigFuncType" SG_ 695 RCTA_01_BZ 1;
BA_ "GenSigSendType" SG_ 695 RCTA_01_CRC 0;
BA_ "GenSigFuncType" SG_ 695 RCTA_01_CRC 2;
BA_ "GenSigSendType" SG_ 695 RCTA_Anf_Warnruck 0;
BA_ "GenSigSendType" SG_ 695 RCTA_Anforderung_HMS 0;
BA_ "GenSigSendType" SG_ 695 RCTA_Bremsruck_Anforderung 0;
BA_ "GenSigSendType" SG_ 695 RCTA_Bremsruck_Freigabe 0;
BA_ "GenSigSendType" SG_ 695 RCTA_Info_links 0;
BA_ "GenSigSendType" SG_ 695 RCTA_Info_rechts 0;
BA_ "GenSigSendType" SG_ 695 RCTA_Kritikalitaetslevel_links 0;
BA_ "GenSigSendType" SG_ 695 RCTA_Kritikalitaetslevel_rechts 0;
BA_ "GenSigSendType" SG_ 695 RCTA_Modus 0;
BA_ "GenSigSendType" SG_ 695 RCTA_Notbremsung_Anforderung 0;
BA_ "Fehlerwert" SG_ 695 RCTA_Notbremsung_Anforderung 255;
BA_ "GenSigSendType" SG_ 695 RCTA_Notbremsung_Freigabe 0;
BA_ "GenSigSendType" SG_ 695 RCTA_Status 0;
BA_ "Fehlerwert" SG_ 695 RCTA_Status 3;
BA_ "GenSigSendType" SG_ 695 RCTA_Warnton 0;
BA_ "GenSigSendType" SG_ 2589283632 RDK_Diff_Druck_HL 0;
BA_ "GenSigSwitchedByIgnition" SG_ 2589283632 RDK_Diff_Druck_HL 0;
BA_ "GenSigSendType" SG_ 2589283632 RDK_Diff_Druck_HR 0;
BA_ "GenSigSwitchedByIgnition" SG_ 2589283632 RDK_Diff_Druck_HR 0;
BA_ "GenSigSendType" SG_ 2589283632 RDK_Diff_Druck_VL 0;
BA_ "GenSigSwitchedByIgnition" SG_ 2589283632 RDK_Diff_Druck_VL 0;
BA_ "GenSigSendType" SG_ 2589283632 RDK_Diff_Druck_VR 0;
BA_ "GenSigSwitchedByIgnition" SG_ 2589283632 RDK_Diff_Druck_VR 0;
BA_ "GenSigSendType" SG_ 2589283632 RDK_Reifengroesse 0;
BA_ "GenSigSwitchedByIgnition" SG_ 2589283632 RDK_Reifengroesse 0;
BA_ "GenSigSendType" SG_ 2589283632 RDK_Reifentyp 0;
BA_ "GenSigSendType" SG_ 2589283632 RDK_SollDruck_HA 0;
BA_ "GenSigStartValue" SG_ 2589283632 RDK_SollDruck_HA 63;
BA_ "GenSigSwitchedByIgnition" SG_ 2589283632 RDK_SollDruck_HA 0;
BA_ "GenSigSendType" SG_ 2589283632 RDK_SollDruck_VA 0;
BA_ "GenSigStartValue" SG_ 2589283632 RDK_SollDruck_VA 63;
BA_ "GenSigSwitchedByIgnition" SG_ 2589283632 RDK_SollDruck_VA 0;
BA_ "GenSigSendType" SG_ 1711 RV_Calib_Fehler 3;
BA_ "GenSigSwitchedByIgnition" SG_ 1711 RV_Calib_Fehler 0;
BA_ "GenSigSendType" SG_ 1711 RV_Dark_Screen 3;
BA_ "GenSigSwitchedByIgnition" SG_ 1711 RV_Dark_Screen 0;
BA_ "GenSigSendType" SG_ 1711 RV_Farbe 3;
BA_ "GenSigSwitchedByIgnition" SG_ 1711 RV_Farbe 0;
BA_ "GenSigSendType" SG_ 1711 RV_GL_LWS_Fehler 3;
BA_ "GenSigSwitchedByIgnition" SG_ 1711 RV_GL_LWS_Fehler 0;
BA_ "GenSigSendType" SG_ 1711 RV_GL_side 3;
BA_ "GenSigSendType" SG_ 1711 RV_GL_Trailer_connect 3;
BA_ "GenSigSwitchedByIgnition" SG_ 1711 RV_GL_Trailer_connect 0;
BA_ "GenSigSendType" SG_ 1711 RV_GL_Trunk_open 3;
BA_ "GenSigSwitchedByIgnition" SG_ 1711 RV_GL_Trunk_open 0;
BA_ "GenSigSendType" SG_ 1711 RV_Helligkeit 3;
BA_ "GenSigSwitchedByIgnition" SG_ 1711 RV_Helligkeit 0;
BA_ "GenSigSendType" SG_ 1711 RV_HMI_Mode 3;
BA_ "GenSigSwitchedByIgnition" SG_ 1711 RV_HMI_Mode 0;
BA_ "GenSigSendType" SG_ 1711 RV_Kontrast 3;
BA_ "GenSigSwitchedByIgnition" SG_ 1711 RV_Kontrast 0;
BA_ "GenSigSendType" SG_ 1711 RV_Menu_Item 3;
BA_ "GenSigSwitchedByIgnition" SG_ 1711 RV_Menu_Item 0;
BA_ "GenSigSendType" SG_ 1711 RV_Reinigung_Anf 3;
BA_ "GenSigSwitchedByIgnition" SG_ 1711 RV_Reinigung_Anf 0;
BA_ "GenSigSendType" SG_ 1711 RV_Settings_enabled 3;
BA_ "GenSigSwitchedByIgnition" SG_ 1711 RV_Settings_enabled 0;
BA_ "GenSigSendType" SG_ 1711 RV_System_aktiv 3;
BA_ "GenSigSwitchedByIgnition" SG_ 1711 RV_System_aktiv 0;
BA_ "GenSigSendType" SG_ 1711 RV_Video_on 3;
BA_ "GenSigSwitchedByIgnition" SG_ 1711 RV_Video_on 0;
BA_ "GenSigSendType" SG_ 1711 SV_Video_on 3;
BA_ "GenSigSendType" SG_ 1711 ZFAS_Umfeldbeleuchtung_Anf 3;
BA_ "GenSigSwitchedByIgnition" SG_ 1711 ZFAS_Umfeldbeleuchtung_Anf 0;
BA_REL_ "GenSigTimeoutTime" BU_SG_REL_ BCM1 SG_ 1635 BEM_02_Abschaltstufen 1000;
BA_REL_ "GenSigTimeoutTime" BU_SG_REL_ BCM1 SG_ 1635 BEM_STH_Zielzeit 1000;
BA_REL_ "GenSigTimeoutTime" BU_SG_REL_ BCM1 SG_ 1635 NVEM_Anf_SD_schalten 1000;
BA_REL_ "GenSigTimeoutTime" BU_SG_REL_ BCM1 SG_ 1635 BEM_Red_Innengeblaese 1000;
BA_REL_ "GenSigTimeoutTime" BU_SG_REL_ BCM1 SG_ 1635 BEM_STH_Einschaltverbot 1000;
BA_REL_ "GenSigTimeoutTime" BU_SG_REL_ BCM1 SG_ 1635 BEM_HL_Regelung_Status 1000;
BA_REL_ "GenSigTimeoutTime" BU_SG_REL_ BCM1 SG_ 1377 NV_Obj_Rechts 2000;
BA_REL_ "GenSigTimeoutTime" BU_SG_REL_ BCM1 SG_ 1377 NV_Obj_Links 2000;
BA_REL_ "GenSigTimeoutTime" BU_SG_REL_ BCM1 SG_ 1377 NV_Obj_01_Klasse 2000;
BA_REL_ "GenSigTimeoutTime" BU_SG_REL_ BCM1 SG_ 2527679508 NVEM_Energie_Klima_Vorgabe 1000;
BA_REL_ "GenSigTimeoutTime" BU_SG_REL_ BCM1 SG_ 2589283656 ORU_Status 5000;
BA_REL_ "GenSigTimeoutTime" BU_SG_REL_ BCM1 SG_ 872 PH2_Visualisierung 1000;
BA_REL_ "GenSigTimeoutTime" BU_SG_REL_ BCM1 SG_ 872 PH2_Abschaltursache 1000;
BA_REL_ "GenSigTimeoutTime" BU_SG_REL_ BCM1 SG_ 872 PH2_Opt_Anzeige_V_ein 1000;
BA_REL_ "GenSigTimeoutTime" BU_SG_REL_ BCM1 SG_ 872 PH2_Opt_Anzeige_H_ein 1000;
BA_REL_ "GenSigTimeoutTime" BU_SG_REL_ BCM1 SG_ 872 PH2_Opt_Anz_V_Hindernis 1000;
BA_REL_ "GenSigTimeoutTime" BU_SG_REL_ BCM1 SG_ 872 PH2_Opt_Anz_H_Hindernis 1000;
BA_REL_ "GenSigTimeoutTime" BU_SG_REL_ BCM1 SG_ 872 PH2_Systemzustand 1000;
BA_REL_ "GenSigTimeoutTime" BU_SG_REL_ BCM1 SG_ 803 PCF_Prefill_Anf 2000;
BA_REL_ "GenSigTimeoutTime" BU_SG_REL_ BCM1 SG_ 803 PCF_Verz_Info 2000;
BA_REL_ "GenSigTimeoutTime" BU_SG_REL_ BCM1 SG_ 2527679498 Perso_Kontonummer 5000;
BA_REL_ "GenSigTimeoutTime" BU_SG_REL_ BCM1 SG_ 2527679498 Perso_Steuerung 5000;
BA_REL_ "GenSigTimeoutTime" BU_SG_REL_ BCM1 SG_ 2527679498 Perso_Steuerungsparameter 5000;
BA_REL_ "GenSigTimeoutTime" BU_SG_REL_ BCM1 SG_ 2527679498 Perso_Status 5000;
BA_REL_ "GenSigTimeoutTime" BU_SG_REL_ BCM1 SG_ 319 PreCrash_FS_Pneumatik_ansteuern 2000;
BA_REL_ "GenSigTimeoutTime" BU_SG_REL_ BCM1 SG_ 319 PreCrash_BFS_Pneumatik_ansteuern 2000;
BA_REL_ "GenSigTimeoutTime" BU_SG_REL_ BCM1 SG_ 1122 PSD_Segment_ID 1500;
BA_REL_ "GenSigTimeoutTime" BU_SG_REL_ BCM1 SG_ 1122 PSD_Vorgaenger_Segment_ID 1500;
BA_REL_ "GenSigTimeoutTime" BU_SG_REL_ BCM1 SG_ 1122 PSD_Segmentlaenge 1500;
BA_REL_ "GenSigTimeoutTime" BU_SG_REL_ BCM1 SG_ 1122 PSD_Strassenkategorie 1500;
BA_REL_ "GenSigTimeoutTime" BU_SG_REL_ BCM1 SG_ 1122 PSD_Endkruemmung 1500;
BA_REL_ "GenSigTimeoutTime" BU_SG_REL_ BCM1 SG_ 1122 PSD_Endkruemmung_Vorz 1500;
BA_REL_ "GenSigTimeoutTime" BU_SG_REL_ BCM1 SG_ 1122 PSD_Idenditaets_ID 1500;
BA_REL_ "GenSigTimeoutTime" BU_SG_REL_ BCM1 SG_ 1122 PSD_ADAS_Qualitaet 1500;
BA_REL_ "GenSigTimeoutTime" BU_SG_REL_ BCM1 SG_ 1122 PSD_wahrscheinlichster_Pfad 1500;
BA_REL_ "GenSigTimeoutTime" BU_SG_REL_ BCM1 SG_ 1122 PSD_Geradester_Pfad 1500;
BA_REL_ "GenSigTimeoutTime" BU_SG_REL_ BCM1 SG_ 1122 PSD_Fahrspuren_Anzahl 1500;
BA_REL_ "GenSigTimeoutTime" BU_SG_REL_ BCM1 SG_ 1122 PSD_Bebauung 1500;
BA_REL_ "GenSigTimeoutTime" BU_SG_REL_ BCM1 SG_ 1122 PSD_Segment_Komplett 1500;
BA_REL_ "GenSigTimeoutTime" BU_SG_REL_ BCM1 SG_ 1122 PSD_Rampe 1500;
BA_REL_ "GenSigTimeoutTime" BU_SG_REL_ BCM1 SG_ 1122 PSD_Anfangskruemmung 1500;
BA_REL_ "GenSigTimeoutTime" BU_SG_REL_ BCM1 SG_ 1122 PSD_Anfangskruemmung_Vorz 1500;
BA_REL_ "GenSigTimeoutTime" BU_SG_REL_ BCM1 SG_ 1122 PSD_Abzweigerichtung 1500;
BA_REL_ "GenSigTimeoutTime" BU_SG_REL_ BCM1 SG_ 1122 PSD_Abzweigewinkel 1500;
BA_REL_ "GenSigTimeoutTime" BU_SG_REL_ BCM1 SG_ 1123 PSD_Pos_Segment_ID 1500;
BA_REL_ "GenSigTimeoutTime" BU_SG_REL_ BCM1 SG_ 1123 PSD_Pos_Segmentlaenge 1500;
BA_REL_ "GenSigTimeoutTime" BU_SG_REL_ BCM1 SG_ 1123 PSD_Pos_Inhibitzeit 1500;
BA_REL_ "GenSigTimeoutTime" BU_SG_REL_ BCM1 SG_ 1123 PSD_Pos_Standort_Eindeutig 1500;
BA_REL_ "GenSigTimeoutTime" BU_SG_REL_ BCM1 SG_ 1123 PSD_Pos_Fehler_Laengsrichtung 1500;
BA_REL_ "GenSigTimeoutTime" BU_SG_REL_ BCM1 SG_ 1123 PSD_Pos_Fahrspur 1500;
BA_REL_ "GenSigTimeoutTime" BU_SG_REL_ BCM1 SG_ 1123 PSD_Attribut_Segment_ID_05 1500;
BA_REL_ "GenSigTimeoutTime" BU_SG_REL_ BCM1 SG_ 1123 PSD_Attribut_1_ID 1500;
BA_REL_ "GenSigTimeoutTime" BU_SG_REL_ BCM1 SG_ 1123 PSD_Attribut_1_Wert 1500;
BA_REL_ "GenSigTimeoutTime" BU_SG_REL_ BCM1 SG_ 1123 PSD_Attribut_1_Offset 1500;
BA_REL_ "GenSigTimeoutTime" BU_SG_REL_ BCM1 SG_ 1123 PSD_Attribut_2_ID 1500;
BA_REL_ "GenSigTimeoutTime" BU_SG_REL_ BCM1 SG_ 1123 PSD_Attribut_2_Wert 1500;
BA_REL_ "GenSigTimeoutTime" BU_SG_REL_ BCM1 SG_ 1123 PSD_Attribut_2_Offset 1500;
BA_REL_ "GenSigTimeoutTime" BU_SG_REL_ BCM1 SG_ 1123 PSD_Attribute_Komplett_05 1500;
BA_REL_ "GenSigTimeoutTime" BU_SG_REL_ BCM1 SG_ 1124 PSD_06_Mux 1500;
BA_REL_ "GenSigTimeoutTime" BU_SG_REL_ BCM1 SG_ 1124 PSD_Sys_Segment_ID 1500;
BA_REL_ "GenSigTimeoutTime" BU_SG_REL_ BCM1 SG_ 1124 PSD_Attribut_Segment_ID 1500;
BA_REL_ "GenSigTimeoutTime" BU_SG_REL_ BCM1 SG_ 1124 PSD_Ges_Segment_ID 1500;
BA_REL_ "GenSigTimeoutTime" BU_SG_REL_ BCM1 SG_ 1124 PSD_Baum_Laenge_VZ 1500;
BA_REL_ "GenSigTimeoutTime" BU_SG_REL_ BCM1 SG_ 1124 PSD_Steigung_1_Segment_ID 1500;
BA_REL_ "GenSigTimeoutTime" BU_SG_REL_ BCM1 SG_ 1124 PSD_Baum_Laenge 1500;
BA_REL_ "GenSigTimeoutTime" BU_SG_REL_ BCM1 SG_ 1124 PSD_Sys_Laendercode 1500;
BA_REL_ "GenSigTimeoutTime" BU_SG_REL_ BCM1 SG_ 1124 PSD_Attribut_3_ID 1500;
BA_REL_ "GenSigTimeoutTime" BU_SG_REL_ BCM1 SG_ 1124 PSD_Ges_Offset 1500;
BA_REL_ "GenSigTimeoutTime" BU_SG_REL_ BCM1 SG_ 1124 PSD_Steigung_1_A_Steigung 1500;
BA_REL_ "GenSigTimeoutTime" BU_SG_REL_ BCM1 SG_ 1124 PSD_Attribut_3_Offset 1500;
BA_REL_ "GenSigTimeoutTime" BU_SG_REL_ BCM1 SG_ 1124 PSD_Ges_Geschwindigkeit 1500;
BA_REL_ "GenSigTimeoutTime" BU_SG_REL_ BCM1 SG_ 1124 PSD_Steigung_1_A_Vorz 1500;
BA_REL_ "GenSigTimeoutTime" BU_SG_REL_ BCM1 SG_ 1124 PSD_Sys_Geschwindigkeit_Einheit 1500;
BA_REL_ "GenSigTimeoutTime" BU_SG_REL_ BCM1 SG_ 1124 PSD_Steigung_1_A_Offset 1500;
BA_REL_ "GenSigTimeoutTime" BU_SG_REL_ BCM1 SG_ 1124 PSD_Sys_Verkehrsrichtung 1500;
BA_REL_ "GenSigTimeoutTime" BU_SG_REL_ BCM1 SG_ 1124 PSD_Sys_Geometrieguete 1500;
BA_REL_ "GenSigTimeoutTime" BU_SG_REL_ BCM1 SG_ 1124 PSD_Sys_Mapmatchingguete 1500;
BA_REL_ "GenSigTimeoutTime" BU_SG_REL_ BCM1 SG_ 1124 PSD_Attribut_3_Wert 1500;
BA_REL_ "GenSigTimeoutTime" BU_SG_REL_ BCM1 SG_ 1124 PSD_Ges_Typ 1500;
BA_REL_ "GenSigTimeoutTime" BU_SG_REL_ BCM1 SG_ 1124 PSD_Sys_Alter_Karte 1500;
BA_REL_ "GenSigTimeoutTime" BU_SG_REL_ BCM1 SG_ 1124 PSD_Ges_Spur_Geschw_Begrenzung 1500;
BA_REL_ "GenSigTimeoutTime" BU_SG_REL_ BCM1 SG_ 1124 PSD_Steigung_1_B_Steigung 1500;
BA_REL_ "GenSigTimeoutTime" BU_SG_REL_ BCM1 SG_ 1124 PSD_Attribut_4_ID 1500;
BA_REL_ "GenSigTimeoutTime" BU_SG_REL_ BCM1 SG_ 1124 PSD_Sys_Zielfuehrung 1500;
BA_REL_ "GenSigTimeoutTime" BU_SG_REL_ BCM1 SG_ 1124 PSD_Sys_US_State 1500;
BA_REL_ "GenSigTimeoutTime" BU_SG_REL_ BCM1 SG_ 1124 PSD_Ges_Geschwindigkeit_Gespann 1500;
BA_REL_ "GenSigTimeoutTime" BU_SG_REL_ BCM1 SG_ 1124 PSD_Baum_Breite_VZ 1500;
BA_REL_ "GenSigTimeoutTime" BU_SG_REL_ BCM1 SG_ 1124 PSD_Attribut_4_Wert 1500;
BA_REL_ "GenSigTimeoutTime" BU_SG_REL_ BCM1 SG_ 1124 PSD_Baum_Breite 1500;
BA_REL_ "GenSigTimeoutTime" BU_SG_REL_ BCM1 SG_ 1124 PSD_Ges_Geschwindigkeit_Witter 1500;
BA_REL_ "GenSigTimeoutTime" BU_SG_REL_ BCM1 SG_ 1124 PSD_Steigung_1_B_Vorz 1500;
BA_REL_ "GenSigTimeoutTime" BU_SG_REL_ BCM1 SG_ 1124 PSD_Steigung_1_B_Offset 1500;
BA_REL_ "GenSigTimeoutTime" BU_SG_REL_ BCM1 SG_ 1124 PSD_Sys_Quali_Geometrien 1500;
BA_REL_ "GenSigTimeoutTime" BU_SG_REL_ BCM1 SG_ 1124 PSD_Ges_Geschwindigkeit_Tag_Anf 1500;
BA_REL_ "GenSigTimeoutTime" BU_SG_REL_ BCM1 SG_ 1124 PSD_Attribut_4_Offset 1500;
BA_REL_ "GenSigTimeoutTime" BU_SG_REL_ BCM1 SG_ 1124 PSD_Sys_Quali_Ortsinfo 1500;
BA_REL_ "GenSigTimeoutTime" BU_SG_REL_ BCM1 SG_ 1124 PSD_Ges_Geschwindigkeit_Tag_Ende 1500;
BA_REL_ "GenSigTimeoutTime" BU_SG_REL_ BCM1 SG_ 1124 PSD_Sys_Quali_verfuegbar 1500;
BA_REL_ "GenSigTimeoutTime" BU_SG_REL_ BCM1 SG_ 1124 PSD_Sys_Zielfuehrung_geaendert 1500;
BA_REL_ "GenSigTimeoutTime" BU_SG_REL_ BCM1 SG_ 1124 PSD_Ges_Geschwindigkeit_Std_Anf 1500;
BA_REL_ "GenSigTimeoutTime" BU_SG_REL_ BCM1 SG_ 1124 PSD_Steigung_1_Attribute_kompl 1500;
BA_REL_ "GenSigTimeoutTime" BU_SG_REL_ BCM1 SG_ 1124 PSD_Sys_Geometrieguete_erweitert 1500;
BA_REL_ "GenSigTimeoutTime" BU_SG_REL_ BCM1 SG_ 1124 PSD_Steigung_2_Segment_ID 1500;
BA_REL_ "GenSigTimeoutTime" BU_SG_REL_ BCM1 SG_ 1124 PSD_Attribut_5_ID 1500;
BA_REL_ "GenSigTimeoutTime" BU_SG_REL_ BCM1 SG_ 1124 PSD_Ges_Geschwindigkeit_Std_Ende 1500;
BA_REL_ "GenSigTimeoutTime" BU_SG_REL_ BCM1 SG_ 1124 PSD_Attribut_5_Offset 1500;
BA_REL_ "GenSigTimeoutTime" BU_SG_REL_ BCM1 SG_ 1124 PSD_Steigung_2_Steigung 1500;
BA_REL_ "GenSigTimeoutTime" BU_SG_REL_ BCM1 SG_ 1124 PSD_Sys_Quali_sonstige_Attribute 1500;
BA_REL_ "GenSigTimeoutTime" BU_SG_REL_ BCM1 SG_ 1124 PSD_Ges_Ueberholverbot 1500;
BA_REL_ "GenSigTimeoutTime" BU_SG_REL_ BCM1 SG_ 1124 PSD_Sys_Quali_Steigungen 1500;
BA_REL_ "GenSigTimeoutTime" BU_SG_REL_ BCM1 SG_ 1124 PSD_Ges_Wechselverkehrszeichen 1500;
BA_REL_ "GenSigTimeoutTime" BU_SG_REL_ BCM1 SG_ 1124 PSD_Attribut_5_Wert 1500;
BA_REL_ "GenSigTimeoutTime" BU_SG_REL_ BCM1 SG_ 1124 PSD_Steigung_2_Vorz 1500;
BA_REL_ "GenSigTimeoutTime" BU_SG_REL_ BCM1 SG_ 1124 PSD_Sys_Quali_Strassenkennz 1500;
BA_REL_ "GenSigTimeoutTime" BU_SG_REL_ BCM1 SG_ 1124 PSD_Wechselverkehrszeichen_Typ 1500;
BA_REL_ "GenSigTimeoutTime" BU_SG_REL_ BCM1 SG_ 1124 PSD_Baum_Ausrichtung 1500;
BA_REL_ "GenSigTimeoutTime" BU_SG_REL_ BCM1 SG_ 1124 PSD_Steigung_2_Offset 1500;
BA_REL_ "GenSigTimeoutTime" BU_SG_REL_ BCM1 SG_ 1124 PSD_Ges_Gesetzlich_Kategorie 1500;
BA_REL_ "GenSigTimeoutTime" BU_SG_REL_ BCM1 SG_ 1124 PSD_Sys_Quali_Tempolimits 1500;
BA_REL_ "GenSigTimeoutTime" BU_SG_REL_ BCM1 SG_ 1124 PSD_Attribute_Komplett_06 1500;
BA_REL_ "GenSigTimeoutTime" BU_SG_REL_ BCM1 SG_ 1124 PSD_Ges_Gesetzlich_Zusatz 1500;
BA_REL_ "GenSigTimeoutTime" BU_SG_REL_ BCM1 SG_ 1124 PSD_Sys_Quali_Vorfahrtsregelung 1500;
BA_REL_ "GenSigTimeoutTime" BU_SG_REL_ BCM1 SG_ 1124 PSD_Ges_Verkehrszeichen_Quelle 1500;
BA_REL_ "GenSigTimeoutTime" BU_SG_REL_ BCM1 SG_ 1124 PSD_Steigung_2_Attribute_kompl 1500;
BA_REL_ "GenSigTimeoutTime" BU_SG_REL_ BCM1 SG_ 1124 PSD_Ges_Attribute_Komplett 1500;
BA_REL_ "GenSigTimeoutTime" BU_SG_REL_ BCM1 SG_ 1616 RA_Radio_on 5000;
BA_REL_ "GenSigTimeoutTime" BU_SG_REL_ BCM1 SG_ 1616 RA_Frequency 5000;
BA_REL_ "GenSigTimeoutTime" BU_SG_REL_ BCM1 SG_ 1616 RA_Frequency_unit 5000;
BA_REL_ "GenSigTimeoutTime" BU_SG_REL_ BCM1 SG_ 1616 RA_AM_Tuning 5000;
BA_REL_ "GenSigTimeoutTime" BU_SG_REL_ BCM1 SG_ 695 RCTA_Kritikalitaetslevel_rechts 500;
BA_REL_ "GenSigTimeoutTime" BU_SG_REL_ BCM1 SG_ 695 RCTA_Kritikalitaetslevel_links 500;
BA_REL_ "GenSigTimeoutTime" BU_SG_REL_ BCM1 SG_ 695 RCTA_Status 500;
BA_REL_ "GenSigTimeoutTime" BU_SG_REL_ BCM1 SG_ 695 RCTA_Warnton 500;
BA_REL_ "GenSigTimeoutTime" BU_SG_REL_ BCM1 SG_ 1711 RV_Reinigung_Anf 5000;
BA_REL_ "GenSigTimeoutTime" BU_SG_REL_ BCM1 SG_ 1711 ZFAS_Umfeldbeleuchtung_Anf 5000;
BA_REL_ "GenSigTimeoutTime" BU_SG_REL_ Gateway SG_ 1175 PH_StartStopp_Info 1000;
BA_REL_ "GenSigTimeoutTime" BU_SG_REL_ Klima_MSB SG_ 1635 BEM_02_Abschaltstufen 1000;
BA_REL_ "GenSigTimeoutTime" BU_SG_REL_ Klima_MSB SG_ 1635 BEM_STH_Zielzeit 1000;
BA_REL_ "GenSigTimeoutTime" BU_SG_REL_ Klima_MSB SG_ 1635 BEM_Red_Innengeblaese 1000;
BA_REL_ "GenSigTimeoutTime" BU_SG_REL_ Klima_MSB SG_ 1635 BEM_STH_Einschaltverbot 1000;
BA_REL_ "GenSigTimeoutTime" BU_SG_REL_ Klima_MSB SG_ 1635 BEM_HL_Regelung_Status 1000;
BA_REL_ "GenSigTimeoutTime" BU_SG_REL_ Klima_MSB SG_ 1635 BEM_UBDM 1000;
BA_REL_ "GenSigTimeoutTime" BU_SG_REL_ Klima_MSB SG_ 2527679508 NVEM_Energie_Klima_Vorgabe 1000;
BA_REL_ "GenSigTimeoutTime" BU_SG_REL_ Klima_MSB SG_ 2527679498 Perso_Kontonummer 5000;
BA_REL_ "GenSigTimeoutTime" BU_SG_REL_ Klima_MSB SG_ 2527679498 Perso_Steuerung 5000;
BA_REL_ "GenSigTimeoutTime" BU_SG_REL_ Klima_MSB SG_ 2527679498 Perso_Steuerungsparameter 5000;
BA_REL_ "GenSigTimeoutTime" BU_SG_REL_ Klima_MSB SG_ 2527679498 Perso_Status 5000;
BA_REL_ "GenSigTimeoutTime" BU_SG_REL_ Lift_VA SG_ 1635 BEM_HL_Regelung_Status 1000;
BA_REL_ "GenSigTimeoutTime" BU_SG_REL_ Lift_VA SG_ 913 OBD_Warm_Up_Cycle 800;
BA_REL_ "GenSigTimeoutTime" BU_SG_REL_ VAS_L SG_ 2527679498 Perso_Kontonummer 5000;
BA_REL_ "GenSigTimeoutTime" BU_SG_REL_ VAS_L SG_ 2527679498 Perso_Steuerung 5000;
BA_REL_ "GenSigTimeoutTime" BU_SG_REL_ VAS_L SG_ 2527679498 Perso_Steuerungsparameter 5000;
BA_REL_ "GenSigTimeoutTime" BU_SG_REL_ VAS_L SG_ 2527679498 Perso_Status 5000;
BA_REL_ "GenSigTimeoutTime" BU_SG_REL_ VAS_L SG_ 2527679498 Perso_Bedienstelle 5000;
BA_REL_ "GenSigTimeoutTime" BU_SG_REL_ VAS_L SG_ 2527679498 Perso_Freigabe_Verstellung 5000;
BA_REL_ "GenSigTimeoutTime" BU_SG_REL_ VAS_L SG_ 2527679498 Perso_Aktiv 5000;
BA_REL_ "GenSigTimeoutTime" BU_SG_REL_ VAS_L SG_ 1122 PSD_Segment_ID 1500;
BA_REL_ "GenSigTimeoutTime" BU_SG_REL_ VAS_L SG_ 1122 PSD_Vorgaenger_Segment_ID 1500;
BA_REL_ "GenSigTimeoutTime" BU_SG_REL_ VAS_L SG_ 1122 PSD_Segmentlaenge 1500;
BA_REL_ "GenSigTimeoutTime" BU_SG_REL_ VAS_L SG_ 1122 PSD_Strassenkategorie 1500;
BA_REL_ "GenSigTimeoutTime" BU_SG_REL_ VAS_L SG_ 1122 PSD_Endkruemmung 1500;
BA_REL_ "GenSigTimeoutTime" BU_SG_REL_ VAS_L SG_ 1122 PSD_Endkruemmung_Vorz 1500;
BA_REL_ "GenSigTimeoutTime" BU_SG_REL_ VAS_L SG_ 1122 PSD_Idenditaets_ID 1500;
BA_REL_ "GenSigTimeoutTime" BU_SG_REL_ VAS_L SG_ 1122 PSD_ADAS_Qualitaet 1500;
BA_REL_ "GenSigTimeoutTime" BU_SG_REL_ VAS_L SG_ 1122 PSD_wahrscheinlichster_Pfad 1500;
BA_REL_ "GenSigTimeoutTime" BU_SG_REL_ VAS_L SG_ 1122 PSD_Geradester_Pfad 1500;
BA_REL_ "GenSigTimeoutTime" BU_SG_REL_ VAS_L SG_ 1122 PSD_Fahrspuren_Anzahl 1500;
BA_REL_ "GenSigTimeoutTime" BU_SG_REL_ VAS_L SG_ 1122 PSD_Bebauung 1500;
BA_REL_ "GenSigTimeoutTime" BU_SG_REL_ VAS_L SG_ 1122 PSD_Segment_Komplett 1500;
BA_REL_ "GenSigTimeoutTime" BU_SG_REL_ VAS_L SG_ 1122 PSD_Rampe 1500;
BA_REL_ "GenSigTimeoutTime" BU_SG_REL_ VAS_L SG_ 1122 PSD_Anfangskruemmung 1500;
BA_REL_ "GenSigTimeoutTime" BU_SG_REL_ VAS_L SG_ 1122 PSD_Anfangskruemmung_Vorz 1500;
BA_REL_ "GenSigTimeoutTime" BU_SG_REL_ VAS_L SG_ 1122 PSD_Abzweigerichtung 1500;
BA_REL_ "GenSigTimeoutTime" BU_SG_REL_ VAS_L SG_ 1122 PSD_Abzweigewinkel 1500;
BA_REL_ "GenSigTimeoutTime" BU_SG_REL_ VAS_L SG_ 1123 PSD_Pos_Segment_ID 1500;
BA_REL_ "GenSigTimeoutTime" BU_SG_REL_ VAS_L SG_ 1123 PSD_Pos_Segmentlaenge 1500;
BA_REL_ "GenSigTimeoutTime" BU_SG_REL_ VAS_L SG_ 1123 PSD_Pos_Inhibitzeit 1500;
BA_REL_ "GenSigTimeoutTime" BU_SG_REL_ VAS_L SG_ 1123 PSD_Pos_Standort_Eindeutig 1500;
BA_REL_ "GenSigTimeoutTime" BU_SG_REL_ VAS_L SG_ 1123 PSD_Pos_Fehler_Laengsrichtung 1500;
BA_REL_ "GenSigTimeoutTime" BU_SG_REL_ VAS_L SG_ 1123 PSD_Pos_Fahrspur 1500;
BA_REL_ "GenSigTimeoutTime" BU_SG_REL_ VAS_L SG_ 1123 PSD_Attribut_Segment_ID_05 1500;
BA_REL_ "GenSigTimeoutTime" BU_SG_REL_ VAS_L SG_ 1123 PSD_Attribut_1_ID 1500;
BA_REL_ "GenSigTimeoutTime" BU_SG_REL_ VAS_L SG_ 1123 PSD_Attribut_1_Wert 1500;
BA_REL_ "GenSigTimeoutTime" BU_SG_REL_ VAS_L SG_ 1123 PSD_Attribut_1_Offset 1500;
BA_REL_ "GenSigTimeoutTime" BU_SG_REL_ VAS_L SG_ 1123 PSD_Attribut_2_ID 1500;
BA_REL_ "GenSigTimeoutTime" BU_SG_REL_ VAS_L SG_ 1123 PSD_Attribut_2_Wert 1500;
BA_REL_ "GenSigTimeoutTime" BU_SG_REL_ VAS_L SG_ 1123 PSD_Attribut_2_Offset 1500;
BA_REL_ "GenSigTimeoutTime" BU_SG_REL_ VAS_L SG_ 1123 PSD_Attribute_Komplett_05 1500;
BA_REL_ "GenSigTimeoutTime" BU_SG_REL_ VAS_L SG_ 1124 PSD_06_Mux 1500;
BA_REL_ "GenSigTimeoutTime" BU_SG_REL_ VAS_L SG_ 1124 PSD_Sys_Segment_ID 1500;
BA_REL_ "GenSigTimeoutTime" BU_SG_REL_ VAS_L SG_ 1124 PSD_Attribut_Segment_ID 1500;
BA_REL_ "GenSigTimeoutTime" BU_SG_REL_ VAS_L SG_ 1124 PSD_Baum_Laenge_VZ 1500;
BA_REL_ "GenSigTimeoutTime" BU_SG_REL_ VAS_L SG_ 1124 PSD_Steigung_1_Segment_ID 1500;
BA_REL_ "GenSigTimeoutTime" BU_SG_REL_ VAS_L SG_ 1124 PSD_Baum_Laenge 1500;
BA_REL_ "GenSigTimeoutTime" BU_SG_REL_ VAS_L SG_ 1124 PSD_Sys_Laendercode 1500;
BA_REL_ "GenSigTimeoutTime" BU_SG_REL_ VAS_L SG_ 1124 PSD_Attribut_3_ID 1500;
BA_REL_ "GenSigTimeoutTime" BU_SG_REL_ VAS_L SG_ 1124 PSD_Steigung_1_A_Steigung 1500;
BA_REL_ "GenSigTimeoutTime" BU_SG_REL_ VAS_L SG_ 1124 PSD_Attribut_3_Offset 1500;
BA_REL_ "GenSigTimeoutTime" BU_SG_REL_ VAS_L SG_ 1124 PSD_Steigung_1_A_Vorz 1500;
BA_REL_ "GenSigTimeoutTime" BU_SG_REL_ VAS_L SG_ 1124 PSD_Sys_Geschwindigkeit_Einheit 1500;
BA_REL_ "GenSigTimeoutTime" BU_SG_REL_ VAS_L SG_ 1124 PSD_Steigung_1_A_Offset 1500;
BA_REL_ "GenSigTimeoutTime" BU_SG_REL_ VAS_L SG_ 1124 PSD_Sys_Verkehrsrichtung 1500;
BA_REL_ "GenSigTimeoutTime" BU_SG_REL_ VAS_L SG_ 1124 PSD_Sys_Geometrieguete 1500;
BA_REL_ "GenSigTimeoutTime" BU_SG_REL_ VAS_L SG_ 1124 PSD_Sys_Mapmatchingguete 1500;
BA_REL_ "GenSigTimeoutTime" BU_SG_REL_ VAS_L SG_ 1124 PSD_Attribut_3_Wert 1500;
BA_REL_ "GenSigTimeoutTime" BU_SG_REL_ VAS_L SG_ 1124 PSD_Sys_Alter_Karte 1500;
BA_REL_ "GenSigTimeoutTime" BU_SG_REL_ VAS_L SG_ 1124 PSD_Steigung_1_B_Steigung 1500;
BA_REL_ "GenSigTimeoutTime" BU_SG_REL_ VAS_L SG_ 1124 PSD_Attribut_4_ID 1500;
BA_REL_ "GenSigTimeoutTime" BU_SG_REL_ VAS_L SG_ 1124 PSD_Sys_Zielfuehrung 1500;
BA_REL_ "GenSigTimeoutTime" BU_SG_REL_ VAS_L SG_ 1124 PSD_Sys_US_State 1500;
BA_REL_ "GenSigTimeoutTime" BU_SG_REL_ VAS_L SG_ 1124 PSD_Baum_Breite_VZ 1500;
BA_REL_ "GenSigTimeoutTime" BU_SG_REL_ VAS_L SG_ 1124 PSD_Attribut_4_Wert 1500;
BA_REL_ "GenSigTimeoutTime" BU_SG_REL_ VAS_L SG_ 1124 PSD_Baum_Breite 1500;
BA_REL_ "GenSigTimeoutTime" BU_SG_REL_ VAS_L SG_ 1124 PSD_Steigung_1_B_Vorz 1500;
BA_REL_ "GenSigTimeoutTime" BU_SG_REL_ VAS_L SG_ 1124 PSD_Steigung_1_B_Offset 1500;
BA_REL_ "GenSigTimeoutTime" BU_SG_REL_ VAS_L SG_ 1124 PSD_Sys_Quali_Geometrien 1500;
BA_REL_ "GenSigTimeoutTime" BU_SG_REL_ VAS_L SG_ 1124 PSD_Attribut_4_Offset 1500;
BA_REL_ "GenSigTimeoutTime" BU_SG_REL_ VAS_L SG_ 1124 PSD_Sys_Quali_Ortsinfo 1500;
BA_REL_ "GenSigTimeoutTime" BU_SG_REL_ VAS_L SG_ 1124 PSD_Sys_Quali_verfuegbar 1500;
BA_REL_ "GenSigTimeoutTime" BU_SG_REL_ VAS_L SG_ 1124 PSD_Sys_Zielfuehrung_geaendert 1500;
BA_REL_ "GenSigTimeoutTime" BU_SG_REL_ VAS_L SG_ 1124 PSD_Steigung_1_Attribute_kompl 1500;
BA_REL_ "GenSigTimeoutTime" BU_SG_REL_ VAS_L SG_ 1124 PSD_Sys_Geometrieguete_erweitert 1500;
BA_REL_ "GenSigTimeoutTime" BU_SG_REL_ VAS_L SG_ 1124 PSD_Steigung_2_Segment_ID 1500;
BA_REL_ "GenSigTimeoutTime" BU_SG_REL_ VAS_L SG_ 1124 PSD_Attribut_5_ID 1500;
BA_REL_ "GenSigTimeoutTime" BU_SG_REL_ VAS_L SG_ 1124 PSD_Attribut_5_Offset 1500;
BA_REL_ "GenSigTimeoutTime" BU_SG_REL_ VAS_L SG_ 1124 PSD_Steigung_2_Steigung 1500;
BA_REL_ "GenSigTimeoutTime" BU_SG_REL_ VAS_L SG_ 1124 PSD_Sys_Quali_sonstige_Attribute 1500;
BA_REL_ "GenSigTimeoutTime" BU_SG_REL_ VAS_L SG_ 1124 PSD_Sys_Quali_Steigungen 1500;
BA_REL_ "GenSigTimeoutTime" BU_SG_REL_ VAS_L SG_ 1124 PSD_Attribut_5_Wert 1500;
BA_REL_ "GenSigTimeoutTime" BU_SG_REL_ VAS_L SG_ 1124 PSD_Steigung_2_Vorz 1500;
BA_REL_ "GenSigTimeoutTime" BU_SG_REL_ VAS_L SG_ 1124 PSD_Sys_Quali_Strassenkennz 1500;
BA_REL_ "GenSigTimeoutTime" BU_SG_REL_ VAS_L SG_ 1124 PSD_Baum_Ausrichtung 1500;
BA_REL_ "GenSigTimeoutTime" BU_SG_REL_ VAS_L SG_ 1124 PSD_Steigung_2_Offset 1500;
BA_REL_ "GenSigTimeoutTime" BU_SG_REL_ VAS_L SG_ 1124 PSD_Attribute_Komplett_06 1500;
BA_REL_ "GenSigTimeoutTime" BU_SG_REL_ VAS_L SG_ 1124 PSD_Steigung_2_Attribute_kompl 1500;
BA_REL_ "GenSigTimeoutTime" BU_SG_REL_ VAS_L SG_ 2589283632 RDK_Reifengroesse 5000;
BA_REL_ "GenSigTimeoutTime" BU_SG_REL_ VAS_L SG_ 2589283632 RDK_SollDruck_VA 5000;
BA_REL_ "GenSigTimeoutTime" BU_SG_REL_ VAS_L SG_ 2589283632 RDK_SollDruck_HA 5000;
BA_REL_ "GenSigTimeoutTime" BU_SG_REL_ VAS_L SG_ 2589283632 RDK_Diff_Druck_HL 5000;
BA_REL_ "GenSigTimeoutTime" BU_SG_REL_ VAS_L SG_ 2589283632 RDK_Diff_Druck_HR 5000;
BA_REL_ "GenSigTimeoutTime" BU_SG_REL_ VAS_L SG_ 2589283632 RDK_Diff_Druck_VL 5000;
BA_REL_ "GenSigTimeoutTime" BU_SG_REL_ VAS_L SG_ 2589283632 RDK_Diff_Druck_VR 5000;
BA_REL_ "GenSigTimeoutTime" BU_SG_REL_ VAS_L SG_ 1711 ZFAS_Umfeldbeleuchtung_Anf 5000;
BA_REL_ "GenSigTimeoutTime" BU_SG_REL_ VAS_R SG_ 2527679498 Perso_Kontonummer 5000;
BA_REL_ "GenSigTimeoutTime" BU_SG_REL_ VAS_R SG_ 2527679498 Perso_Steuerung 5000;
BA_REL_ "GenSigTimeoutTime" BU_SG_REL_ VAS_R SG_ 2527679498 Perso_Steuerungsparameter 5000;
BA_REL_ "GenSigTimeoutTime" BU_SG_REL_ VAS_R SG_ 2527679498 Perso_Status 5000;
BA_REL_ "GenSigTimeoutTime" BU_SG_REL_ VAS_R SG_ 2527679498 Perso_Bedienstelle 5000;
BA_REL_ "GenSigTimeoutTime" BU_SG_REL_ VAS_R SG_ 2527679498 Perso_Freigabe_Verstellung 5000;
BA_REL_ "GenSigTimeoutTime" BU_SG_REL_ VAS_R SG_ 2527679498 Perso_Aktiv 5000;
BA_REL_ "GenSigTimeoutTime" BU_SG_REL_ VAS_R SG_ 1122 PSD_Segment_ID 1500;
BA_REL_ "GenSigTimeoutTime" BU_SG_REL_ VAS_R SG_ 1122 PSD_Vorgaenger_Segment_ID 1500;
BA_REL_ "GenSigTimeoutTime" BU_SG_REL_ VAS_R SG_ 1122 PSD_Segmentlaenge 1500;
BA_REL_ "GenSigTimeoutTime" BU_SG_REL_ VAS_R SG_ 1122 PSD_Strassenkategorie 1500;
BA_REL_ "GenSigTimeoutTime" BU_SG_REL_ VAS_R SG_ 1122 PSD_Endkruemmung 1500;
BA_REL_ "GenSigTimeoutTime" BU_SG_REL_ VAS_R SG_ 1122 PSD_Endkruemmung_Vorz 1500;
BA_REL_ "GenSigTimeoutTime" BU_SG_REL_ VAS_R SG_ 1122 PSD_Idenditaets_ID 1500;
BA_REL_ "GenSigTimeoutTime" BU_SG_REL_ VAS_R SG_ 1122 PSD_ADAS_Qualitaet 1500;
BA_REL_ "GenSigTimeoutTime" BU_SG_REL_ VAS_R SG_ 1122 PSD_wahrscheinlichster_Pfad 1500;
BA_REL_ "GenSigTimeoutTime" BU_SG_REL_ VAS_R SG_ 1122 PSD_Geradester_Pfad 1500;
BA_REL_ "GenSigTimeoutTime" BU_SG_REL_ VAS_R SG_ 1122 PSD_Fahrspuren_Anzahl 1500;
BA_REL_ "GenSigTimeoutTime" BU_SG_REL_ VAS_R SG_ 1122 PSD_Bebauung 1500;
BA_REL_ "GenSigTimeoutTime" BU_SG_REL_ VAS_R SG_ 1122 PSD_Segment_Komplett 1500;
BA_REL_ "GenSigTimeoutTime" BU_SG_REL_ VAS_R SG_ 1122 PSD_Rampe 1500;
BA_REL_ "GenSigTimeoutTime" BU_SG_REL_ VAS_R SG_ 1122 PSD_Anfangskruemmung 1500;
BA_REL_ "GenSigTimeoutTime" BU_SG_REL_ VAS_R SG_ 1122 PSD_Anfangskruemmung_Vorz 1500;
BA_REL_ "GenSigTimeoutTime" BU_SG_REL_ VAS_R SG_ 1122 PSD_Abzweigerichtung 1500;
BA_REL_ "GenSigTimeoutTime" BU_SG_REL_ VAS_R SG_ 1122 PSD_Abzweigewinkel 1500;
BA_REL_ "GenSigTimeoutTime" BU_SG_REL_ VAS_R SG_ 1123 PSD_Pos_Segment_ID 1500;
BA_REL_ "GenSigTimeoutTime" BU_SG_REL_ VAS_R SG_ 1123 PSD_Pos_Segmentlaenge 1500;
BA_REL_ "GenSigTimeoutTime" BU_SG_REL_ VAS_R SG_ 1123 PSD_Pos_Inhibitzeit 1500;
BA_REL_ "GenSigTimeoutTime" BU_SG_REL_ VAS_R SG_ 1123 PSD_Pos_Standort_Eindeutig 1500;
BA_REL_ "GenSigTimeoutTime" BU_SG_REL_ VAS_R SG_ 1123 PSD_Pos_Fehler_Laengsrichtung 1500;
BA_REL_ "GenSigTimeoutTime" BU_SG_REL_ VAS_R SG_ 1123 PSD_Pos_Fahrspur 1500;
BA_REL_ "GenSigTimeoutTime" BU_SG_REL_ VAS_R SG_ 1123 PSD_Attribut_Segment_ID_05 1500;
BA_REL_ "GenSigTimeoutTime" BU_SG_REL_ VAS_R SG_ 1123 PSD_Attribut_1_ID 1500;
BA_REL_ "GenSigTimeoutTime" BU_SG_REL_ VAS_R SG_ 1123 PSD_Attribut_1_Wert 1500;
BA_REL_ "GenSigTimeoutTime" BU_SG_REL_ VAS_R SG_ 1123 PSD_Attribut_1_Offset 1500;
BA_REL_ "GenSigTimeoutTime" BU_SG_REL_ VAS_R SG_ 1123 PSD_Attribut_2_ID 1500;
BA_REL_ "GenSigTimeoutTime" BU_SG_REL_ VAS_R SG_ 1123 PSD_Attribut_2_Wert 1500;
BA_REL_ "GenSigTimeoutTime" BU_SG_REL_ VAS_R SG_ 1123 PSD_Attribut_2_Offset 1500;
BA_REL_ "GenSigTimeoutTime" BU_SG_REL_ VAS_R SG_ 1123 PSD_Attribute_Komplett_05 1500;
BA_REL_ "GenSigTimeoutTime" BU_SG_REL_ VAS_R SG_ 1124 PSD_06_Mux 1500;
BA_REL_ "GenSigTimeoutTime" BU_SG_REL_ VAS_R SG_ 1124 PSD_Sys_Segment_ID 1500;
BA_REL_ "GenSigTimeoutTime" BU_SG_REL_ VAS_R SG_ 1124 PSD_Attribut_Segment_ID 1500;
BA_REL_ "GenSigTimeoutTime" BU_SG_REL_ VAS_R SG_ 1124 PSD_Baum_Laenge_VZ 1500;
BA_REL_ "GenSigTimeoutTime" BU_SG_REL_ VAS_R SG_ 1124 PSD_Steigung_1_Segment_ID 1500;
BA_REL_ "GenSigTimeoutTime" BU_SG_REL_ VAS_R SG_ 1124 PSD_Baum_Laenge 1500;
BA_REL_ "GenSigTimeoutTime" BU_SG_REL_ VAS_R SG_ 1124 PSD_Sys_Laendercode 1500;
BA_REL_ "GenSigTimeoutTime" BU_SG_REL_ VAS_R SG_ 1124 PSD_Attribut_3_ID 1500;
BA_REL_ "GenSigTimeoutTime" BU_SG_REL_ VAS_R SG_ 1124 PSD_Steigung_1_A_Steigung 1500;
BA_REL_ "GenSigTimeoutTime" BU_SG_REL_ VAS_R SG_ 1124 PSD_Attribut_3_Offset 1500;
BA_REL_ "GenSigTimeoutTime" BU_SG_REL_ VAS_R SG_ 1124 PSD_Steigung_1_A_Vorz 1500;
BA_REL_ "GenSigTimeoutTime" BU_SG_REL_ VAS_R SG_ 1124 PSD_Sys_Geschwindigkeit_Einheit 1500;
BA_REL_ "GenSigTimeoutTime" BU_SG_REL_ VAS_R SG_ 1124 PSD_Steigung_1_A_Offset 1500;
BA_REL_ "GenSigTimeoutTime" BU_SG_REL_ VAS_R SG_ 1124 PSD_Sys_Verkehrsrichtung 1500;
BA_REL_ "GenSigTimeoutTime" BU_SG_REL_ VAS_R SG_ 1124 PSD_Sys_Geometrieguete 1500;
BA_REL_ "GenSigTimeoutTime" BU_SG_REL_ VAS_R SG_ 1124 PSD_Sys_Mapmatchingguete 1500;
BA_REL_ "GenSigTimeoutTime" BU_SG_REL_ VAS_R SG_ 1124 PSD_Attribut_3_Wert 1500;
BA_REL_ "GenSigTimeoutTime" BU_SG_REL_ VAS_R SG_ 1124 PSD_Sys_Alter_Karte 1500;
BA_REL_ "GenSigTimeoutTime" BU_SG_REL_ VAS_R SG_ 1124 PSD_Steigung_1_B_Steigung 1500;
BA_REL_ "GenSigTimeoutTime" BU_SG_REL_ VAS_R SG_ 1124 PSD_Attribut_4_ID 1500;
BA_REL_ "GenSigTimeoutTime" BU_SG_REL_ VAS_R SG_ 1124 PSD_Sys_Zielfuehrung 1500;
BA_REL_ "GenSigTimeoutTime" BU_SG_REL_ VAS_R SG_ 1124 PSD_Sys_US_State 1500;
BA_REL_ "GenSigTimeoutTime" BU_SG_REL_ VAS_R SG_ 1124 PSD_Baum_Breite_VZ 1500;
BA_REL_ "GenSigTimeoutTime" BU_SG_REL_ VAS_R SG_ 1124 PSD_Attribut_4_Wert 1500;
BA_REL_ "GenSigTimeoutTime" BU_SG_REL_ VAS_R SG_ 1124 PSD_Baum_Breite 1500;
BA_REL_ "GenSigTimeoutTime" BU_SG_REL_ VAS_R SG_ 1124 PSD_Steigung_1_B_Vorz 1500;
BA_REL_ "GenSigTimeoutTime" BU_SG_REL_ VAS_R SG_ 1124 PSD_Steigung_1_B_Offset 1500;
BA_REL_ "GenSigTimeoutTime" BU_SG_REL_ VAS_R SG_ 1124 PSD_Sys_Quali_Geometrien 1500;
BA_REL_ "GenSigTimeoutTime" BU_SG_REL_ VAS_R SG_ 1124 PSD_Attribut_4_Offset 1500;
BA_REL_ "GenSigTimeoutTime" BU_SG_REL_ VAS_R SG_ 1124 PSD_Sys_Quali_Ortsinfo 1500;
BA_REL_ "GenSigTimeoutTime" BU_SG_REL_ VAS_R SG_ 1124 PSD_Sys_Quali_verfuegbar 1500;
BA_REL_ "GenSigTimeoutTime" BU_SG_REL_ VAS_R SG_ 1124 PSD_Sys_Zielfuehrung_geaendert 1500;
BA_REL_ "GenSigTimeoutTime" BU_SG_REL_ VAS_R SG_ 1124 PSD_Steigung_1_Attribute_kompl 1500;
BA_REL_ "GenSigTimeoutTime" BU_SG_REL_ VAS_R SG_ 1124 PSD_Sys_Geometrieguete_erweitert 1500;
BA_REL_ "GenSigTimeoutTime" BU_SG_REL_ VAS_R SG_ 1124 PSD_Steigung_2_Segment_ID 1500;
BA_REL_ "GenSigTimeoutTime" BU_SG_REL_ VAS_R SG_ 1124 PSD_Attribut_5_ID 1500;
BA_REL_ "GenSigTimeoutTime" BU_SG_REL_ VAS_R SG_ 1124 PSD_Attribut_5_Offset 1500;
BA_REL_ "GenSigTimeoutTime" BU_SG_REL_ VAS_R SG_ 1124 PSD_Steigung_2_Steigung 1500;
BA_REL_ "GenSigTimeoutTime" BU_SG_REL_ VAS_R SG_ 1124 PSD_Sys_Quali_sonstige_Attribute 1500;
BA_REL_ "GenSigTimeoutTime" BU_SG_REL_ VAS_R SG_ 1124 PSD_Sys_Quali_Steigungen 1500;
BA_REL_ "GenSigTimeoutTime" BU_SG_REL_ VAS_R SG_ 1124 PSD_Attribut_5_Wert 1500;
BA_REL_ "GenSigTimeoutTime" BU_SG_REL_ VAS_R SG_ 1124 PSD_Steigung_2_Vorz 1500;
BA_REL_ "GenSigTimeoutTime" BU_SG_REL_ VAS_R SG_ 1124 PSD_Sys_Quali_Strassenkennz 1500;
BA_REL_ "GenSigTimeoutTime" BU_SG_REL_ VAS_R SG_ 1124 PSD_Baum_Ausrichtung 1500;
BA_REL_ "GenSigTimeoutTime" BU_SG_REL_ VAS_R SG_ 1124 PSD_Steigung_2_Offset 1500;
BA_REL_ "GenSigTimeoutTime" BU_SG_REL_ VAS_R SG_ 1124 PSD_Attribute_Komplett_06 1500;
BA_REL_ "GenSigTimeoutTime" BU_SG_REL_ VAS_R SG_ 1124 PSD_Steigung_2_Attribute_kompl 1500;
BA_REL_ "GenSigTimeoutTime" BU_SG_REL_ VAS_R SG_ 2589283632 RDK_Reifengroesse 5000;
BA_REL_ "GenSigTimeoutTime" BU_SG_REL_ VAS_R SG_ 2589283632 RDK_SollDruck_VA 5000;
BA_REL_ "GenSigTimeoutTime" BU_SG_REL_ VAS_R SG_ 2589283632 RDK_SollDruck_HA 5000;
BA_REL_ "GenSigTimeoutTime" BU_SG_REL_ VAS_R SG_ 2589283632 RDK_Diff_Druck_HL 5000;
BA_REL_ "GenSigTimeoutTime" BU_SG_REL_ VAS_R SG_ 2589283632 RDK_Diff_Druck_HR 5000;
BA_REL_ "GenSigTimeoutTime" BU_SG_REL_ VAS_R SG_ 2589283632 RDK_Diff_Druck_VL 5000;
BA_REL_ "GenSigTimeoutTime" BU_SG_REL_ VAS_R SG_ 2589283632 RDK_Diff_Druck_VR 5000;
BA_REL_ "GenSigTimeoutTime" BU_SG_REL_ VAS_R SG_ 1711 ZFAS_Umfeldbeleuchtung_Anf 5000;
VAL_ 1377 NV_Obj_01_InvTTCBildebStdA 127 "Init" ;
VAL_ 1377 NV_Obj_Warnung_Fussgaenger 0 "inaktiv" 1 "aktiv" ;
VAL_ 1377 NV_Obj_Rechts 0 "nicht_erkannt" 1 "erkannt" ;
VAL_ 1377 NV_Obj_Links 0 "nicht_erkannt" 1 "erkannt" ;
VAL_ 1377 NV_Obj_01_Klasse 0 "unbekannt" 1 "ueberfahrbar" 2 "unterfahrbar" 3 "Fussgaenger" 4 "Fussgaengergruppe" 5 "Fahrrad" 6 "Motorrad" 7 "PKW" 8 "Van" 9 "LKW" 10 "Randbebauung" 11 "Tier" 12 "Retroreflektor" 15 "Init" ;
VAL_ 1377 NV_MessZeitpunkt 8191 "Init" ;
VAL_ 1377 NV_Sensor_PositionY 2047 "Init" ;
VAL_ 1377 NV_Sensor_PositionX 4095 "Init" ;
VAL_ 1377 NV_Sensor_PositionZ 2047 "Init" ;
VAL_ 1377 NV_NichtVerfuegbar 0 "NV_verfuegbar" 1 "NV_nicht_verfuegbar" ;
VAL_ 1635 BEM_02_Abschaltstufen 0 "Stufe 0 (keine Einschraenkungen)" 1 "Stufe 1" 2 "Stufe 2" 3 "Stufe 3" 4 "Transportmodus" 7 "Ruhestrommessmodus" ;
VAL_ 1635 BEM_STH_Zielzeit 14 "Init" 15 "Fehler" ;
VAL_ 1635 BEM_MMI_Vorwarnung 0 "keine Anzeige" 1 "Anzeige MMI-Vorwarnung" ;
VAL_ 1635 NVEM_Anf_SD_schalten 0 "Anf_SD_Nachlauf_nicht_aktiv" 1 "Anf_SD_Nachlauf_aktiv" ;
VAL_ 1635 BEM_Generatordiagnose 0 "keine Anzeige" 1 "Ladekontrollanzeige ein (Vorhalt)" 2 "rotes Batteriesymbol und Text (Generator defekt)" 3 "Hybrid_DCDC_Wandler_defekt" ;
VAL_ 1635 BEM_Red_Innengeblaese 0 "keine Reduzierung" 1 "Reduzierung Stufe 1" 2 "Reduzierung Stufe 2" 3 "Reduzierung Stufe 2 und Abschaltung Kompressor" ;
VAL_ 1635 BEM_STH_Einschaltverbot 0 "volle Verfuegbarkeit Standheizung/-lueftung" 1 "Standheizung/-lueftung nicht aktivierbar" ;
VAL_ 1635 BEM_HL_Regelung_Status 0 "HL_Regelung_inaktiv_(vor_und_waehrend_Motorstart)" 1 "HL_Regelung_Stufe_1" 2 "HL_Regelung_Stufe_2" 3 "HL_Regelung_Stufe_3" 4 "Verbrauchernotabschaltung_(VNA)" 5 "HL_Regelung_Stufe_5" 7 "Default" ;
VAL_ 1635 BEM_Ladezustand 14 "Init" 15 "Fehler" ;
VAL_ 1635 BEM_Batteriediagnose 0 "keine_Anzeige" 1 "nicht_belegt" 2 "Anzeige_aberkannte_Batterie" 3 "Anzeige_schwache_Batterie" 4 "Anzeige_Batterie_OK" 5 "Anzeige_Batterie_Laden" 6 "Anzeige_Batterie_Pruefen" 7 "Fehler" ;
VAL_ 1635 MIB_Stromsparmodus 0 "inaktiv" 1 "aktiv" ;
VAL_ 1635 BEM_REK_aktiv 0 "keine_Rekuperationsfreigabe" 1 "Rekuperationsfreigabe" ;
VAL_ 1635 NVEM_Last_Anf 0 "keine Anforderung" 1 "Verbraucher_Anforderung_Stufe_1" 2 "Verbraucher_Anforderung_Stufe_2" 3 "Verbraucher_Anforderung_Stufe_3" ;
VAL_ 1635 BEM_UBDM 0 "Init" 255 "Fehler" ;
VAL_ 1635 BEM_Anf_KL15_schalten 0 "Keine_Einschraenkung_Kl15" 1 "Empfehlung_auto_Abschaltung_Kl15" 2 "Veto_auto_Abschaltung_Kl15" 3 "Veto_auto_Abschaltung_Fahrtbetrieb" ;
VAL_ 1635 NVEM_Batterie_Service 0 "kein_Service" 1 "Service_Information1" 2 "Service_Information2" 3 "Service_Information3" ;
VAL_ 1635 NVEM_Freigabe_OnlineUpdate 0 "keine_Freigabe" 1 "Freigabe" ;
VAL_ 1635 NVEM_Freigabe_ORU4 0 "Init" 1 "keine_Freigabe" 2 "Freigabe_erteilt" 3 "Veto_Freigabe" ;
VAL_ 2527679508 NVEM_Max_Rampenzeit 0 "No_LRC" 1 "250ms" 2 "500ms" 3 "750ms" 4 "1s" 5 "2s" 6 "3s" 7 "4s" 8 "5s" 9 "6s" 10 "7s" 11 "8s" 12 "9s" 13 "10s" 14 "12s" 15 "15s" ;
VAL_ 2527679508 NVEM_Min_Spannung 126 "Init" 127 "Fehler" ;
VAL_ 2527679508 NVEM_Min_Spannung_Start 62 "Init" 63 "Fehler" ;
VAL_ 2527679508 NVEM_Max_Spannung 126 "Init" 127 "Fehler" ;
VAL_ 2527679508 NVEM_Energie_Klima_Vorgabe 254 "Init" 255 "Fehler" ;
VAL_ 2527679508 NVEM_MV_DC_uMinLV 126 "Init" 127 "Fehler" ;
VAL_ 2527679508 NVEM_MV_DC_uSollLV 126 "Init" 127 "Fehler" ;
VAL_ 2527679508 NVEM_Bordnetzdiagnose 0 "kein_Fehler" 1 "Warnung_1" 2 "Warnung_2" 3 "Warnung_3" ;
VAL_ 913 MO_Servicemodus 0 "nicht_aktiv" 1 "Service_Mode_1" 2 "Service_Mode_2" 3 "Service_Mode_3" 4 "Service_Mode_4" 5 "Service_Mode_5" 6 "Service_Mode_6" 7 "Service_Mode_7" 8 "Service_Mode_8" 9 "Service_Mode_9" 10 "Service_Mode_10" 11 "Service_Mode_11" 12 "Service_Mode_12" 13 "Service_Mode_13" 14 "Service_Mode_14" 15 "Service_Mode_15" ;
VAL_ 913 OBD_ClearMem_Inhibit 0 "FSP_Loeschen_zulaessig" 1 "FSP_Loeschen_nicht_zulaessig" ;
VAL_ 913 OBD_Sperrung_Kaltstart_Denom 0 "EVAP_Berechnung_freigegeben" 1 "EVAP_Berechnung_gesperrt" ;
VAL_ 913 MO_QBit_Aussen_Temp 0 "gueltiger_Wert" 1 "Ersatz_Init_oder_Fehlerwert" ;
VAL_ 913 OBD_Sperrung_IUMPR 0 "IUMPR_Berechnung_freigegeben" 1 "IUMPR_Berechnung_gesperrt" ;
VAL_ 913 OBD_Kaltstart_Denominator 0 "Denominator_nicht_hochzaehlen" 1 "Bedingungen_zum_Inkr_des_Kaltstart_Denom_erf" ;
VAL_ 913 OBD_Minimum_Trip 0 "kein_Min_Normed_Trip" 1 "Min_Normed_Trip" ;
VAL_ 913 OBD_Driving_Cycle 0 "kein Driving Cycle erkannt" 1 "DC erkannt" ;
VAL_ 913 OBD_Warm_Up_Cycle 0 "kein Warm Up Cycle erkannt" 1 "Warm Up Cycle erkannt" ;
VAL_ 913 OBD_Normed_Trip 0 "kein Normed Trip" 1 "Normed Trip erfüllt" ;
VAL_ 2589283656 ORU_Status 0 "IDLE" 1 "PENDING" 2 "PREPARATION" 3 "PREPARATION_HV" 4 "RUNNING" 5 "RUNNING_HV" 6 "PENDING_NOTREADY" ;
VAL_ 872 PH2_Visualisierung 0 "Aus" 1 "Angefragt" 2 "InAnzeige" 3 "Abgefordert" 6 "Init" 7 "Fehler" ;
VAL_ 872 PDC2_Tonausgabe_Front 0 "kein_Ton" 1 "Intervallton_1" 2 "Intervallton_2" 3 "Intervallton_3" 4 "Intervallton_4" 5 "Intervallton_5" 6 "Dauerton" 7 "Fehlerton" 8 "FCTAton" ;
VAL_ 872 PDC2_Tonausgabe_Heck 0 "kein_Ton" 1 "Intervallton_1" 2 "Intervallton_2" 3 "Intervallton_3" 4 "Intervallton_4" 5 "Intervallton_5" 6 "Dauerton" 7 "Fehlerton" 8 "Erstwarnton_hinten" 9 "RCTATon" ;
VAL_ 872 PH2_nachtr_Stopp_An 0 "nicht_angefordert" 1 "angefordert" ;
VAL_ 872 PH2_Abschaltursache 0 "keine, bzw. System aktiv" 1 "Abschaltung durch Herausnahme R-Gang" 2 "Abschaltung ueber Geschwindigkeit" 3 "Abschaltung ueber PDC-Taster" 4 "Abschaltung wegen PLA" 5 "Abschaltung durch KL 15 Bit = 0" 6 "tbd." 7 "Fehler-/gestört Zustand, System noch aktiv" ;
VAL_ 872 PH2_Opt_Anzeige_V_ein 0 "optische Anzeige vorne nicht aktiv" 1 "optische Anzeige vorne aktiviert" ;
VAL_ 872 PH2_Opt_Anzeige_H_ein 0 "Optische Anzeige aus" 1 "optische Anzeige hinten aktiviert" ;
VAL_ 872 PH2_Opt_Anz_V_Hindernis 0 "optische Anzeige vorne meldet kein Hindernis" 1 "optische Anzeige vorne meldet Hindernis im Warnbereich" ;
VAL_ 872 PH2_Opt_Anz_H_Hindernis 0 "optische Anzeige hinten meldet kein Hindernis" 1 "optische Anzeige hinten meldet Hindernis im Warnbereich" ;
VAL_ 872 PH2_Tongeber_V_aktiv 0 "Tongeber vorne nicht aktiv" 1 "Tongeber vorne  aktiv" ;
VAL_ 872 PH2_Tongeber_H_aktiv 0 "Tongeber hinten nicht aktiv" 1 "Tongeber hinten aktiv" ;
VAL_ 872 PH2_Tongeber_mute 0 "Tongeber nicht stummgeschaltet" 1 "Tongeber stummgeschaltet" ;
VAL_ 872 PH2_Anf_Audioabsenkung 0 "keine Absenkung der Lautstärke" 1 "Anforderung an das Audiosystem für Absenkung der Lautstärke" ;
VAL_ 872 PH2_Tongeber_H_verfuegbar 0 "nicht verfügbar" 1 "verfügbar" ;
VAL_ 872 PH2_Taster 0 "Taster_nicht_gedrueckt" 1 "Taster_gedrueckt" 2 "reserviert" 3 "Fehler" ;
VAL_ 872 PH2_Anf_Verdeck 0 "Verdeckbetrieb_freigegeben" 1 "Verdeckbetrieb_sperren" 2 "reserviert" 3 "reserviert" ;
VAL_ 872 PH2_StartStopp_Info 0 "Motorlauf_nicht_notwendig_(Stoppfreigabe)" 1 "Motoranlauf_nicht_zwingend_notwendig_(Stoppverbot,keine_Startanforderung)" 2 "Motoranlauf_zwingend_notwendig_(Startanforderung)" 3 "Systemfehler" ;
VAL_ 872 PH2_Stoermeldung 0 "keine_Anzeige_kein_Gong" 1 "Textmeldung_PDC_hinten_gestoert_mit_Gong" 2 "Textmeldung_PDC_hinten_gestoert_ohne_Gong" 3 "Textmeldung_PDC_vorn_gestoert_mit_Gong" 4 "Textmeldung_PDC_vorn_gestoert_ohne_Gong" 5 "Textmeldung_PDC_gestoert_mit_Gong" 6 "Textmeldung_PDC_gestoert_ohne_Gong" 7 "Textmeldung_PDC_seitlich_gestoert_mit_Gong" 8 "Textmeldung_PDC_seitlich_gestoert_ohne_Gong" ;
VAL_ 872 PH2_defekt 0 "PH aktiv" 1 "PH wurde aufgrund eines Defektes deaktiviert" ;
VAL_ 872 PH2_gestoert 0 "PH aktiv" 1 "PH wurde auf Grund einer Stoerung tempraer deaktiviert" ;
VAL_ 872 PH2_Systemzustand 0 "Anlage aus" 1 "Anlage durch einlegen R-Gang aktiviert" 2 "Anlage manuell durch Taster aktiviert" 3 "Anlage automatisch aktiviert" 4 "Anlage_durch_ARA_aktiviert" 6 "Init_Initialisierungsphase_nach_Kl15_ein_oder_Reset" 7 "Fehler-/gestört Zustand, System noch aktiv" ;
VAL_ 872 PH2_Display_Kundenwunsch 0 "Anzeige aus" 1 "Grafik" 2 "Rear View" 3 "automatisch" ;
VAL_ 1175 PH_Visualisierung 0 "Aus" 1 "Angefragt" 2 "InAnzeige" 3 "Abgefordert" 6 "Init" 7 "Fehler" ;
VAL_ 1175 PDC_Tonausgabe_Front 0 "kein_Ton" 1 "Intervallton_1" 2 "Intervallton_2" 3 "Intervallton_3" 4 "Intervallton_4" 5 "Intervallton_5" 6 "Dauerton" 7 "Fehlerton" 8 "RCTATon" ;
VAL_ 1175 PDC_Tonausgabe_Heck 0 "kein_Ton" 1 "Intervallton_1" 2 "Intervallton_2" 3 "Intervallton_3" 4 "Intervallton_4" 5 "Intervallton_5" 6 "Dauerton" 7 "Fehlerton" 8 "Erstwarnton_hinten" 9 "RCTATon" ;
VAL_ 1175 PH_nachtr_Stopp_Anf 0 "nicht_angefordert" 1 "angefordert" ;
VAL_ 1175 PH_Abschaltursache 0 "keine, bzw. System aktiv" 1 "Abschaltung durch Herausnahme R-Gang" 2 "Abschaltung ueber Geschwindigkeit" 3 "Abschaltung ueber PDC-Taster" 4 "Abschaltung wegen PLA" 5 "Abschaltung durch KL 15 Bit = 0" 6 "tbd." 7 "Fehler-/gestört Zustand, System noch aktiv" ;
VAL_ 1175 PH_Opt_Anzeige_V_ein 0 "optische Anzeige vorne nicht aktiv" 1 "optische Anzeige vorne aktiviert" ;
VAL_ 1175 PH_Opt_Anzeige_H_ein 0 "Optische Anzeige aus" 1 "optische Anzeige hinten aktiviert" ;
VAL_ 1175 PH_Opt_Anz_V_Hindernis 0 "optische Anzeige vorne meldet kein Hindernis" 1 "optische Anzeige vorne meldet Hindernis im Warnbereich" ;
VAL_ 1175 PH_Opt_Anz_H_Hindernis 0 "optische Anzeige hinten meldet kein Hindernis" 1 "optische Anzeige hinten meldet Hindernis im Warnbereich" ;
VAL_ 1175 PH_Tongeber_V_aktiv 0 "Tongeber vorne nicht aktiv" 1 "Tongeber vorne  aktiv" ;
VAL_ 1175 PH_Tongeber_H_aktiv 0 "Tongeber hinten nicht aktiv" 1 "Tongeber hinten aktiv" ;
VAL_ 1175 PH_Tongeber_mute 0 "Tongeber nicht stummgeschaltet" 1 "Tongeber stummgeschaltet" ;
VAL_ 1175 PH_Anf_Audioabsenkung 0 "keine Absenkung der Lautstärke" 1 "Anforderung an das Audiosystem für Absenkung der Lautstärke" ;
VAL_ 1175 PH_Tongeber_H_verfuegbar 0 "nicht verfügbar" 1 "verfügbar" ;
VAL_ 1175 PLA_Anf_Aufschaltung_RVC 0 "Keine_RVC_Aufschalteanf" 1 "RVC_Aufschalteanforderung" ;
VAL_ 1175 PH_Taster 0 "Taster_nicht_gedrueckt" 1 "Taster_gedrueckt" 2 "reserviert" 3 "Fehler" ;
VAL_ 1175 PH_Anf_Verdeck 0 "Verdeckbetrieb_freigegeben" 1 "Verdeckbetrieb_sperren" 2 "reserviert" 3 "reserviert" ;
VAL_ 1175 PH_StartStopp_Info 0 "Motorlauf_nicht_notwendig_(Stoppfreigabe)" 1 "Motoranlauf_nicht_zwingend_notwendig_(Stoppverbot,keine_Startanforderung)" 2 "Motoranlauf_zwingend_notwendig_(Startanforderung)" 3 "Systemfehler" ;
VAL_ 1175 PH_Stoermeldung 0 "keine_Anzeige_kein_Gong" 1 "Textmeldung_PDC_hinten_gestoert_mit_Gong" 2 "Textmeldung_PDC_hinten_gestoert_ohne_Gong" 3 "Textmeldung_PDC_vorn_gestoert_mit_Gong" 4 "Textmeldung_PDC_vorn_gestoert_ohne_Gong" 5 "Textmeldung_PDC_gestoert_mit_Gong" 6 "Textmeldung_PDC_gestoert_ohne_Gong" 7 "Textmeldung_PDC_seitlich_gestoert_mit_Gong" 8 "Textmeldung_PDC_seitlich_gestoert_ohne_Gong" ;
VAL_ 1175 PH_defekt 0 "PH aktiv" 1 "PH wurde aufgrund eines Defektes deaktiviert" ;
VAL_ 1175 PH_gestoert 0 "PH aktiv" 1 "PH wurde auf Grund einer Stoerung tempraer deaktiviert" ;
VAL_ 1175 PH_Systemzustand 0 "Anlage aus" 1 "Anlage durch einlegen R-Gang aktiviert" 2 "Anlage manuell durch Taster aktiviert" 3 "Anlage automatisch aktiviert" 4 "Anlage durch ARA aktiviert" 6 "Init - Initialisierungsphase nach Kl. 15 ein / Reset" 7 "Fehler-/gestört Zustand, System noch aktiv" ;
VAL_ 1175 PH_Display_Kundenwunsch 0 "Anzeige aus" 1 "Grafik" 2 "Rear View" 3 "automatisch" ;
VAL_ 1355 PH_Verschmutzungsmeldung 0 "keine_Anzeige_kein_Gong" 1 "Textmeldung_PDC_hinten_verschmutzt_mit_Gong" 2 "Textmeldung_PDC_hinten_verschmutzt_ohne_Gong" 3 "Textmeldung_PDC_vorn_verschmutzt_mit_Gong" 4 "Textmeldung_PDC_vorn_verschmutzt_ohne_Gong" 5 "Textmeldung_PDC_verschmutzt_mit_Gong" 6 "Textmeldung_PDC_verschmutzt_ohne_Gong" 7 "Textmeldung_PDC_seitlich_verschmutzt_mit_Gong" 8 "Textmeldung_PDC_seitlich_verschmutzt_ohne_Gong" ;
VAL_ 1355 PH_Aufschaltursache 0 "Anlage aus" 1 "Anlage durch einlegen R-Gang aktiviert" 2 "Anlage manuell durch Taster aktiviert" 3 "Anlage automatisch aktiviert" 4 "Anlage durch ARA aktiviert" 5 "Rueckwaertsrollen" 6 "Anlage_durch_PLA_aktiviert" 7 "Anlage_durch_IPA_aktiviert" 8 "Anlage_durch_FA_aktiviert" 9 "Anlage_durch_RBF_oder_MA_aktiviert" 10 "Anlage_durch_Smartphone_aktiviert" 11 "Anlage_durch_Jokertaste_aktiviert" 12 "Anlage_durch_Favoritentasten_aktiviert" 13 "Anlage_durch_SideViewTaster_aktiviert" 14 "Anlage_durch_RCTA_aktiviert" 15 "Anlage_durch_KAS_aktiviert" 16 "Anlage_durch_AWC_aktiviert" 30 "Init_Initialisierungsphase_nach_Kl_15_ein_oder_Reset" 31 "Fehler_gestoerter_Zustand_System_noch_aktiv" ;
VAL_ 1355 PH_Ton_Ausgabe 0 "Init" 1 "Intervallton_vorne" 2 "Intervallton_hinten" 3 "Dauerton_vorne" 4 "Dauerton_hinten" 5 "Quittierungston" 6 "Reserviert" 7 "Fehler" ;
VAL_ 1355 PH_Ton_Pausenlaenge 0 "Init" 1 "Pause_5ms" 2 "Pause_10ms" 3 "Pause_15ms" 100 "Pause_500ms" 101 "Reserviert" 126 "Reserviert" 127 "Fehler" ;
VAL_ 1355 PH_Ton_Richtung 0 "vorne" 1 "vorne_rechts" 2 "rechts" 3 "rechts_hinten" 4 "hinten" 5 "hinten_links" 6 "links" 7 "vorne_links" ;
VAL_ 1355 PH_Ton_Lautstaerke 0 "Minimallautstaerke" 1 "Lautstaerke_1" 2 "Lautstaerke_2" 3 "Lautstaerke_3" 4 "Lautstaerke_4" 5 "Lautstaerke_5" 6 "Lautstaerke_6" 7 "Maximallautstaerke" ;
VAL_ 1355 BCM_WAH_Meldung 0 "Init" 1 "Fehlermeldung_bei_Nichtverfuegbarkeit_mit_Gong" 2 "Fehlermeldung_bei_Nichtverfuegbarkeit_ohne_Gong" 3 "Anzeige_dass_Fahrzeug_erkannt_wurde_und_Funktion_aktiv_ist" 4 "Wiederanfahrhinweis_mit_Gong" 5 "Wiederanfahrhinweis_ohne_Gong" ;
VAL_ 1355 PDC_Charisma_Status 0 "Init" 1 "verfuegbar" 2 "nicht_verfuegbar" 3 "asynchron_durch_Fahrerwunsch" ;
VAL_ 1355 PDC_Charisma_FahrPr 0 "keine_Funktion" 1 "Programm_1" 2 "Programm_2" 3 "Programm_3" 4 "Programm_4" 5 "Programm_5" 6 "Programm_6" 7 "Programm_7" 8 "Programm_8" 9 "Programm_9" 10 "Programm_10" 11 "Programm_11" 12 "Programm_12" 13 "Programm_13" 14 "Programm_14" 15 "Programm_15" ;
VAL_ 803 SC_WarnBrems_Texte 0 "keine_Anzeige" 1 "Systemstoerung" 2 "keine_Sensorsicht" 3 "Demomodus" 4 "System_aus" 5 "Anhaengerbetrieb" 6 "ESC_aus" 7 "zurzeit_eingeschraenkt" 8 "zurzeit_eingeschraenkt_ESP_Aus" 9 "Initialisierung" ;
VAL_ 803 SC_AbstWarn_Texte 0 "keine_Anzeige" 1 "Systemstoerung" 2 "keine_Sensorsicht" 3 "Demomodus" 4 "System_aus" 5 "Anhaengerbetrieb" 6 "ESC_aus" 7 "zurzeit_eingeschraenkt" 8 "zurzeit_eingeschraenkt_ESP_Aus" 9 "Initialisierung" ;
VAL_ 803 PCF_Verz_Anf_ASIL 0 "Nicht_verfuegbar" 1 "Verz_Anf_ASIL_QM" 2 "Verz_Anf_ASIL_A" 3 "Verz_Anf_ASIL_B" 4 "Verz_Anf_ASIL_C" 5 "Verz_Anf_ASIL_D" 6 "reserved" 7 "reserved" ;
VAL_ 803 PCF_Verz_Auspraegung 0 "Standard" 1 "Erweitert" ;
VAL_ 803 PCF_Prefill_Anf 0 "Prefill_nicht_aktivieren" 1 "Prefill_aktivieren" ;
VAL_ 803 PCF_HBA_Param 0 "Defaultparametersatz" 1 "Param_leicht_erh_Empfindlichkeit" 2 "Param_erh_Empfindlichkeit" 3 "Param_hoechste_Empfindlichkeit" ;
VAL_ 803 PCF_Ruckprofil 0 "keine_Ruckanforderung" 1 "Profil_1" 2 "Profil_2" 3 "Profil_3" 4 "Profil_4" 5 "Profil_5" 6 "Profil_6" 7 "Profil_7" ;
VAL_ 803 PCF_Verz_Info 0 "keine_Anforderung" 1 "Teilbremsung_Stufe1" 2 "Teilbremsung_Stufe2" 3 "Zielbremsung_fahrergetriggert" 4 "Notbremsung_geregelt" 5 "Notbremsung_gesteuert" 6 "Abbiegebremsen_Angef" ;
VAL_ 803 PCF_Verz_Anf 834 "Init" ;
VAL_ 2527679498 Perso_Kontonummer 0 "kein_Benutzerkonto" 1 "Benutzerkonto_1" 2 "Benutzerkonto_2" 3 "Benutzerkonto_3" 4 "Benutzerkonto_4" 5 "Benutzerkonto_5" 6 "Benutzerkonto_6" 7 "Benutzerkonto_7" ;
VAL_ 2527679498 Perso_Steuerung 0 "keine_Steuerung" 1 "Reset_alle_Konten" 2 "Reset_aktives_Konto" 3 "Kopiere_aktives_Konto_nach" 4 "Wiederherstellen_aktives_Konto" 5 "Aktivieren_aktives_Konto" 6 "Reset_Konto" 7 "Reset_alle_Fahrer" 8 "Reset_aktiver_Fahrer" 9 "Reset_Fahrer" ;
VAL_ 2527679498 Perso_Steuerungsparameter 0 "kein_Parameter" 1 "Benutzerkonto_1" 2 "Benutzerkonto_2" 3 "Benutzerkonto_3" 4 "Benutzerkonto_4" 5 "Benutzerkonto_5" 6 "Benutzerkonto_6" 7 "Benutzerkonto_7" ;
VAL_ 2527679498 Perso_Status 0 "deaktiviert" 1 "PSO_1x_aktiviert" 2 "PSO_2x_aktiviert" ;
VAL_ 2527679498 Perso_Bedienstelle 0 "Init" 1 "Kombiinstrument" 2 "ABT" ;
VAL_ 2527679498 Perso_Freigabe_Verstellung 0 "Init" 1 "freigegeben" ;
VAL_ 2527679498 Perso_Aktiv 0 "deaktiviert" 1 "aktiviert" ;
VAL_ 2527679498 IAA_PSO_wake_up 0 "wake_up_inactive" 1 "wake_up_active" ;
VAL_ 2527679498 Perso_Fahrernummer 0 "kein_Fahrer" 1 "Fahrer_1" 2 "Fahrer_2" 3 "Fahrer_3" 4 "Fahrer_4" 5 "Fahrer_5" 6 "Fahrer_6" 7 "Fahrer_7" ;
VAL_ 2527679498 Perso_Schreibschutz 0 "Schreibschutz_deaktiviert" 1 "Schreibschutz_aktiviert" ;
VAL_ 304 PLA_Status_PLA_ESP 0 "PLA_ESP_Deaktiv" 1 "PLA_ESP_Init" 2 "PLA_ESP_Fehler" 3 "reserviert" 4 "PLA_ESP_aktivierbar" 5 "reserviert" 6 "PLA_ESP_Bremse_aktiv" 7 "reserviert" 8 "PLA_ESP_funktionsbereit" 9 "PLA_ESP_Neustart" 10 "PLA_ESP_Abbruch" 11 "reserviert" 12 "reserviert" 13 "reserviert" 14 "reserviert" 15 "reserviert" ;
VAL_ 304 PLA_Zahnstangen_Pos_Soll 4094 "Init" ;
VAL_ 304 PLA_VZ_Zahnstangen_Pos_Soll 0 "positiv" 1 "negativ" ;
VAL_ 304 PLA_Status_PLA_EPS 0 "reserviert" 1 "reserviert" 2 "reserviert" 3 "reserviert" 4 "PLA_EPS_aktivierbar" 5 "reserviert" 6 "PLA_EPS_Lenkwinkel_aktiv" 7 "reserviert" 8 "PLA_EPS_funktionsbereit" 9 "PLA_EPS_Neustart" 10 "PLA_EPS_Abbruch" 11 "reserviert" 12 "reserviert" 13 "reserviert" 14 "reserviert" 15 "reserviert" ;
VAL_ 304 PLA_Bremsverzoegerung 126 "Init" 127 "Fehler" ;
VAL_ 304 PLA_Anf_Bremsverzoegerung 0 "keine_Bremsverzoegerung" 1 "Bremsverzoegerung" ;
VAL_ 304 PLA_BremsMom_Verzoeg 0 "Bremsmoment" 1 "Bremsverzoegerung" ;
VAL_ 304 PLA_01_Signal_red_cyclic 0 "Langsame_Zykluszeit_aktiv" 1 "Schnelle_Zykluszeit_aktiv" ;
VAL_ 342 PLA_Status_PLA_HAL 4 "PLA_HAL_aktivierbar" 6 "PLA_HAL_Lenkwinkel_aktiv" 8 "PLA_HAL_funktionsbereit" 9 "PLA_HAL_Neustart" 10 "PLA_HAL_Abbruch" ;
VAL_ 342 PLA_HAL_VZ_Radwinkel_Soll 0 "positiv" 1 "negativ" ;
VAL_ 342 PLA_Status_PLA_TSK 1 "PLA_TSK_Init" 2 "PLA_TSK_Fehler" 4 "PLA_TSK_aktivierbar" 6 "PLA_TSK_aktiv" 8 "PLA_TSK_funktionsbereit" 10 "PLA_TSK_Abbruch" ;
VAL_ 342 PLA_maximale_Geschwindigkeit 0 "Inaktiv" 251 "Init" 255 "Fehler" ;
VAL_ 342 PLA_02_Signal_red_cyclic 0 "Langsame_Zykluszeit_aktiv" 1 "Schnelle_Zykluszeit_aktiv" ;
VAL_ 1166 PLA_Anforderung_HMS 0 "keine_Anforderung_Init" 1 "Halten" 2 "Parken" 3 "Halten_standby" 4 "Anfahren" 5 "Loesen_ueber_Rampe" 6 "Parken_mit_P" 7 "reserviert" ;
VAL_ 1166 PLA_Status_Aktive_Seite 0 "Rechts" 1 "Links" ;
VAL_ 1166 PLA_Anf_Anzeige_Mini 0 "keine_Anzeige" 1 "Miniaturanzeige" ;
VAL_ 1166 PLA_Mini_Modus 0 "kein_Mini_angezeigt" 1 "Mini_Laengsparken" 2 "Mini_Rueckwaerts_Querparken_mit_Vorbeifahrt" 3 "Mini_Vorwaerts_Querparken_ohne_VB" 4 "Mini_Vorwaerts_Querparken_mit_VB" 5 "weitere_Parkmoeglichkeit_vorhanden" 6 "Garagenparken" 7 "Mini_Rueckwaerts_Querparken_ohne_Vorbeifahrt" ;
VAL_ 1166 PLA_Anf_Akustik 0 "keine_Akustik" 1 "Akustik__Gong_1000" ;
VAL_ 1166 PLA_Anf_Anzeige_Schwellpfeil 0 "Keine_Schwellpfeilanzeige" 1 "Anzeige_Schwellpfeil" ;
VAL_ 1166 PLA_Anf_Anzeige_Bremsfuss 0 "Keine_Anzeige_Bremsfuss" 1 "Anzeige_Bremsfuss" ;
VAL_ 1166 PLA_Anf_Funktionsdisclaimer 0 "Laengsparken" 1 "Rueckwaerts_Querparken" 2 "Vorwaerts_Querparken" 3 "Ausparken_Laengsparken" ;
VAL_ 1166 PLA_Anf_Anzeigemodus 0 "Keine_Anzeige" 1 "Anzeige_AP_verfuegbar" 2 "Laengsparken_Singlescreen" 3 "Reserved" 4 "Rueckwaerts_Querparken_mit_VB" 5 "Rueckwaerts_Querparken_ohne_VB" 6 "Vorwaerts_Querparken_ohne_VB" 7 "Vorwaerts_Querparken_mit_VB" 8 "Ausparken_Laengsparken_Single" 9 "Garagenparken_vorwaerts" 10 "Garagenparken_rueckwaerts" 11 "Textmeldung_hochprior" 12 "Textmeldungen_niederprior" 13 "Anzeige_beidseitig" 14 "Anzeige_einseitig" 15 "Anzeige_PL_verfuegbar" ;
VAL_ 1166 PLA_Anf_Meldungen 0 "keine_Meldung" 1 "PLA_beendet" 2 "RBF_deaktiviert" 3 "Autosuche_ESC_ASR_Eingriff" 4 "PLA_temp_n_a_ESC_ASR_Fehler" 5 "PLA_temp_n_a_Anhaenger_gesteckt" 6 "Suche_Zeitlimit_ueberschritten" 7 "PLA_zurzeit_n_verfuegbar" 8 "PLA_defekt_Werkstatt" 9 "Stillstandzeit_n_ausreichend" 11 "AP_Blinker_setzen_u_RWG_einlegen" 12 "AP_n_moeglich_PL_zu_klein" 13 "RBF_aktiv" 14 "PLA_beendet_v_zu_hoch" 15 "PLA_beendet_Schiebetuer_offen" 16 "Gegenseite_versperrt" 17 "Parken_n_a_Luecke_zu_klein" 18 "PLA_im_Offroad_Modus_n_a" 21 "AP_Blinker_setzen_u_Softkey_MIB" 22 "Start_Softkey_am_MIB_betaetigen" 23 "RBF_Hindernis_erkannt" 24 "RBF_temp_beendet" 25 "RBF_Gaspedal_loesen" 26 "RBF_Bremse_betaetigen" 27 "RBF_n_a_temp" 28 "RBF_n_a_temp_Anhaenger" 29 "RBF_n_a_temp_Sensorsicht" 30 "RBF_n_a_temp_ESC" 31 "RBF_n_a_temp_Drive_Select" 32 "Einparken_am_MIB_bestaetigen" 40 "info_v_reduzieren" 41 "info_v_begrenzt" 42 "info_Wiederaufnahme" 43 "info_Richtungsw_rueckw" 44 "info_Richtungsw_vorw" 128 "Disclaimer_LP_rechts" 129 "Disclaimer_LP_links" 130 "Disclaimer_RQ_rechts" 131 "Disclaimer_RQ_links" 136 "Disclaimer_VQ_rechts" 137 "Disclaimer_VQ_links" 138 "Disclaimer_AP_rechts" 139 "Disclaimer_AP_links" 144 "Abbruch_Lenkeingriff_Fahrer" 145 "Abbruch_Anhaenger_erkannt" 146 "Abbruch_ESC_deaktiv" 147 "Abbruch_Zeitlimit_ueberschritten" 148 "Lenkeingriff_beendet_uebernehmen" 149 "Abbruch_manuell_parken" 150 "Abbruch_v_zu_hoch" 151 "Abbruch_ESC_ASR_Eingriff" 152 "PLA_beendet_temp_n_a" 153 "PLA_defekt_Werkstatt" 154 "Lenkung_uebernehmen_Fahrt_forts" 155 "Abbr_AP_Luecke_zu_klein" 156 "Bremseingriff_v_zu_hoch" 157 "Abbruch_Hindernis_erkannt" 158 "PLA_Notbremsung_Bremse_betaetige" 159 "PLA_Notbr_Abbruch_Bremse_betaet" 160 "Abbr_Einp_Hindernis_erkannt" 161 "PLA_beendet_Lenkung_uebernehmen" 162 "Abbruch_Offroad_Modus_PLA_n_a" 163 "PLA_Abbruch_Schiebetuer_offen" 164 "Abbr_Luecke_zu_klein" 165 "RBF_temp_n_a" 166 "RBF_Bremse_betaetigen" 167 "Disclaimer_vorwaerts" 168 "RBF_Bitte_uebernehmen" 169 "RBF_Stoerung_Service" 170 "Disclaimer_rueckwaerts" 171 "Abbruch_Fluegeltuer_offen" ;
VAL_ 1166 PLA_Status_Funktion 0 "PL_Suche" 1 "PL_Suche_Standby" 2 "PL_gefunden" 3 "POS_OK" 4 "Rangieren_vorwaerts" 5 "Rangieren_rueckwaerts" 6 "Disclaimer_in_Anzeige" 7 "Automodus_Wand" 8 "PP_Pos_OK" 11 "GP_Pos_OK" 14 "DP_Pos_OK" ;
VAL_ 1166 PLA_Status_beenden_Mini 0 "Funktion_vorhanden" 1 "Funktion_ausgewaehlt" 2 "Funktion_einparken_moeglich" 3 "Funktion_nicht_vorhanden" ;
VAL_ 1166 PLA_Status_Laengsparken_Mini 0 "Funktion_vorhanden" 1 "Funktion_ausgewaehlt" 2 "Funktion_einparken_moeglich" 3 "Funktion_nicht_vorhanden" ;
VAL_ 1166 PLA_Status_QP_Rueckw_Mini 0 "Funktion_vorhanden" 1 "Funktion_ausgewaehlt" 2 "Funktion_einparken_moeglich" 3 "Funktion_nicht_vorhanden" ;
VAL_ 1166 PLA_Status_QP_Vorw_Mini 0 "Funktion_vorhanden" 1 "Funktion_ausgewaehlt" 2 "Funktion_einparken_moeglich" 3 "Funktion_nicht_vorhanden" ;
VAL_ 319 PreCrash_Charisma_FahrPr 0 "keine_Funktion" 1 "Programm_1" 2 "Programm_2" 3 "Programm_3" 4 "Programm_4" 5 "Programm_5" 6 "Programm_6" 7 "Programm_7" 8 "Programm_8" 9 "Programm_9" 10 "Programm_10" 11 "Programm_11" 12 "Programm_12" 13 "Programm_13" 14 "Programm_14" 15 "Programm_15" ;
VAL_ 319 PreCrash_Charisma_Status 0 "Init" 1 "verfuegbar" 2 "nicht_verfuegbar" 3 "asynchron_durch_Fahrerwunsch" ;
VAL_ 319 PreCrash_Schiebedach_schliessen 0 "keine_Schliessung" 1 "Schliessung_angefordert" ;
VAL_ 319 PreCrash_Fenster_schliessen 0 "keine_Schliessung" 1 "Schliessung_angefordert" ;
VAL_ 319 PreCrash_Blinken 0 "keine_Blinkanforderung" 1 "Warnblinken" 2 "RECAS_Blinken" 3 "Notbremsblinken" ;
VAL_ 319 SC_PreSense_FCWP 0 "Warnung_gilt_fuer_Objekte" 1 "Warnung_gitl_fuer_Fussgaenger" ;
VAL_ 319 PreCrash_Tueren_Verriegeln 0 "keine_Anforderung" 1 "Tueren_Verriegeln" ;
VAL_ 319 PreCrash_Anforderung_AFR 0 "keine_Anforderung" 1 "linke_Seite" 2 "rechte_Seite" 3 "Vorderachse" 4 "Hinterachse" 5 "Vorwarnung" 7 "Init" ;
VAL_ 319 SC_PreCrash_LED 0 "keine_Anzeige" 1 "Stufe_1_glimmen" 2 "Stufe_2_leuchten" 3 "Stufe_3_blinken" ;
VAL_ 319 PreCrash_FS_Pneumatik_ansteuern 0 "keine_Anforderung" 1 "Pneumatik_ansteuern" ;
VAL_ 319 PreCrash_BFS_Pneumatik_ansteuern 0 "keine_Anforderung" 1 "Pneumatik_ansteuern" ;
VAL_ 319 PreCrash_Fo_Pneumatik_ansteuern 0 "keine_Anforderung" 1 "Pneumatik_ansteuern" ;
VAL_ 319 PreCrash_FS_Sitzlehne_verfahren 0 "keine_Anforderung" 1 "Sitzlehne_in_pos_x-Richtung_verfahren(vor)" 2 "Sitzlehne_in_neg_x-Richtung_verfahren(zurueck)" 3 "Sitzlehnenkopf_in_pos_x-Richtung_verfahren(vor)" 4 "Sitzlehnenkopf_in_neg_x-Richtung_verfahren(zurueck)" ;
VAL_ 319 PreCrash_BFS_Sitzlehne_verfahren 0 "keine_Anforderung" 1 "Sitzlehne_in_pos_x-Richtung_verfahren(vor)" 2 "Sitzlehne_in_neg_x-Richtung_verfahren(zurueck)" 3 "Sitzlehnenkopf_in_pos_x-Richtung_verfahren(vor)" 4 "Sitzlehnenkopf_in_neg_x-Richtung_verfahren(zurueck)" ;
VAL_ 319 PreCrash_Fo_Sitzlehne_verfahren 0 "keine_Anforderung" 1 "Sitzlehne_in_pos_x-Richtung_verfahren(vor)" 2 "Sitzlehne_in_neg_x-Richtung_verfahren(zurueck)" 3 "Sitzlehnenkopf_in_pos_x-Richtung_verfahren(vor)" 4 "Sitzlehnenkopf_in_neg_x-Richtung_verfahren(zurueck)" ;
VAL_ 319 PreCrash_FS_KSV_verfahren 0 "keine_Anforderung" 1 "in_pos_x-Richtung_verfahren" 2 "in_neg_x-Richung_verfahren" 3 "in_pos_z-Richtung_verfahren" 4 "in_neg_z-Richtung_verfahren" 5 "in_pos_x-Richtung_und_neg_z-Richtung_verfahren" 6 "in_pos_x_Richtung_und_pos_z-Richtung_verfahren" 7 "in_neg_x-Richtung_und_neg_z-Richtung_verfahren" 8 "in_neg_x-Richtung_und_pos_z-Richtung_verfahren" ;
VAL_ 319 PreCrash_BFS_KSV_verfahren 0 "keine_Anforderung" 1 "in_pos_x-Richtung_verfahren" 2 "in_neg_x-Richung_verfahren" 3 "in_pos_z-Richtung_verfahren" 4 "in_neg_z-Richtung_verfahren" 5 "in_pos_x-Richtung_und_neg_z-Richtung_verfahren" 6 "in_pos_x_Richtung_und_pos_z-Richtung_verfahren" 7 "in_neg_x-Richtung_und_neg_z-Richtung_verfahren" 8 "in_neg_x-Richtung_und_pos_z-Richtung_verfahren" ;
VAL_ 319 PreCrash_Fo_KSV_verfahren 0 "keine_Anforderung" 1 "in_pos_x-Richtung_verfahren" 2 "in_neg_x-Richung_verfahren" 3 "in_pos_z-Richtung_verfahren" 4 "in_neg_z-Richtung_verfahren" 5 "in_pos_x-Richtung_und_neg_z-Richtung_verfahren" 6 "in_pos_x_Richtung_und_pos_z-Richtung_verfahren" 7 "in_neg_x-Richtung_und_neg_z-Richtung_verfahren" 8 "in_neg_x-Richtung_und_pos_z-Richtung_verfahren" ;
VAL_ 319 SC_PreCrash_Warnung 0 "keine_Anzeige" 1 "latente_Vorwarnung" 2 "Vorwarnung" 3 "Akutwarnung" 4 "Eingriff" 5 "Fahreruebernahmeaufforderung" 6 "Abbiegewarnung" 7 "Basiseingriff" 8 "Heckeingriff" ;
VAL_ 319 SC_PreCrash_Texte 0 "keine_Anzeige" 1 "Systemstoerung" 2 "keine_Sensorsicht" 3 "Demomodus" 4 "System_aus" 5 "Anhaengerbetrieb" 6 "ESC_aus" 7 "zurzeit_eingeschraenkt" 8 "zurzeit_eingeschraenkt_ESP_Aus" 9 "Initialisierung" ;
VAL_ 1122 PSD_Segment_ID 0 "keine Segmentinformationen vorhanden" 1 "Fehlerwert" ;
VAL_ 1122 PSD_Vorgaenger_Segment_ID 0 "keine Segmentinformation vorhanden" 1 "Fehlerwert" ;
VAL_ 1122 PSD_Strassenkategorie 0 "Rest_Feldweg_Schotterweg_Privatweg" 1 "Ortsstraße" 2 "Kreisstraße" 3 "Landstraße" 4 "Bundesstraße" 5 "Autobahn" 7 "Init" ;
VAL_ 1122 PSD_Endkruemmung 255 "Gerade" ;
VAL_ 1122 PSD_Endkruemmung_Vorz 0 "Kruemmung_positiv" 1 "Kruemmung_negativ" ;
VAL_ 1122 PSD_Idenditaets_ID 0 "keine_Segment_Informationen_vorhanden" 1 "Fehler" ;
VAL_ 1122 PSD_ADAS_Qualitaet 0 "keine_ADAS_Qualitaet" 1 "ADAS_Qualitaet" ;
VAL_ 1122 PSD_wahrscheinlichster_Pfad 0 "Pfad_mit_geringer_Wahrscheinlichkeit" 1 "wahrscheinlichster_Pfad" ;
VAL_ 1122 PSD_Geradester_Pfad 0 "nicht_geradester_PFad" 1 "geradester_Pfad" ;
VAL_ 1122 PSD_Fahrspuren_Anzahl 0 "Einbahnstrasse_in_falsche_Richtung" 1 "eine_Fahrspur" 2 "zwei_Fahrspuren" 3 "drei_Fahrspuren" 4 "vier_Fahrspuren" 5 "fuenf_Fahrspuren" 6 "sechs_Fahrspuren" 7 "mehr_als_sechs_Fahrspuren" ;
VAL_ 1122 PSD_Bebauung 0 "ausserhalb_bebauten_Gebietes" 1 "innerhalb_bebauten_Gebietes" ;
VAL_ 1122 PSD_Segment_Komplett 0 "Segment_Attribute_nicht_komplett" 1 "Segment_Attribute_komplett" ;
VAL_ 1122 PSD_Rampe 0 "Strasse_mit_Gegenverkehr" 1 "Auffahrt_Einbahnstr" 2 "Abfahrt_Einbahnstr" 3 "Einbahnstrasse" ;
VAL_ 1122 PSD_Anfangskruemmung 255 "Gerade" ;
VAL_ 1122 PSD_Anfangskruemmung_Vorz 0 "positiv" 1 "negativ" ;
VAL_ 1122 PSD_Abzweigerichtung 0 "rects_abzweigende_Strasse" 1 "links_abzweigende_Strasse" ;
VAL_ 1123 PSD_Pos_Segment_ID 0 "keine Position gegeben" 1 "Fehlerwert" ;
VAL_ 1123 PSD_Pos_Standort_Eindeutig 0 "mehrdeutiger_Standort" 1 "eindeutiger_Standort" ;
VAL_ 1123 PSD_Pos_Fehler_Laengsrichtung 0 "Init" 1 "< 2m" 2 "< 5m" 3 "< 10m" 4 "< 20m" 5 "< 50m" 6 "> 50m" 7 "Off-Road" ;
VAL_ 1123 PSD_Pos_Fahrspur 0 "unbekannt" 1 "Erste_Spur_von_rechts" 2 "Zweite_Spur_von_rechts" 3 "Dritte_Spur_von_rechts" 4 "Vierte_Spur_von_rechts" 5 "Fuenfte_Spur_von_rechts" 6 "Sechte_Spur_von_rechts" 7 "Siebte_oder_weitere_Spur_von_rechts" ;
VAL_ 1123 PSD_Attribut_Segment_ID_05 0 "keine_Segment_Information" 1 "Fehler" ;
VAL_ 1123 PSD_Attribut_1_ID 0 "keine_Information" ;
VAL_ 1123 PSD_Attribut_2_ID 0 "keine_Information" ;
VAL_ 1123 PSD_Attribute_Komplett_05 0 "Attribute_nicht_komplett" 1 "Attribute_komplett" ;
VAL_ 1124 PSD_06_Mux 0 "Init" ;
VAL_ 1124 PSD_Sys_Segment_ID 0 "keine Segmentinformationen vorhanden" 1 "nicht zulaessig" ;
VAL_ 1124 PSD_Attribut_Segment_ID 0 "keine_Segment_Information_vorhanden" 1 "Fehler" ;
VAL_ 1124 PSD_Ges_Segment_ID 0 "keine Segmentinformationen vorhanden" 1 "nicht zulaessig" ;
VAL_ 1124 PSD_Baum_Laenge_VZ 0 "Ost" 1 "West" ;
VAL_ 1124 PSD_Steigung_1_Segment_ID 0 "keine_Segment_Information_vorhanden" 1 "Fehler" ;
VAL_ 1124 PSD_Baum_Laenge 33554431 "keine_GPS_Information" ;
VAL_ 1124 PSD_Attribut_3_ID 0 "keine_Information" ;
VAL_ 1124 PSD_Steigung_1_A_Steigung 126 "mehr_als_15_Prozent" 127 "Steigung_unbekannt" ;
VAL_ 1124 PSD_Ges_Geschwindigkeit 0 "Kein Geschwindigkeitsgebot" 1 "0 km/h < v_max <  5 km/h" 2 "5 km/h < v_max < 10km/h" 3 "10 km/h < v_max < 15 km/h" 4 "15 km/h < v_max < 20 km/h" 5 "20 km/h < v_max < 25 km/h" 6 "25 km/h < v_max < 30 km/h" 7 "30 km/h < v_max < 35 km/h" 8 "35 km/h < v_max < 40 km/h" 9 "40 km/h < v_max < 45 km/h" 10 "45 km/h < v_max < 50 km/h" 11 "50 km/h < v_max < 60 km/h" 12 "60 km/h < v_max < 70 km/h" 13 "70 km/h < v_max < 80 km/h" 14 "80 km/h < v_max < 90 km/h" 15 "90 km/h < v_max < 100 km/h" 16 "100 km/h < v_max < 110 km/h" 17 "110 km/h < v_max < 120 km/h" 18 " 120 km/h < v_max < 130 km/h" 19 "130 km/h < v_max < 140 km/h" 20 "140 km/h < v_max < 150 km/h" 21 "150 km/h < v_max < 160 km/h" 22 "160 km/h < v_max" 23 "Geschwindigkeitsgebot aufgehoben" 24 "..0x1F ungültig" ;
VAL_ 1124 PSD_Steigung_1_A_Vorz 0 "Gefaelle" 1 "Steigung" ;
VAL_ 1124 PSD_Sys_Geschwindigkeit_Einheit 0 "km/h" 1 "mph" ;
VAL_ 1124 PSD_Sys_Verkehrsrichtung 0 "Rechtsverkehr" 1 "Linksverkehr" ;
VAL_ 1124 PSD_Sys_Geometrieguete 0 "Geringe_Guete" 1 "tbd" 2 "tbd" 3 "Hohe_Guete" ;
VAL_ 1124 PSD_Sys_Mapmatchingguete 0 "geringe_Guete" 1 "res" 2 "res" 3 "hohe_Guete" ;
VAL_ 1124 PSD_Ges_Typ 0 "Geschw_Klasse_des_Kartendatensuppliers" 1 "Explizit_abgeleiteten_Begrenzung" 2 "Durch_Gesetzg_vorgeg_allgem_Gebot_fuer_uebertr_Rahmenbed" 3 "Init" ;
VAL_ 1124 PSD_Sys_Alter_Karte 0 "kleiner_1_Jahr" 1 "1_Jahr" 2 "2_Jahre" 3 "3_Jahre" 4 "4_Jahre" 5 "5_Jahre" 6 "6_Jahre" 7 "groesser_7_Jahre" ;
VAL_ 1124 PSD_Ges_Spur_Geschw_Begrenzung 0 "Gebot_fuer_alle_spuren_gueltig" ;
VAL_ 1124 PSD_Steigung_1_B_Steigung 126 "mehr_als_15_Prozent" 127 "Steigung_unbekannt" ;
VAL_ 1124 PSD_Attribut_4_ID 0 "keine_Information" ;
VAL_ 1124 PSD_Sys_Zielfuehrung 0 "Zielfuehrung nicht aktiv" 1 "Zielfuehrung aktiv" ;
VAL_ 1124 PSD_Sys_US_State 0 "kein_US_State" 1 "Alabama" 2 "Alaska" 3 "Arkansas" 4 "Arizona" 5 "California" 6 "Colorado" 7 "Conneticut" 8 "District_of_Columbia" 9 "Delaware" 10 "Florida" 11 "Georgia" 12 "Hawaii" 13 "Idaho" 14 "Illinois" 15 "Iowa" 16 "Indiana" 17 "Kansas" 18 "Kentucky" 19 "Louisiana" 20 "Massachusetts" 21 "Maryland" 22 "Maine" 23 "Michigan" 24 "Minnesota" 25 "Missouri" 26 "Mississippi" 27 "Montana" 28 "North_Carolina" 29 "North_Dakota" 30 "Nebraska" 31 "Nevada" 32 "New_Hampshire" 33 "New_Jersey" 34 "New_Mexico" 35 "New_York" 36 "Ohio" 37 "Oklahoma" 38 "Oregon" 39 "Pennsylvania" 40 "Puerto_Rico" 41 "Rhode_Island" 42 "South_Carolina" 43 "South_Dakota" 44 "Tennessee" 45 "Texas" 46 "Utah" 47 "Virginia" 48 "Virgin_Islands" 49 "Vermont" 50 "Washington" 51 "Wisconsin" 52 "West_Virginia" 53 "Wyoming" ;
VAL_ 1124 PSD_Ges_Geschwindigkeit_Gespann 0 "alle Fahrzeuge" 1 "PKW mit Gespann" 2 "LKW, Busse, etc." ;
VAL_ 1124 PSD_Baum_Breite_VZ 0 "Nord" 1 "Sued" ;
VAL_ 1124 PSD_Ges_Geschwindigkeit_Witter 0 "Witterungsunabhängig" 1 "Nässe, Regen, Niederschlag" 2 "Glätte" 3 "Nebel" ;
VAL_ 1124 PSD_Steigung_1_B_Vorz 0 "Gefaelle" 1 "Steigung" ;
VAL_ 1124 PSD_Ges_Geschwindigkeit_Tag_Anf 0 "kein Beginn definiert" 1 "Montag" 2 "Dienstag" 3 "Mittwoch" 4 "Donnerstag" 5 "Freitag" 6 "Samstag" 7 "Sonntag" ;
VAL_ 1124 PSD_Ges_Geschwindigkeit_Tag_Ende 0 "kein Ende definiert" 1 "Montag" 2 "Dienstag" 3 "Mittwoch" 4 "Donnerstag" 5 "Freitag" 6 "Samstag" 7 "Sonntag" ;
VAL_ 1124 PSD_Sys_Quali_verfuegbar 0 "Qualitaetskriterien_nicht_verfuegbar" 1 "Qualitaetskriterien_verfuegbar" ;
VAL_ 1124 PSD_Sys_Zielfuehrung_geaendert 0 "Zielfuehrung_nicht_geaendert" 1 "Zielfuehrung_geaendert" ;
VAL_ 1124 PSD_Ges_Geschwindigkeit_Std_Anf 25 "kein Beginn für stundenweise Einschränkungen" ;
VAL_ 1124 PSD_Steigung_1_Attribute_kompl 0 "Steigungen_nicht_komplett" 1 "Steigungen_komplett" ;
VAL_ 1124 PSD_Sys_Geometrieguete_erweitert 0 "Init" ;
VAL_ 1124 PSD_Steigung_2_Segment_ID 0 "keine_Segment_Information_vorhanden" 1 "Fehler" ;
VAL_ 1124 PSD_Attribut_5_ID 0 "keine_Information" ;
VAL_ 1124 PSD_Ges_Geschwindigkeit_Std_Ende 25 "kein Ende für stundenweise Einschränkungen" ;
VAL_ 1124 PSD_Steigung_2_Steigung 126 "mehr_als_15_Prozent" 127 "Steigung_unbekannt" ;
VAL_ 1124 PSD_Ges_Ueberholverbot 0 "kein Überholverbot" 1 "alle Fahrzeuge" 2 "Überholverbot für PKW mit Gespann" 3 "Überholverbot für LKW, Busse, etc." ;
VAL_ 1124 PSD_Ges_Wechselverkehrszeichen 0 "Kein Wechselverkehrszeichen" 1 "Wechselverkehrszeichen links" 2 "Wechselverkehrszeichen rechts" 3 "Wechselverkehrszeichen links und rechts" 4 "Wechselverkerhszeichen über der Fahrbahn" ;
VAL_ 1124 PSD_Steigung_2_Vorz 0 "Gefaelle" 1 "Steigung" ;
VAL_ 1124 PSD_Wechselverkehrszeichen_Typ 0 "kein_Wechselverkehrszeichen" 1 "LED_Wechselverkehrszeichen" 2 "nicht_LED_Wechselverkehrszeichen" ;
VAL_ 1124 PSD_Ges_Gesetzlich_Kategorie 0 "kein_legales_Verbot" 1 "innerorts" 2 "ausserorts" 3 "Autobahn" ;
VAL_ 1124 PSD_Attribute_Komplett_06 0 "Attribute_nicht_komplett" 1 "Attribute_komplett" ;
VAL_ 1124 PSD_Ges_Gesetzlich_Zusatz 0 "kein_Zusatz_zu_legalem_Gebot" 1 "Anhaenger_Klasse_1" 2 "Anhaenger_Klasse_2" ;
VAL_ 1124 PSD_Ges_Verkehrszeichen_Quelle 0 "VZA_kein_Onlinedienst" 1 "nur_VZA" 2 "nur_VZO" 3 "VZA_und_VZO" ;
VAL_ 1124 PSD_Steigung_2_Attribute_kompl 0 "Steigungen_nicht_komplett" 1 "Steigungen_komplett" ;
VAL_ 1124 PSD_Ges_Attribute_Komplett 0 "Attribute_nicht_komplett" 1 "Attribute_komplett" ;
VAL_ 1616 RA_Radio_Error_Flag 0 "kein_KD_Fehler" 1 "KD_Fehler" ;
VAL_ 1616 RA_Frequency_unit 0 "1_kHz" 1 "100_kHz" ;
VAL_ 1616 RA_AM_Tuning 0 "frequency_locked" 1 "AM_tuning" ;
VAL_ 695 RCTA_Anf_Warnruck 0 "Init_kein_Warnruck" 1 "schwacher_Warnruck" 2 "mittlerer_Warnruck" 3 "starker_Warnruck" ;
VAL_ 695 RCTA_Modus 0 "kein_Fehler_verfuegbar" 1 "Eingriffsmute" 2 "eingeschraenkt_Verfuegbar_pata2_Warnruck_etc" 3 "Anhaengerbetrieb" 4 "Init_nicht_codiert" 5 "keine_Sensorsicht_Blindheit" 6 "zur_Zeit_nicht_verfuegbar_temp_Fehler" 7 "Systemstoerung_dauer_Fehler" ;
VAL_ 695 RCTA_Kritikalitaetslevel_rechts 0 "unkritisch" 1 "Kritikalitaetslevel_1" 2 "Kritikalitaetslevel_2" 3 "Kritikalitaetslevel_3" 4 "Kritikalitaetslevel_4" 5 "Kritikalitaetslevel_5" 6 "reserviert" 7 "nicht_bewertbar" ;
VAL_ 695 RCTA_Kritikalitaetslevel_links 0 "unkritisch" 1 "Kritikalitaetslevel_1" 2 "Kritikalitaetslevel_2" 3 "Kritikalitaetslevel_3" 4 "Kritikalitaetslevel_4" 5 "Kritikalitaetslevel_5" 6 "reserviert" 7 "nicht_bewertbar" ;
VAL_ 695 RCTA_Info_rechts 0 "RCTA_hat_rechts_nichts_erkannt" 1 "RCTA_hat_rechts_blind_erkannt" 2 "RCTA_hat_rechts_frei_erkannt" 3 "RCTA_hat_rechts_unkritisch_erkannt" 4 "RCTA_hat_rechts_relevant_aber_unkritisch_erkannt" 5 "RCTA_hat_rechts_kritisch_erkannt" 6 "RCTA_hat_rechts_sehr_kritisch_erkannt" 7 "RCTA_meldet_rechts_Kollision_steht_bevor" ;
VAL_ 695 RCTA_Anforderung_HMS 0 "keine Anforderung" 1 "halten" 2 "parken" 3 "Halten Standby" 4 "anfahren" 5 "loesen_ueber_Rampe" ;
VAL_ 695 RCTA_Bremsruck_Anforderung 0 "nicht_angefordert" 1 "angefordert" ;
VAL_ 695 RCTA_Bremsruck_Freigabe 0 "keine_Freigabe" 1 "Freigabe" ;
VAL_ 695 RCTA_Info_links 0 "RCTA_hat_links_nichts_erkannt" 1 "RCTA_hat_links_blind_erkannt" 2 "RCTA_hat_links_frei_erkannt" 3 "RCTA_hat_links_unkritisch_erkannt" 4 "RCTA_hat_links_relevant_aber_unkritisch_erkannt" 5 "RCTA_hat_links_kritisch_erkannt" 6 "RCTA_hat_links_sehr_kritisch_erkannt" 7 "RCTA_meldet_links_Kollision_steht_bevor" ;
VAL_ 695 RCTA_Status 0 "Aus" 1 "Passiv" 2 "Aktiv" 3 "Fehler" ;
VAL_ 695 RCTA_Warnton 0 "Aus" 1 "Ein" ;
VAL_ 695 RCTA_Notbremsung_Freigabe 0 "keine_Freigabe" 1 "Freigabe" ;
VAL_ 695 RCTA_Notbremsung_Anforderung 0 "Init" 255 "Fehler" ;
VAL_ 2589283632 RDK_Reifengroesse 0 "Init" 1 "Zoll_16" 2 "Zoll_17" 3 "Zoll_18" 4 "Zoll_19" 5 "Zoll_20" 6 "Zoll_21" 7 "Zoll_22" ;
VAL_ 2589283632 RDK_Reifentyp 0 "Init" 1 "Winter" 2 "Sommer" 3 "Ganzjahresreifen" 4 "Kundenspezifisch" 5 "UHP" ;
VAL_ 2589283632 RDK_SollDruck_VA 63 "Init" ;
VAL_ 2589283632 RDK_SollDruck_HA 63 "Init" ;
VAL_ 1711 RV_Video_on 0 "Kamerabild wird nicht angezeigt" 1 "Kamerabild wird angezeigt" ;
VAL_ 1711 RV_Dark_Screen 0 "Kamerabild nicht verdunkeln" 1 "Kamerabild verdunkeln" ;
VAL_ 1711 RV_HMI_Mode 0 "Parkluecke  (Modus 1)" 1 "Parallel zur Straße (Modus 2)" 2 "reserviert" 3 "Kalibrierung (nur Diagnose)" ;
VAL_ 1711 RV_GL_side 0 "Guidelines_abgeschaltet" 1 "Guidelines_Anzeige_rechte_Seite" 2 "Guiedelines_Anzeige_linke_Seite" 3 "Guiedelines_Anzeige_beide_Seiten" ;
VAL_ 1711 RV_System_aktiv 0 "System nicht betriebsbereit" 1 "System betriebsbereit" ;
VAL_ 1711 RV_Reinigung_Anf 0 "nicht_reinigen" 1 "reinigen" ;
VAL_ 1711 RV_Settings_enabled 0 "Menu 'Einstellungen' nicht aktiviert" 1 "Menu 'Einstellungen' aktiviert" ;
VAL_ 1711 RV_Menu_Item 0 "HMI Mode als ausgewaehlt markiert" 1 "Helligkeit als ausgewaehlt markiert" 2 "Kontrast als ausgewaehlt markiert" 3 "Farbsaettigung als ausgewaehlt markiert" ;
VAL_ 1711 SV_Video_on 0 "SideView_aus_/_nicht_verbaut" 1 "SideView_an" ;
VAL_ 1711 RV_Calib_Fehler 0 "Kalibrierung_i.O." 1 "RearView_nicht_kalibriert" ;
VAL_ 1711 RV_GL_Trailer_connect 0 "Guidelines_werden_angezeigt" 1 "Guidelines_wegen_angekoppeltem_Anhänger_deaktiviert" ;
VAL_ 1711 RV_GL_Trunk_open 0 "Guidelines_werden_angezeigt" 1 "Guidelines_wegen_geöffneter_Heckklappe_deaktiviert" ;
VAL_ 1711 RV_GL_LWS_Fehler 0 "Guidelines_werden_angezeigt" 1 "Guidelines_wegen_nicht_kalibriertem_Lenkwinkelsensor_deaktiviert" ;
VAL_ 1711 ZFAS_Umfeldbeleuchtung_Anf 0 "nicht_angefordert" 1 "angefordert" ;
